VERSION ""

NS_ :

BS_:

BU_: CVC_C EPS WCBS FCAM_C ADCU_C DUMMY_ECU

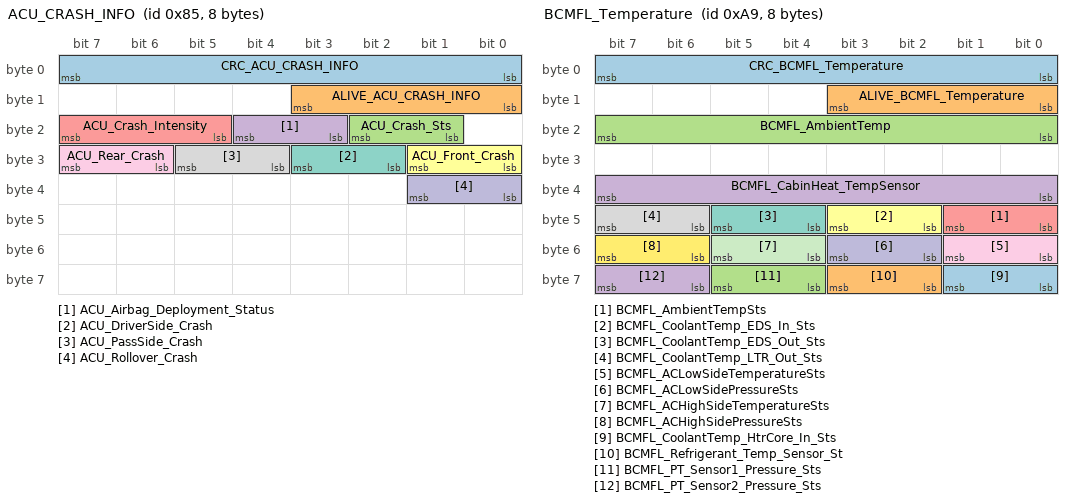
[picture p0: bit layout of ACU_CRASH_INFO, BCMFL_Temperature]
BO_ 133 ACU_CRASH_INFO: 8 CVC_C
 SG_ CRC_ACU_CRASH_INFO : 7|8@0+ (1,0) [0|255] ""  EPS,WCBS
 SG_ ALIVE_ACU_CRASH_INFO : 11|4@0+ (1,0) [0|15] ""  EPS,WCBS
 SG_ ACU_Crash_Sts : 18|2@0+ (1,0) [0|3] ""  EPS,WCBS
 SG_ ACU_Airbag_Deployment_Status : 20|2@0+ (1,0) [0|3] ""  EPS,WCBS
 SG_ ACU_Crash_Intensity : 23|3@0+ (1,0) [0|7] ""  EPS,WCBS
 SG_ ACU_Front_Crash : 25|2@0+ (1,0) [0|3] ""  EPS,WCBS
 SG_ ACU_DriverSide_Crash : 27|2@0+ (1,0) [0|3] ""  EPS,WCBS
 SG_ ACU_PassSide_Crash : 29|2@0+ (1,0) [0|3] ""  EPS,WCBS
 SG_ ACU_Rear_Crash : 31|2@0+ (1,0) [0|3] ""  EPS,WCBS
 SG_ ACU_Rollover_Crash : 33|2@0+ (1,0) [0|3] ""  EPS,WCBS

BO_ 169 BCMFL_Temperature: 8 CVC_C
 SG_ CRC_BCMFL_Temperature : 7|8@0+ (1,0) [0|255] ""  EPS,WCBS
 SG_ ALIVE_BCMFL_Temperature : 11|4@0+ (1,0) [0|15] ""  EPS,WCBS
 SG_ BCMFL_AmbientTemp : 23|8@0+ (0.5,-40) [-40|85] "Degree C"  EPS,WCBS
 SG_ BCMFL_CabinHeat_TempSensor : 39|8@0+ (0.5,-40) [-40|85] "Degree C"  EPS,WCBS
 SG_ BCMFL_AmbientTempSts : 41|2@0+ (1,0) [0|3] ""  EPS,WCBS
 SG_ BCMFL_CoolantTemp_EDS_In_Sts : 43|2@0+ (1,0) [0|3] ""  EPS,WCBS
 SG_ BCMFL_CoolantTemp_EDS_Out_Sts : 45|2@0+ (1,0) [0|3] ""  EPS,WCBS
 SG_ BCMFL_CoolantTemp_LTR_Out_Sts : 47|2@0+ (1,0) [0|3] ""  EPS,WCBS
 SG_ BCMFL_ACLowSideTemperatureSts : 49|2@0+ (1,0) [0|3] ""  EPS,WCBS
 SG_ BCMFL_ACLowSidePressureSts : 51|2@0+ (1,0) [0|3] ""  EPS,WCBS
 SG_ BCMFL_ACHighSideTemperatureSts : 53|2@0+ (1,0) [0|3] ""  EPS,WCBS
 SG_ BCMFL_ACHighSidePressureSts : 55|2@0+ (1,0) [0|3] ""  EPS,WCBS
 SG_ BCMFL_CoolantTemp_HtrCore_In_Sts : 57|2@0+ (1,0) [0|3] ""  EPS,WCBS
 SG_ BCMFL_Refrigerant_Temp_Sensor_St : 59|2@0+ (1,0) [0|3] ""  EPS,WCBS
 SG_ BCMFL_PT_Sensor1_Pressure_Sts : 61|2@0+ (1,0) [0|3] ""  EPS,WCBS
 SG_ BCMFL_PT_Sensor2_Pressure_Sts : 63|2@0+ (1,0) [0|3] ""  EPS,WCBS

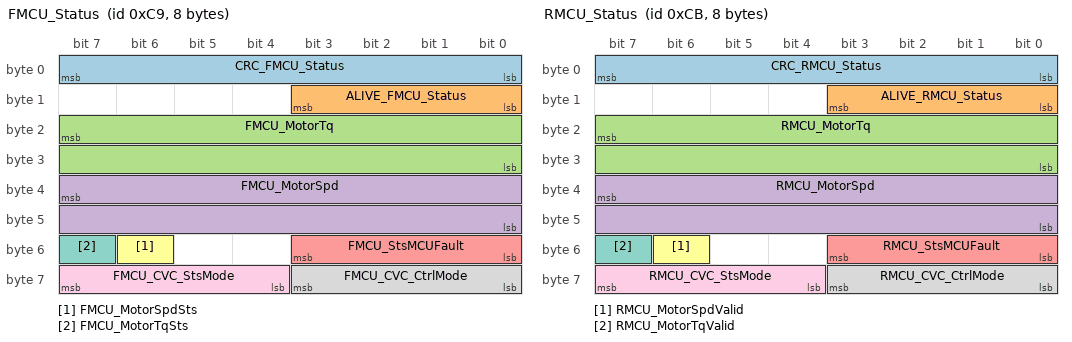
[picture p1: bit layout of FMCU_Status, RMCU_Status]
BO_ 201 FMCU_Status: 8 CVC_C
 SG_ CRC_FMCU_Status : 7|8@0+ (1,0) [0|255] ""  EPS,WCBS
 SG_ ALIVE_FMCU_Status : 11|4@0+ (1,0) [0|15] ""  EPS,WCBS
 SG_ FMCU_MotorTq : 23|16@0+ (0.1,-400) [-400|400] "Nm"  EPS,WCBS
 SG_ FMCU_MotorSpd : 39|16@0+ (1,-20000) [-20000|45531] "rpm"  EPS,WCBS
 SG_ FMCU_StsMCUFault : 51|4@0+ (1,0) [0|15] ""  EPS,WCBS
 SG_ FMCU_MotorSpdSts : 54|1@0+ (1,0) [0|1] ""  EPS,WCBS
 SG_ FMCU_MotorTqSts : 55|1@0+ (1,0) [0|1] ""  EPS,WCBS
 SG_ FMCU_CVC_CtrlMode : 59|4@0+ (1,0) [0|15] ""  EPS,WCBS
 SG_ FMCU_CVC_StsMode : 63|4@0+ (1,0) [0|15] ""  EPS,WCBS

BO_ 202 FMCU_Ability: 12 CVC_C
 SG_ CRC_FMCU_Ability : 7|8@0+ (1,0) [0|255] ""  WCBS
 SG_ ALIVE_FMCU_Ability : 11|4@0+ (1,0) [0|15] ""  WCBS
 SG_ FMCU_CVC_PosTrqLmt : 53|12@0+ (0.1,0) [0|400] ""  WCBS
 SG_ FMCU_CVC_NegTrqLmt : 57|12@0+ (0.1,-400) [-400|0] "Nm"  WCBS
 SG_ FMCU_ActInputCurrent : 31|12@0+ (0.5,-1000) [-1000|1000] "A"  WCBS
 SG_ FMCU_ActInputVolt : 35|12@0+ (0.5,0) [0|1000] "V"  WCBS
 SG_ FMCU_ActInputVoltV : 54|1@0+ (1,0) [0|1] ""  WCBS
 SG_ FMCU_ActInputCurrentV : 55|1@0+ (1,0) [0|1] ""  WCBS

BO_ 203 RMCU_Status: 8 CVC_C
 SG_ CRC_RMCU_Status : 7|8@0+ (1,0) [0|255] ""  EPS,WCBS
 SG_ ALIVE_RMCU_Status : 11|4@0+ (1,0) [0|15] ""  EPS,WCBS
 SG_ RMCU_MotorTq : 23|16@0+ (0.1,-400) [-400|400] "Nm"  EPS,WCBS
 SG_ RMCU_MotorSpd : 39|16@0+ (1,-20000) [-20000|45531] "rpm"  EPS,WCBS
 SG_ RMCU_StsMCUFault : 51|4@0+ (1,0) [0|15] ""  EPS,WCBS
 SG_ RMCU_MotorSpdValid : 54|1@0+ (1,0) [0|1] ""  EPS,WCBS
 SG_ RMCU_MotorTqValid : 55|1@0+ (1,0) [0|1] ""  EPS,WCBS
 SG_ RMCU_CVC_CtrlMode : 59|4@0+ (1,0) [0|15] ""  EPS,WCBS
 SG_ RMCU_CVC_StsMode : 63|4@0+ (1,0) [0|15] ""  EPS,WCBS

BO_ 204 RMCU_Ability: 12 CVC_C
 SG_ CRC_RMCU_Ability : 7|8@0+ (1,0) [0|255] ""  WCBS
 SG_ ALIVE_RMCU_Ability : 11|4@0+ (1,0) [0|15] ""  WCBS
 SG_ RMCU_CVC_PosTrqLmt : 53|12@0+ (0.1,0) [0|400] ""  WCBS
 SG_ RMCU_CVC_NegTrqLmt : 57|12@0+ (0.1,-400) [-400|0] "Nm"  WCBS
 SG_ RMCU_ActInputCurrent : 31|12@0+ (0.5,-1000) [-1000|1000] "A"  WCBS
 SG_ RMCU_ActInputVolt : 35|12@0+ (0.5,0) [0|1000] "V"  WCBS
 SG_ RMCU_ActInputVoltV : 54|1@0+ (1,0) [0|1] ""  WCBS
 SG_ RMCU_ActInputCurrentV : 55|1@0+ (1,0) [0|1] ""  WCBS

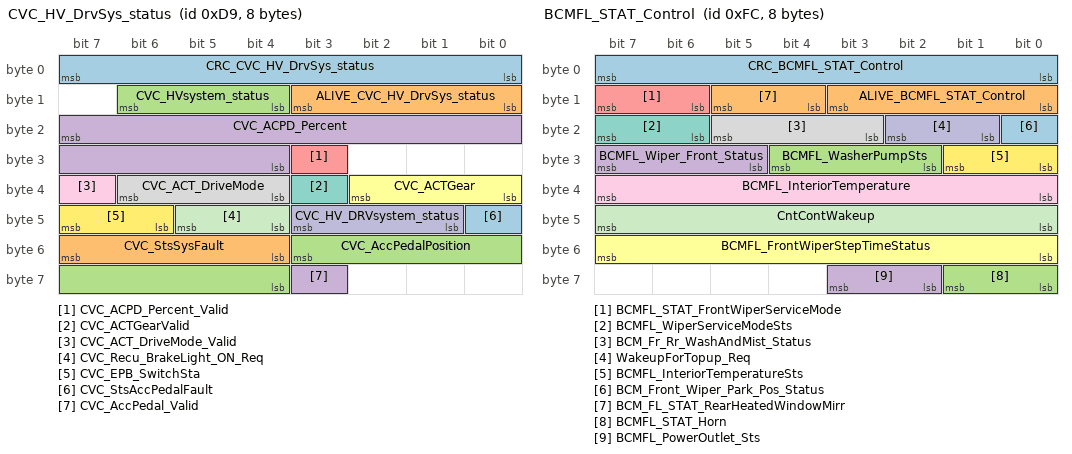
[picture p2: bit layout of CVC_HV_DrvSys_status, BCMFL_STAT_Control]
BO_ 217 CVC_HV_DrvSys_status: 8 CVC_C
 SG_ CRC_CVC_HV_DrvSys_status : 7|8@0+ (1,0) [0|255] ""  EPS,WCBS,FCAM_C,ADCU_C
 SG_ ALIVE_CVC_HV_DrvSys_status : 11|4@0+ (1,0) [0|15] ""  EPS,WCBS,FCAM_C,ADCU_C
 SG_ CVC_HVsystem_status : 14|3@0+ (1,0) [0|7] ""  EPS,WCBS,FCAM_C,ADCU_C
 SG_ CVC_ACPD_Percent : 23|12@0+ (0.0625,0) [0|100] "%"  EPS,WCBS,FCAM_C,ADCU_C
 SG_ CVC_ACPD_Percent_Valid : 27|1@0+ (1,0) [0|1] ""  EPS,WCBS,FCAM_C,ADCU_C
 SG_ CVC_ACTGear : 34|3@0+ (1,0) [0|7] ""  EPS,WCBS,FCAM_C,ADCU_C
 SG_ CVC_ACTGearValid : 35|1@0+ (1,0) [0|1] ""  EPS,WCBS,FCAM_C,ADCU_C
 SG_ CVC_ACT_DriveMode : 38|3@0+ (1,0) [0|7] ""  EPS,WCBS,FCAM_C,ADCU_C
 SG_ CVC_ACT_DriveMode_Valid : 39|1@0+ (1,0) [0|1] ""  EPS,WCBS,FCAM_C,ADCU_C
 SG_ CVC_HV_DRVsystem_status : 43|3@0+ (1,0) [0|7] ""  EPS,WCBS,FCAM_C,ADCU_C
 SG_ CVC_Recu_BrakeLight_ON_Req : 45|2@0+ (1,0) [0|3] ""  EPS,WCBS,FCAM_C,ADCU_C
 SG_ CVC_EPB_SwitchSta : 47|2@0+ (1,0) [0|3] ""  WCBS
 SG_ CVC_StsAccPedalFault : 40|1@0+ (1,0) [0|1] ""  EPS,WCBS,FCAM_C,ADCU_C
 SG_ CVC_StsSysFault : 55|4@0+ (1,0) [0|15] ""  EPS,WCBS,FCAM_C,ADCU_C
 SG_ CVC_AccPedalPosition : 51|8@0+ (0.4,0) [0|100] "%"  ADCU_C
 SG_ CVC_AccPedal_Valid : 59|1@0+ (1,0) [0|1] ""  ADCU_C

BO_ 252 BCMFL_STAT_Control: 8 CVC_C
 SG_ CRC_BCMFL_STAT_Control : 7|8@0+ (1,0) [0|255] ""  WCBS,FCAM_C,ADCU_C
 SG_ ALIVE_BCMFL_STAT_Control : 11|4@0+ (1,0) [0|15] ""  WCBS,FCAM_C,ADCU_C
 SG_ BCMFL_WasherPumpSts : 28|3@0+ (1,0) [0|3] ""  WCBS,FCAM_C,ADCU_C
 SG_ BCMFL_Wiper_Front_Status : 31|3@0+ (1,0) [0|4] ""  WCBS,FCAM_C,ADCU_C
 SG_ BCMFL_STAT_FrontWiperServiceMode : 15|2@0+ (1,0) [0|3] ""  WCBS,FCAM_C,ADCU_C
 SG_ BCMFL_FrontWiperStepTimeStatus : 55|8@0+ (1,0) [0|255] "second"  WCBS,FCAM_C,ADCU_C
 SG_ BCMFL_WiperServiceModeSts : 23|2@0+ (1,0) [0|2] ""  WCBS,FCAM_C,ADCU_C
 SG_ BCM_Fr_Rr_WashAndMist_Status : 21|3@0+ (1,0) [0|7] ""  DUMMY_ECU
 SG_ BCMFL_InteriorTemperature : 39|8@0+ (1,-40) [-40|85] "Degree C"  FCAM_C,ADCU_C
 SG_ WakeupForTopup_Req : 18|2@0+ (1,0) [0|3] ""  DUMMY_ECU
 SG_ CntContWakeup : 47|8@0+ (1,0) [0|255] ""  DUMMY_ECU
 SG_ BCMFL_InteriorTemperatureSts : 25|2@0+ (1,0) [0|3] ""  FCAM_C,ADCU_C
 SG_ BCM_Front_Wiper_Park_Pos_Status : 16|1@0+ (1,0) [0|1] "" Vector__XXX
 SG_ BCM_FL_STAT_RearHeatedWindowMirr : 13|2@0+ (1,0) [0|3] "" Vector__XXX
 SG_ BCMFL_STAT_Horn : 57|2@0+ (1,0) [0|3] "" Vector__XXX
 SG_ BCMFL_PowerOutlet_Sts : 59|2@0+ (1,0) [0|3] "" Vector__XXX

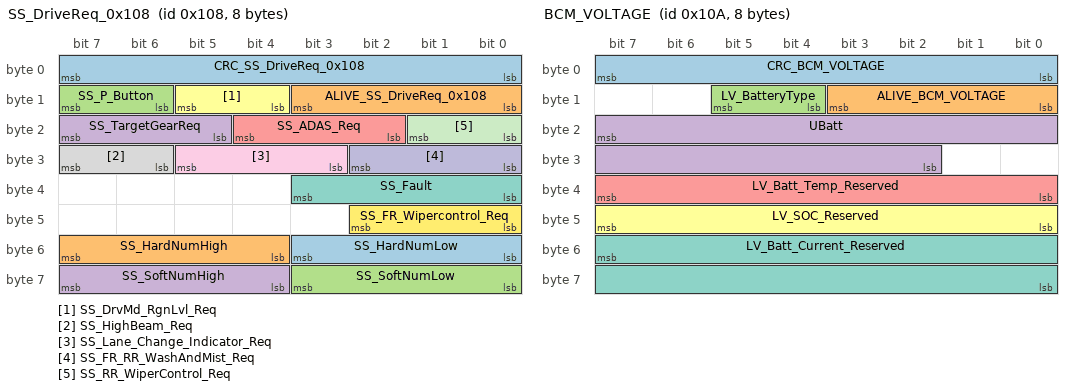
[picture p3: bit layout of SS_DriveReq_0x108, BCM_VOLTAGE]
BO_ 264 SS_DriveReq_0x108: 8 CVC_C
 SG_ CRC_SS_DriveReq_0x108 : 7|8@0+ (1,0) [0|255] ""  WCBS,FCAM_C,ADCU_C
 SG_ ALIVE_SS_DriveReq_0x108 : 11|4@0+ (1,0) [0|15] ""  WCBS,FCAM_C,ADCU_C
 SG_ SS_P_Button : 15|2@0+ (1,0) [0|3] ""  WCBS
 SG_ SS_TargetGearReq : 23|3@0+ (1,0) [0|7] ""  FCAM_C,ADCU_C
 SG_ SS_ADAS_Req : 20|3@0+ (1,0) [0|7] ""  FCAM_C,ADCU_C
 SG_ SS_DrvMd_RgnLvl_Req : 13|2@0+ (1,0) [0|3] ""  DUMMY_ECU
 SG_ SS_Fault : 35|4@0+ (1,0) [0|15] ""  WCBS,FCAM_C,ADCU_C
 SG_ SS_HighBeam_Req : 31|2@0+ (1,0) [0|3] ""  DUMMY_ECU
 SG_ SS_Lane_Change_Indicator_Req : 29|3@0+ (1,0) [0|7] ""  DUMMY_ECU
 SG_ SS_FR_RR_WashAndMist_Req : 26|3@0+ (1,0) [0|7] ""  DUMMY_ECU
 SG_ SS_RR_WiperControl_Req : 17|2@0+ (1,0) [0|3] ""  DUMMY_ECU
 SG_ SS_FR_Wipercontrol_Req : 42|3@0+ (1,0) [0|7] ""  DUMMY_ECU
 SG_ SS_HardNumLow : 51|4@0+ (1,0) [0|15] ""  DUMMY_ECU
 SG_ SS_HardNumHigh : 55|4@0+ (1,0) [0|15] ""  DUMMY_ECU
 SG_ SS_SoftNumLow : 59|4@0+ (1,0) [0|15] ""  DUMMY_ECU
 SG_ SS_SoftNumHigh : 63|4@0+ (1,0) [0|15] ""  DUMMY_ECU

BO_ 266 BCM_VOLTAGE: 8 CVC_C
 SG_ CRC_BCM_VOLTAGE : 7|8@0+ (1,0) [0|255] ""  EPS,WCBS,ADCU_C
 SG_ ALIVE_BCM_VOLTAGE : 11|4@0+ (1,0) [0|15] ""  EPS,WCBS,ADCU_C
 SG_ LV_BatteryType : 13|2@0+ (1,0) [0|3] ""  EPS,WCBS,ADCU_C
 SG_ UBatt : 23|14@0+ (0.0009777,3) [3|18] "V"  EPS,WCBS,ADCU_C
 SG_ LV_Batt_Temp_Reserved : 39|8@0+ (1,-40) [-40|105] "Degree C"  EPS,WCBS,ADCU_C
 SG_ LV_SOC_Reserved : 47|8@0+ (1,0) [0|100] "%"  EPS,WCBS,ADCU_C
 SG_ LV_Batt_Current_Reserved : 55|16@0+ (0.03125,-1536) [-1536|511.90625] "A"  EPS,WCBS,ADCU_C

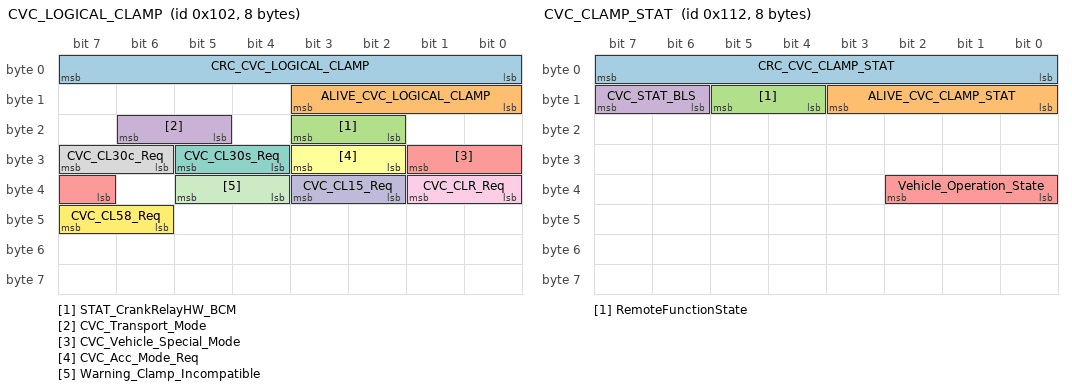
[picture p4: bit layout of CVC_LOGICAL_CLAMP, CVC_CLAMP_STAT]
BO_ 258 CVC_LOGICAL_CLAMP: 8 CVC_C
 SG_ CRC_CVC_LOGICAL_CLAMP : 7|8@0+ (1,0) [0|255] ""  WCBS,DUMMY_ECU
 SG_ ALIVE_CVC_LOGICAL_CLAMP : 11|4@0+ (1,0) [0|15] ""  WCBS,DUMMY_ECU
 SG_ STAT_CrankRelayHW_BCM : 19|2@0+ (1,0) [0|3] ""  DUMMY_ECU
 SG_ CVC_Transport_Mode : 22|2@0+ (1,0) [0|3] ""  DUMMY_ECU
 SG_ CVC_Vehicle_Special_Mode : 25|3@0+ (1,0) [0|7] ""  WCBS,DUMMY_ECU
 SG_ CVC_Acc_Mode_Req : 27|2@0+ (1,0) [0|3] ""  DUMMY_ECU
 SG_ CVC_CL30s_Req : 29|2@0+ (1,0) [0|3] ""  DUMMY_ECU
 SG_ CVC_CL30c_Req : 31|2@0+ (1,0) [0|3] ""  DUMMY_ECU
 SG_ CVC_CLR_Req : 33|2@0+ (1,0) [0|3] ""  DUMMY_ECU
 SG_ CVC_CL15_Req : 35|2@0+ (1,0) [0|3] ""  DUMMY_ECU
 SG_ Warning_Clamp_Incompatible : 37|2@0+ (1,0) [0|3] ""  DUMMY_ECU
 SG_ CVC_CL58_Req : 47|2@0+ (1,0) [0|3] ""  DUMMY_ECU

BO_ 273 CVC_WCBS01: 12 CVC_C
 SG_ CRC_CVC_WCBS01 : 7|8@0+ (1,0) [0|255] ""  WCBS
 SG_ ALIVE_CVC_WCBS01 : 11|4@0+ (1,0) [0|15] ""  WCBS
 SG_ CVC_F_RegenTrqMax : 23|12@0+ (1,-4000) [-4000|0] "Nm"  WCBS
 SG_ CVC_F_RegenTrqMaxValid : 12|1@0+ (1,0) [0|1] ""  WCBS
 SG_ CVC_R_RegenTrqMax : 27|12@0+ (1,-4000) [-4000|0] "Nm"  WCBS
 SG_ CVC_R_RegenTrqMaxValid : 13|1@0+ (1,0) [0|1] ""  WCBS
 SG_ CVC_F_BrkRegenTrqActual : 47|12@0+ (1,-4000) [-4000|0] "Nm"  WCBS
 SG_ CVC_R_BrkRegenTrqActual : 51|12@0+ (1,-4000) [-4000|0] "Nm"  WCBS
 SG_ CVC_F_BrkRegenTrqActualValid : 14|1@0+ (1,0) [0|1] ""  WCBS
 SG_ CVC_R_BrkRegenTrqActualValid : 15|1@0+ (1,0) [0|1] ""  WCBS
 SG_ CVC_OnePedalModeSts : 69|2@0+ (1,0) [0|3] ""  WCBS
 SG_ CVC_OnePedalModeEnable : 71|2@0+ (1,0) [0|3] ""  WCBS
 SG_ CVC_TargetBrkTq : 67|12@0+ (1,0) [0|4000] "Nm"  WCBS
 SG_ CVC_OnePedal_Standstill_Req : 80|1@0+ (1,0) [0|1] ""  WCBS

BO_ 274 CVC_CLAMP_STAT: 8 CVC_C
 SG_ CRC_CVC_CLAMP_STAT : 7|8@0+ (1,0) [0|255] ""  EPS,WCBS,FCAM_C,ADCU_C
 SG_ ALIVE_CVC_CLAMP_STAT : 11|4@0+ (1,0) [0|15] ""  EPS,WCBS,FCAM_C,ADCU_C
 SG_ RemoteFunctionState : 13|2@0+ (1,0) [0|3] ""  EPS,WCBS,FCAM_C,ADCU_C
 SG_ CVC_STAT_BLS : 15|2@0+ (1,0) [0|3] ""  EPS,WCBS,FCAM_C,ADCU_C
 SG_ Vehicle_Operation_State : 34|3@0+ (1,0) [0|7] ""  EPS,WCBS,FCAM_C,ADCU_C

BO_ 288 CVC_WCBS02: 12 CVC_C
 SG_ CRC_CVC_WCBS02 : 7|8@0+ (1,0) [0|255] ""  WCBS,FCAM_C,ADCU_C
 SG_ ALIVE_CVC_WCBS02 : 11|4@0+ (1,0) [0|15] ""  WCBS,FCAM_C,ADCU_C
 SG_ VrAccPos : 23|8@0+ (0.4,0) [0|100] "%"  WCBS,FCAM_C,ADCU_C
 SG_ AccPosTrq : 31|13@0+ (1,-3700) [-3700|4300] "Nm"  WCBS,FCAM_C,ADCU_C
 SG_ CVC_F_TrqCurrWhlValid : 12|1@0+ (1,0) [0|1] ""  WCBS,FCAM_C,ADCU_C
 SG_ CVC_R_TrqCurrWhlValid : 14|1@0+ (1,0) [0|1] ""  WCBS,FCAM_C,ADCU_C
 SG_ CVC_F_TrqCurrWhl : 34|13@0+ (1,-3700) [-3700|4300] "Nm"  WCBS,FCAM_C,ADCU_C
 SG_ CVC_R_TrqCurrWhl : 52|13@0+ (1,-3700) [-3700|4300] "Nm"  WCBS,FCAM_C,ADCU_C
 SG_ Driver_Accel_Pedal_Override : 71|2@0+ (1,0) [0|3] ""  WCBS,FCAM_C,ADCU_C
 SG_ CVC_F_AxleCoastRegenTorque : 67|12@0+ (1,-4000) [-4000|0] ""  WCBS,ADCU_C
 SG_ CVC_F_AxleCoastRegenTorqueValid : 68|1@0+ (1,0) [0|1] ""  WCBS,ADCU_C
 SG_ CVC_R_AxleCoastRegenTorque : 87|12@0+ (1,-4000) [-4000|0] ""  WCBS,ADCU_C
 SG_ CVC_R_AxleCoastRegenTorqueValid : 69|1@0+ (1,0) [0|1] ""  WCBS,ADCU_C

BO_ 358 CVC_Status: 12 CVC_C
 SG_ CRC_CVC_Status : 7|8@0+ (1,0) [0|255] ""  WCBS,FCAM_C,ADCU_C
 SG_ ALIVE_CVC_Status : 11|4@0+ (1,0) [0|15] ""  WCBS,FCAM_C,ADCU_C
 SG_ CVC_DriveModeSts : 18|3@0+ (1,0) [0|7] ""  WCBS,FCAM_C,ADCU_C
 SG_ CVC_DriveReady : 19|1@0+ (1,0) [0|1] ""  WCBS,FCAM_C,ADCU_C
 SG_ CVC_Fault : 22|3@0+ (1,0) [0|7] ""  WCBS,FCAM_C,ADCU_C
 SG_ CVC_VecFltInd : 23|1@0+ (1,0) [0|1] ""  WCBS,FCAM_C,ADCU_C
 SG_ CVC_Creep_Sts : 25|2@0+ (1,0) [0|3] ""  WCBS,FCAM_C,ADCU_C
 SG_ CVC_CruiseCtrlSts : 55|3@0+ (1,0) [0|7] ""  WCBS,FCAM_C,ADCU_C
 SG_ CVC_StsBrakePedalSwitch : 29|2@0+ (1,0) [0|3] ""  WCBS,FCAM_C,ADCU_C
 SG_ CVC_VehicleMode : 31|2@0+ (1,0) [0|3] ""  WCBS,FCAM_C,ADCU_C
 SG_ CVC_CruiseSetSpd : 39|8@0+ (1,0) [30|120] ""  WCBS,FCAM_C,ADCU_C
 SG_ CVC_CruiseFaultIndication : 41|2@0+ (1,0) [0|3] ""  WCBS,FCAM_C,ADCU_C
 SG_ TRMFitted : 13|2@0+ (1,0) [0|3] ""  WCBS,FCAM_C,ADCU_C
 SG_ CVC_FuelDetectionSwitchState : 43|2@0+ (1,0) [0|3] ""  WCBS,FCAM_C,ADCU_C
 SG_ CVC_FuelDetectionState : 45|2@0+ (1,0) [0|3] ""  WCBS,FCAM_C,ADCU_C
 SG_ CVC_ParkingChargeRequest : 47|2@0+ (1,0) [0|3] ""  WCBS,FCAM_C,ADCU_C
 SG_ CVC_ParkingChargeModeSet : 51|2@0+ (1,0) [0|3] ""  WCBS,FCAM_C,ADCU_C
 SG_ CVC_REX_StartTimer : 49|10@0+ (1,0) [0|1023] "s"  WCBS,FCAM_C,ADCU_C
 SG_ LV_EM_Rampup_Req : 15|2@0+ (1,0) [0|3] ""  DUMMY_ECU
 SG_ LV_PowerSupply_Status : 52|1@0+ (1,0) [0|1] ""  DUMMY_ECU
 SG_ LV_EM_OTA_Req : 27|2@0+ (1,0) [0|3] ""  DUMMY_ECU
 SG_ CVC_STAT_AirDistributionModeLH : 71|3@0+ (1,0) [0|7] ""  DUMMY_ECU
 SG_ CVC_STAT_AirDistributionModeRH : 68|3@0+ (1,0) [0|7] ""  DUMMY_ECU
 SG_ CVC_STAT_DriverOnly : 65|2@0+ (1,0) [0|3] ""  DUMMY_ECU

BO_ 524 CVC_ODO: 8 CVC_C
 SG_ CRC_CVC_ODO : 7|8@0+ (1,0) [0|255] ""  EPS,WCBS
 SG_ ALIVE_CVC_ODO : 11|4@0+ (1,0) [0|15] ""  EPS,WCBS
 SG_ CVC_Odometer : 23|20@0+ (1,0) [0|999999] "km"  EPS,WCBS
 SG_ CVC_OdometerV : 35|1@0+ (1,0) [0|1] ""  EPS,WCBS

BO_ 533 BMS_Sts: 16 CVC_C
 SG_ CRC_BMS_Sts : 7|8@0+ (1,0) [0|255] ""  WCBS
 SG_ ALIVE_BMS_Sts : 11|4@0+ (1,0) [0|15] ""  WCBS
 SG_ BMS_BatBalance_ERR : 12|1@0+ (1,0) [0|1] ""  WCBS
 SG_ BMS_Balance_STS : 13|1@0+ (1,0) [0|1] ""  WCBS
 SG_ BMS_IGN_Sts : 14|1@0+ (1,0) [0|1] ""  WCBS
 SG_ BMS_HWCrash_Sts : 15|1@0+ (1,0) [0|1] ""  WCBS
 SG_ BMS_HVIL_STS : 17|2@0+ (1,0) [0|3] ""  WCBS
 SG_ BMS_HVOnOff_STS : 19|2@0+ (1,0) [0|3] ""  WCBS
 SG_ BMS_ERR_LEV : 23|4@0+ (1,0) [0|7] ""  WCBS
 SG_ BMS_SocActual_EST : 25|10@0+ (0.1,0) [0|100] "%"  WCBS
 SG_ BMS_Sys_STS : 29|4@0+ (1,0) [0|15] ""  WCBS
 SG_ BMS_ISU_Status : 31|2@0+ (1,0) [0|3] ""  WCBS
 SG_ BMS_SOH : 47|8@0+ (0.5,0) [0|100] "%"  WCBS
 SG_ BMS_SOE : 55|8@0+ (0.5,0) [0|100] "%"  WCBS
 SG_ BMS_HV_Sts : 63|8@0+ (1,0) [0|255] ""  WCBS
 SG_ BMS_Display_SOC : 71|10@0+ (0.1,0) [0|100] "%" Vector__XXX
 SG_ BMS_SOCE : 87|14@0+ (0.01,0) [0|100] "%" Vector__XXX

BO_ 618 CVC_HV_Status: 2 CVC_C
 SG_ CRC_CVC_HV_Status : 7|8@0+ (1,0) [0|255] ""  EPS,FCAM_C,ADCU_C
 SG_ ALIVE_CVC_HV_Status : 11|4@0+ (1,0) [0|15] ""  EPS,FCAM_C,ADCU_C
 SG_ CVC_VehicleHVStatus : 15|2@0+ (1,0) [0|3] ""  EPS,FCAM_C,ADCU_C

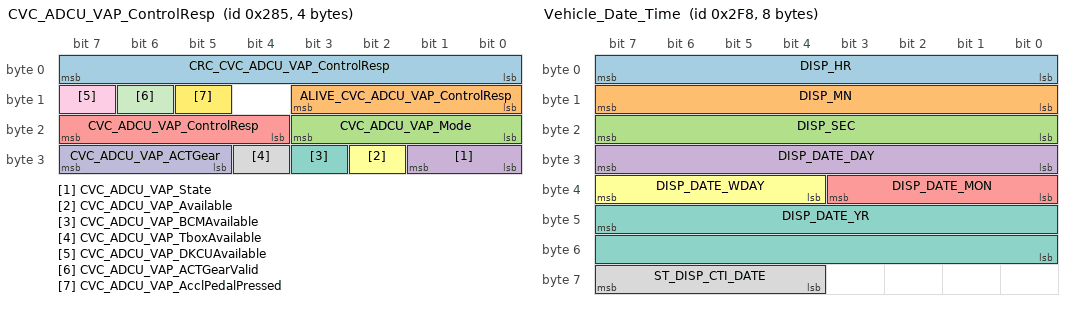
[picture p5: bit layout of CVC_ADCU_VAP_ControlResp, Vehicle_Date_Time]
BO_ 645 CVC_ADCU_VAP_ControlResp: 4 CVC_C
 SG_ CRC_CVC_ADCU_VAP_ControlResp : 7|8@0+ (1,0) [0|255] ""  ADCU_C
 SG_ ALIVE_CVC_ADCU_VAP_ControlResp : 11|4@0+ (1,0) [0|15] ""  ADCU_C
 SG_ CVC_ADCU_VAP_Mode : 19|4@0+ (1,0) [0|15] ""  ADCU_C
 SG_ CVC_ADCU_VAP_State : 25|2@0+ (1,0) [0|3] ""  ADCU_C
 SG_ CVC_ADCU_VAP_ControlResp : 23|4@0+ (1,0) [0|15] ""  ADCU_C
 SG_ CVC_ADCU_VAP_Available : 26|1@0+ (1,0) [0|1] ""  ADCU_C
 SG_ CVC_ADCU_VAP_BCMAvailable : 27|1@0+ (1,0) [0|1] ""  ADCU_C
 SG_ CVC_ADCU_VAP_TboxAvailable : 28|1@0+ (1,0) [0|1] ""  ADCU_C
 SG_ CVC_ADCU_VAP_DKCUAvailable : 15|1@0+ (1,0) [0|1] ""  ADCU_C
 SG_ CVC_ADCU_VAP_ACTGear : 31|3@0+ (1,0) [0|7] ""  ADCU_C
 SG_ CVC_ADCU_VAP_ACTGearValid : 14|1@0+ (1,0) [0|1] ""  ADCU_C
 SG_ CVC_ADCU_VAP_AcclPedalPressed : 13|1@0+ (1,0) [0|1] ""  ADCU_C

BO_ 760 Vehicle_Date_Time: 8 CVC_C
 SG_ DISP_HR : 7|8@0+ (1,0) [0|23] "h"  EPS,WCBS
 SG_ DISP_MN : 15|8@0+ (1,0) [0|59] "min"  EPS,WCBS
 SG_ DISP_SEC : 23|8@0+ (1,0) [0|59] "s"  EPS,WCBS
 SG_ DISP_DATE_DAY : 31|8@0+ (1,0) [1|31] "Day"  EPS,WCBS
 SG_ DISP_DATE_MON : 35|4@0+ (1,0) [1|12] "Month"  EPS,WCBS
 SG_ DISP_DATE_WDAY : 39|4@0+ (1,0) [0|15] ""  EPS,WCBS
 SG_ DISP_DATE_YR : 47|16@0+ (1,0) [1|65534] "Year"  EPS,WCBS
 SG_ ST_DISP_CTI_DATE : 63|4@0+ (1,0) [0|15] ""  EPS,WCBS

BO_ 788 MHU_RAEB: 24 CVC_C
 SG_ CRC_MHU_RAEB : 7|8@0+ (1,0) [0|255] ""  WCBS
 SG_ ALIVE_MHU_RAEB : 11|4@0+ (1,0) [0|15] ""  WCBS
 SG_ MHU_RAEB_check : 15|3@0+ (1,0) [0|7] ""  WCBS
 SG_ MHU_RAEB_Warning : 30|3@0+ (1,0) [0|7] ""  WCBS
 SG_ MHU_RAEB_State : 27|4@0+ (1,0) [0|15] ""  WCBS
 SG_ MHU_RAEB_BrakeCommand : 23|3@0+ (1,0) [0|3] ""  WCBS
 SG_ MHU_RAEB_Available : 17|2@0+ (1,0) [0|3] ""  WCBS
 SG_ MHU_RAEB_FuncActive : 20|1@0+ (1,0) [0|1] ""  WCBS
 SG_ MHU_RAEB_Mode_Feed : 19|2@0+ (1,0) [0|3] ""  WCBS
 SG_ MHU_RAEB_BrakeType : 33|2@0+ (1,0) [0|3] ""  WCBS
 SG_ MHU_RAEB_PullEPBOpt : 31|1@0+ (1,0) [0|1] ""  WCBS
 SG_ Secure_ResetCnt_0x314 : 135|16@0+ (1,0) [0|65535] ""  WCBS
 SG_ Secure_MsgCnt_0x314 : 151|16@0+ (1,0) [0|65535] ""  WCBS
 SG_ Secure_MAC_0x314 : 167|32@0+ (1,0) [0|4294967295] ""  WCBS
 SG_ MHU_RAEB_BrakeReq_Source : 36|3@0+ (1,0) [0|7] ""  DUMMY_ECU

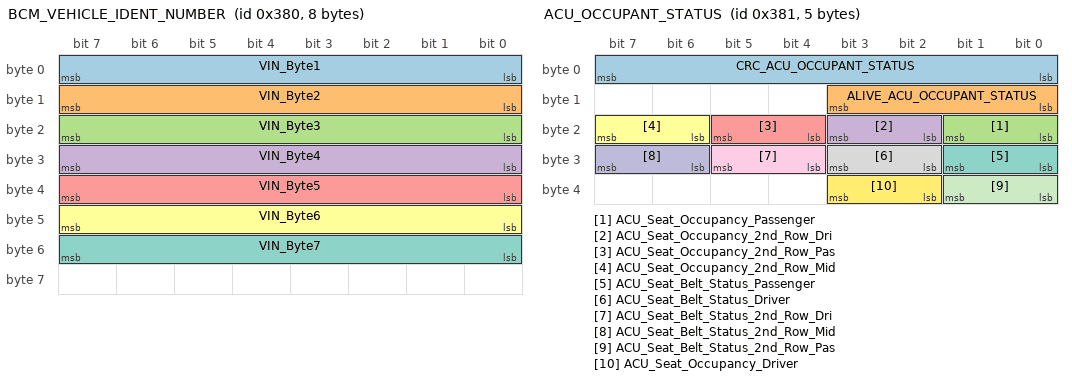
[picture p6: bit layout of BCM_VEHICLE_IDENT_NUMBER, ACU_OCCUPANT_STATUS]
BO_ 896 BCM_VEHICLE_IDENT_NUMBER: 8 CVC_C
 SG_ VIN_Byte1 : 7|8@0+ (1,0) [0|255] ""  EPS,WCBS
 SG_ VIN_Byte2 : 15|8@0+ (1,0) [0|255] ""  EPS,WCBS
 SG_ VIN_Byte3 : 23|8@0+ (1,0) [0|255] ""  EPS,WCBS
 SG_ VIN_Byte4 : 31|8@0+ (1,0) [0|255] ""  EPS,WCBS
 SG_ VIN_Byte5 : 39|8@0+ (1,0) [0|255] ""  EPS,WCBS
 SG_ VIN_Byte6 : 47|8@0+ (1,0) [0|255] ""  EPS,WCBS
 SG_ VIN_Byte7 : 55|8@0+ (1,0) [0|255] ""  EPS,WCBS

BO_ 897 ACU_OCCUPANT_STATUS: 5 CVC_C
 SG_ CRC_ACU_OCCUPANT_STATUS : 7|8@0+ (1,0) [0|255] ""  WCBS
 SG_ ALIVE_ACU_OCCUPANT_STATUS : 11|4@0+ (1,0) [0|15] ""  WCBS
 SG_ ACU_Seat_Occupancy_Passenger : 17|2@0+ (1,0) [0|3] ""  WCBS
 SG_ ACU_Seat_Occupancy_2nd_Row_Dri : 19|2@0+ (1,0) [0|3] ""  WCBS
 SG_ ACU_Seat_Occupancy_2nd_Row_Pas : 21|2@0+ (1,0) [0|3] ""  WCBS
 SG_ ACU_Seat_Occupancy_2nd_Row_Mid : 23|2@0+ (1,0) [0|3] ""  WCBS
 SG_ ACU_Seat_Belt_Status_Passenger : 25|2@0+ (1,0) [0|3] ""  WCBS
 SG_ ACU_Seat_Belt_Status_Driver : 27|2@0+ (1,0) [0|3] ""  WCBS
 SG_ ACU_Seat_Belt_Status_2nd_Row_Dri : 29|2@0+ (1,0) [0|3] ""  WCBS
 SG_ ACU_Seat_Belt_Status_2nd_Row_Mid : 31|2@0+ (1,0) [0|3] ""  WCBS
 SG_ ACU_Seat_Belt_Status_2nd_Row_Pas : 33|2@0+ (1,0) [0|3] ""  WCBS
 SG_ ACU_Seat_Occupancy_Driver : 35|2@0+ (1,0) [0|3] ""  WCBS

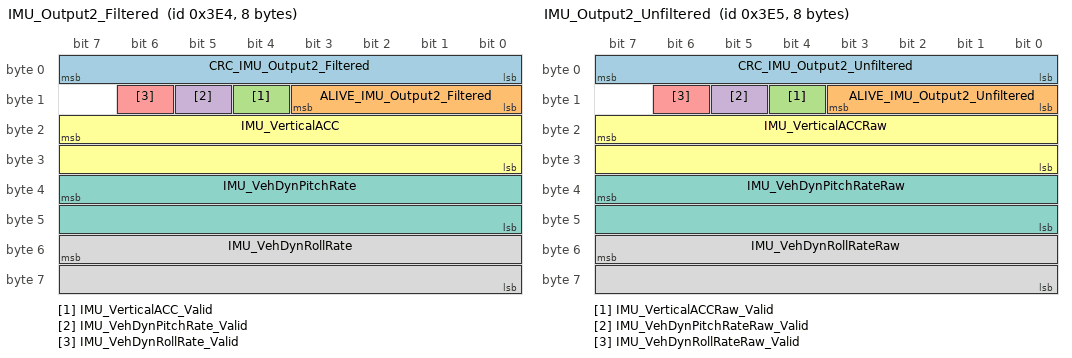
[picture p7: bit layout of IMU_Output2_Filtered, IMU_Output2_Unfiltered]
BO_ 996 IMU_Output2_Filtered: 8 CVC_C
 SG_ CRC_IMU_Output2_Filtered : 7|8@0+ (1,0) [0|255] ""  FCAM_C,ADCU_C
 SG_ ALIVE_IMU_Output2_Filtered : 11|4@0+ (1,0) [0|15] ""  FCAM_C,ADCU_C
 SG_ IMU_VerticalACC_Valid : 12|1@0+ (1,0) [0|1] ""  FCAM_C,ADCU_C
 SG_ IMU_VehDynPitchRate_Valid : 13|1@0+ (1,0) [0|1] ""  FCAM_C,ADCU_C
 SG_ IMU_VehDynRollRate_Valid : 14|1@0+ (1,0) [0|1] ""  FCAM_C,ADCU_C
 SG_ IMU_VerticalACC : 23|16@0+ (0.002,-60) [-60|60] "m/s2"  FCAM_C,ADCU_C
 SG_ IMU_VehDynPitchRate : 39|16@0+ (0.01,-300) [-300|300] "deg/s"  FCAM_C,ADCU_C
 SG_ IMU_VehDynRollRate : 55|16@0+ (0.01,-300) [-300|300] "deg/s"  FCAM_C,ADCU_C

BO_ 997 IMU_Output2_Unfiltered: 8 CVC_C
 SG_ CRC_IMU_Output2_Unfiltered : 7|8@0+ (1,0) [0|255] ""  FCAM_C,ADCU_C
 SG_ ALIVE_IMU_Output2_Unfiltered : 11|4@0+ (1,0) [0|15] ""  FCAM_C,ADCU_C
 SG_ IMU_VerticalACCRaw_Valid : 12|1@0+ (1,0) [0|1] ""  FCAM_C,ADCU_C
 SG_ IMU_VehDynPitchRateRaw_Valid : 13|1@0+ (1,0) [0|1] ""  FCAM_C,ADCU_C
 SG_ IMU_VehDynRollRateRaw_Valid : 14|1@0+ (1,0) [0|1] ""  FCAM_C,ADCU_C
 SG_ IMU_VerticalACCRaw : 23|16@0+ (0.002,-60) [-60|60] "m/s2"  FCAM_C,ADCU_C
 SG_ IMU_VehDynPitchRateRaw : 39|16@0+ (0.01,-300) [-300|300] "deg/s"  FCAM_C,ADCU_C
 SG_ IMU_VehDynRollRateRaw : 55|16@0+ (0.01,-300) [-300|300] "deg/s"  FCAM_C,ADCU_C

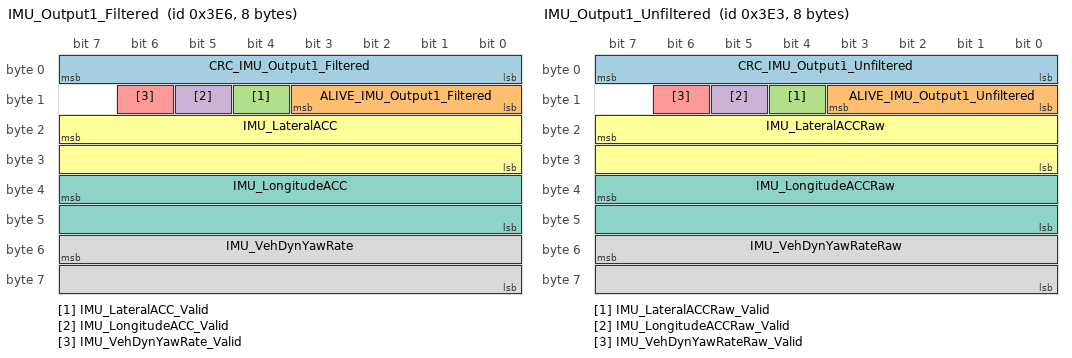
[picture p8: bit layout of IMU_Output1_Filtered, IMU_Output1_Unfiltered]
BO_ 998 IMU_Output1_Filtered: 8 CVC_C
 SG_ CRC_IMU_Output1_Filtered : 7|8@0+ (1,0) [0|255] ""  FCAM_C,ADCU_C
 SG_ ALIVE_IMU_Output1_Filtered : 11|4@0+ (1,0) [0|15] ""  FCAM_C,ADCU_C
 SG_ IMU_LateralACC_Valid : 12|1@0+ (1,0) [0|1] ""  FCAM_C,ADCU_C
 SG_ IMU_LongitudeACC_Valid : 13|1@0+ (1,0) [0|1] ""  FCAM_C,ADCU_C
 SG_ IMU_VehDynYawRate_Valid : 14|1@0+ (1,0) [0|1] ""  FCAM_C,ADCU_C
 SG_ IMU_LateralACC : 23|16@0+ (0.005,-60) [-60|60] "m/s2"  FCAM_C,ADCU_C
 SG_ IMU_LongitudeACC : 39|16@0+ (0.005,-60) [-60|60] "m/s2"  FCAM_C,ADCU_C
 SG_ IMU_VehDynYawRate : 55|16@0+ (0.02,-300) [-300|300] "deg/s"  FCAM_C,ADCU_C

BO_ 995 IMU_Output1_Unfiltered: 8 CVC_C
 SG_ CRC_IMU_Output1_Unfiltered : 7|8@0+ (1,0) [0|255] ""  FCAM_C,ADCU_C
 SG_ ALIVE_IMU_Output1_Unfiltered : 11|4@0+ (1,0) [0|15] ""  FCAM_C,ADCU_C
 SG_ IMU_LateralACCRaw_Valid : 12|1@0+ (1,0) [0|1] ""  FCAM_C,ADCU_C
 SG_ IMU_LongitudeACCRaw_Valid : 13|1@0+ (1,0) [0|1] ""  FCAM_C,ADCU_C
 SG_ IMU_VehDynYawRateRaw_Valid : 14|1@0+ (1,0) [0|1] ""  FCAM_C,ADCU_C
 SG_ IMU_LateralACCRaw : 23|16@0+ (0.002,-60) [-60|60] "m/s2"  FCAM_C,ADCU_C
 SG_ IMU_LongitudeACCRaw : 39|16@0+ (0.002,-60) [-60|60] "m/s2"  FCAM_C,ADCU_C
 SG_ IMU_VehDynYawRateRaw : 55|16@0+ (0.01,-300) [-300|300] "deg/s"  FCAM_C,ADCU_C

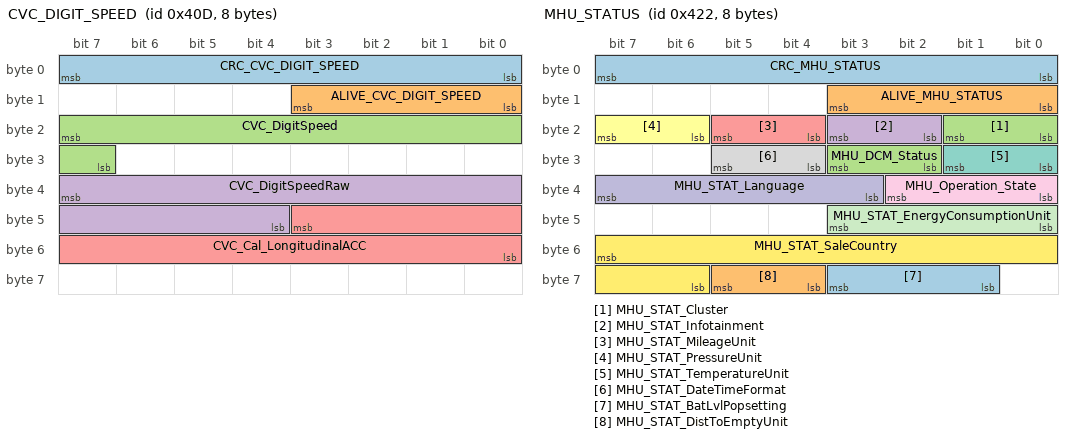
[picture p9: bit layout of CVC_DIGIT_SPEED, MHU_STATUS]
BO_ 1037 CVC_DIGIT_SPEED: 8 CVC_C
 SG_ CRC_CVC_DIGIT_SPEED : 7|8@0+ (1,0) [0|255] ""  WCBS
 SG_ ALIVE_CVC_DIGIT_SPEED : 11|4@0+ (1,0) [0|15] ""  WCBS
 SG_ CVC_DigitSpeed : 23|9@0+ (1,0) [0|300] "km/h"  WCBS
 SG_ CVC_DigitSpeedRaw : 39|12@0+ (0.1,0) [0|300] "km/h"  WCBS
 SG_ CVC_Cal_LongitudinalACC : 43|12@0+ (0.01,-20) [-20|20] "m/s2"  DUMMY_ECU

BO_ 1058 MHU_STATUS: 8 CVC_C
 SG_ CRC_MHU_STATUS : 7|8@0+ (1,0) [0|255] ""  WCBS
 SG_ ALIVE_MHU_STATUS : 11|4@0+ (1,0) [0|15] ""  WCBS
 SG_ MHU_STAT_Cluster : 17|2@0+ (1,0) [0|3] "" Vector__XXX
 SG_ MHU_STAT_Infotainment : 19|2@0+ (1,0) [0|3] "" Vector__XXX
 SG_ MHU_STAT_MileageUnit : 21|2@0+ (1,0) [0|3] ""  WCBS
 SG_ MHU_STAT_PressureUnit : 23|2@0+ (1,0) [0|3] "" Vector__XXX
 SG_ MHU_STAT_TemperatureUnit : 25|2@0+ (1,0) [0|3] "" Vector__XXX
 SG_ MHU_STAT_DateTimeFormat : 29|2@0+ (1,0) [0|3] "" Vector__XXX
 SG_ MHU_Operation_State : 34|3@0+ (1,0) [0|7] "" Vector__XXX
 SG_ MHU_STAT_Language : 39|5@0+ (1,0) [0|31] "" Vector__XXX
 SG_ MHU_STAT_EnergyConsumptionUnit : 43|4@0+ (1,0) [0|15] "" Vector__XXX
 SG_ MHU_STAT_SaleCountry : 55|10@0+ (1,0) [0|1023] "" Vector__XXX
 SG_ MHU_STAT_BatLvlPopsetting : 59|3@0+ (1,0) [0|7] "" Vector__XXX
 SG_ MHU_STAT_DistToEmptyUnit : 61|2@0+ (1,0) [0|3] "" Vector__XXX
 SG_ MHU_DCM_Status : 27|2@0+ (1,0) [0|3] "" Vector__XXX

BO_ 1082 CVC_MHU_info: 8 CVC_C
 SG_ CRC_CVC_MHU_info : 7|8@0+ (1,0) [0|255] ""  WCBS
 SG_ ALIVE_CVC_MHU_info : 11|4@0+ (1,0) [0|15] ""  WCBS
 SG_ CVC_BrakeRegenMode : 13|2@0+ (1,0) [0|3] ""  WCBS
 SG_ CVC_CreepEnable_stt : 14|1@0+ (1,0) [0|1] "" Vector__XXX
 SG_ CVC_PowerRegenGaugeDisplay : 23|8@0+ (1,-100) [-100|100] "%" Vector__XXX
 SG_ CVC_Regen_available : 31|2@0+ (1,0) [0|3] "" Vector__XXX
 SG_ CVC_StoppingMode_stt : 37|3@0+ (1,0) [0|7] "" Vector__XXX
 SG_ CVC_AutoP_Feedback : 39|2@0+ (1,0) [0|3] "" Vector__XXX
 SG_ CVC_SOC_display : 46|10@0+ (0.1,0) [0|100] "%" Vector__XXX
 SG_ CVC_Hvbatt_charging_stt : 58|1@0+ (1,0) [0|1] "" Vector__XXX
 SG_ CVC_PreheatBatt_Sts : 15|1@0+ (1,0) [0|1] ""  DUMMY_ECU
 SG_ CVC_HDC_Status : 34|3@0+ (1,0) [0|7] ""  DUMMY_ECU
 SG_ CVC_STAT_RearAircondition : 52|2@0+ (1,0) [0|3] ""  DUMMY_ECU
 SG_ CVC_STAT_AirDistributionRear : 50|2@0+ (1,0) [0|3] ""  DUMMY_ECU
 SG_ CVC_STAT_RearFanSpeed : 62|4@0+ (1,0) [0|15] ""  DUMMY_ECU
 SG_ CVC_STAT_TempRear : 29|6@0+ (0.5,16) [16|32] "degC"  DUMMY_ECU
 SG_ CVC_STAT_RearAuto : 48|2@0+ (1,0) [0|3] ""  DUMMY_ECU

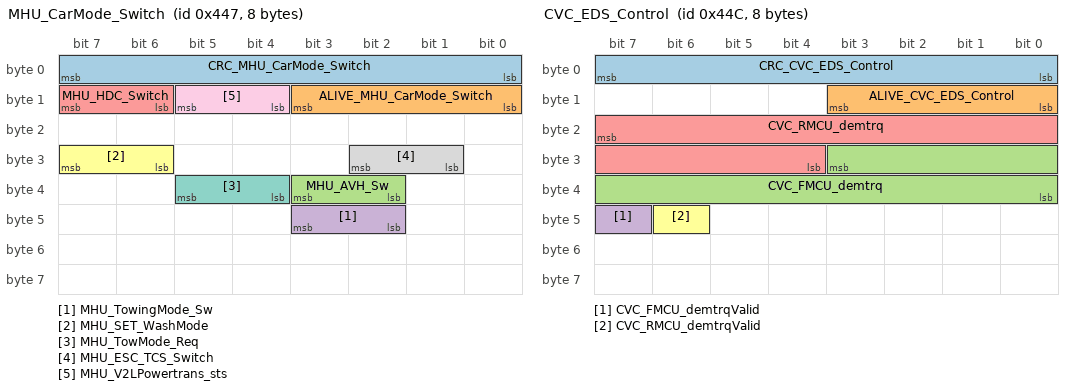
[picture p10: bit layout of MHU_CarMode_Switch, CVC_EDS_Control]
BO_ 1095 MHU_CarMode_Switch: 8 CVC_C
 SG_ CRC_MHU_CarMode_Switch : 7|8@0+ (1,0) [0|255] ""  WCBS,FCAM_C,ADCU_C
 SG_ ALIVE_MHU_CarMode_Switch : 11|4@0+ (1,0) [0|15] ""  WCBS,FCAM_C,ADCU_C
 SG_ MHU_AVH_Sw : 35|2@0+ (1,0) [0|3] ""  WCBS,FCAM_C,ADCU_C
 SG_ MHU_TowingMode_Sw : 43|2@0+ (1,0) [0|3] ""  WCBS,FCAM_C,ADCU_C
 SG_ MHU_HDC_Switch : 15|2@0+ (1,0) [0|3] ""  WCBS,FCAM_C,ADCU_C
 SG_ MHU_SET_WashMode : 31|2@0+ (1,0) [0|3] ""  FCAM_C,ADCU_C
 SG_ MHU_TowMode_Req : 37|2@0+ (1,0) [0|3] ""  WCBS,FCAM_C,ADCU_C
 SG_ MHU_ESC_TCS_Switch : 26|2@0+ (1,0) [0|3] ""  WCBS,ADCU_C
 SG_ MHU_V2LPowertrans_sts : 13|2@0+ (1,0) [0|3] ""  DUMMY_ECU

BO_ 1098 CVC_WCBS_Control: 32 CVC_C
 SG_ CRC_CVC_WCBS_Control : 7|8@0+ (1,0) [0|255] ""  WCBS,ADCU_C
 SG_ ALIVE_CVC_WCBS_Control : 11|4@0+ (1,0) [0|15] ""  WCBS,ADCU_C
 SG_ CVC_WCBS_DrvIntdTorqFr : 43|14@0+ (1,-8000) [-8000|8000] "Nm"  WCBS,ADCU_C
 SG_ CVC_WCBS_DrvIntdTorqRe : 61|14@0+ (1,-8000) [-8000|8000] "Nm"  WCBS,ADCU_C
 SG_ CVC_MaxTorq_Sts_FR : 77|2@0+ (1,0) [0|3] ""  WCBS,ADCU_C
 SG_ CVC_MinTorq_Sts_FR : 79|2@0+ (1,0) [0|3] ""  WCBS,ADCU_C
 SG_ CVC_MaxTorq_RR : 25|14@0+ (1,-8000) [-8000|8000] "Nm"  WCBS,ADCU_C
 SG_ CVC_MaxTorq_Sts_RR : 13|2@0+ (1,0) [0|3] ""  WCBS,ADCU_C
 SG_ CVC_MinTorq_RR : 23|14@0+ (1,-8000) [-8000|8000] "Nm"  WCBS,ADCU_C
 SG_ CVC_MinTorq_Sts_RR : 15|2@0+ (1,0) [0|3] ""  WCBS,ADCU_C
 SG_ CVC_WCBS_VAP_Available_Wheel_Tor : 87|14@0+ (1,-8000) [-8000|8000] "Nm"  WCBS,ADCU_C
 SG_ CVC_WCBS_VAP_ControlResp : 73|1@0+ (1,0) [0|1] ""  WCBS,ADCU_C
 SG_ CVC_WCBS_VAP_Available : 72|1@0+ (1,0) [0|1] ""  WCBS,ADCU_C
 SG_ CVC_MinTorq_FR : 103|14@0+ (1,-8000) [-8000|8000] "Nm"  WCBS,ADCU_C
 SG_ CVC_MaxTorq_FR : 119|14@0+ (1,-8000) [-8000|8000] "Nm"  WCBS,ADCU_C
 SG_ CVC_WCBS_APA_WheelTrq_Res : 89|1@0+ (1,0) [0|1] ""  WCBS,ADCU_C
 SG_ Secure_ResetCnt_0x44A : 135|16@0+ (1,0) [0|65535] ""  WCBS,ADCU_C
 SG_ Secure_MsgCnt_0x44A : 151|16@0+ (1,0) [0|65535] ""  WCBS,ADCU_C
 SG_ Secure_MAC_0x44A : 167|32@0+ (1,0) [0|4294967295] ""  WCBS,ADCU_C
 SG_ CVC_WCBS_VAP_FuncMode : 199|4@0+ (1,0) [0|15] ""  WCBS,ADCU_C

BO_ 1100 CVC_EDS_Control: 8 CVC_C
 SG_ CRC_CVC_EDS_Control : 7|8@0+ (1,0) [0|255] ""  WCBS
 SG_ ALIVE_CVC_EDS_Control : 11|4@0+ (1,0) [0|15] ""  WCBS
 SG_ CVC_FMCU_demtrq : 27|12@0+ (0.5,-500) [-500|500] "Nm"  WCBS
 SG_ CVC_FMCU_demtrqValid : 47|1@0+ (1,0) [0|1] ""  WCBS
 SG_ CVC_RMCU_demtrq : 23|12@0+ (0.5,-500) [-500|500] "Nm"  WCBS
 SG_ CVC_RMCU_demtrqValid : 46|1@0+ (1,0) [0|1] ""  WCBS

BO_ 1118 BCM_Heater_Feedback: 4 CVC_C
 SG_ CRC_BCM_Heater_Feedback : 7|8@0+ (1,0) [0|255] ""  FCAM_C
 SG_ ALIVE_BCM_Heater_Feedback : 11|4@0+ (1,0) [0|15] ""  FCAM_C
 SG_ BCM_HeaterActivation_Feedback : 16|1@0+ (1,0) [0|1] ""  FCAM_C

BO_ 1236 CVC_DoorState: 12 CVC_C
 SG_ Body_CoverAjarStatus : 0|1@0+ (1,0) [0|1] ""  WCBS
 SG_ Body_TrunckAjarStatus : 1|1@0+ (1,0) [0|1] ""  WCBS
 SG_ Body_DriverSideDoorAjarSts : 3|2@0+ (1,0) [0|3] ""  WCBS
 SG_ Body_CodriversSideDoorAjarSts : 5|2@0+ (1,0) [0|3] ""  WCBS
 SG_ Body_RearLeftDoorAjarStatus : 7|2@0+ (1,0) [0|3] ""  WCBS
 SG_ Body_DoorLockStatusRL : 17|2@0+ (1,0) [0|3] ""  WCBS
 SG_ Body_DoorLockStatusRR : 19|2@0+ (1,0) [0|3] ""  WCBS
 SG_ Body_DoorLockStatusCodrivres : 21|2@0+ (1,0) [0|3] ""  WCBS
 SG_ Body_DoorLockStatusDrv : 23|2@0+ (1,0) [0|3] ""  WCBS
 SG_ Body_RearRightDoorAjarStatus : 25|2@0+ (1,0) [0|3] ""  WCBS
 SG_ Body_ATWS_St : 28|3@0+ (1,0) [0|7] ""  WCBS
 SG_ Body_TailGateSts : 31|3@0+ (1,0) [0|7] ""  WCBS
 SG_ Body_ETGLockStatus : 11|2@0+ (1,0) [0|3] ""  WCBS

BO_ 1968 CVC_Synchronization_Master: 8 CVC_C
 SG_ Sync_TripCnt : 7|24@0+ (1,0) [0|16777215] ""  EPS,WCBS,FCAM_C
 SG_ Sync_ResetCnt : 31|16@0+ (1,0) [0|65535] ""  EPS,WCBS,FCAM_C
 SG_ Sync_MAC : 47|24@0+ (1,0) [0|16777215] ""  EPS,WCBS,FCAM_C

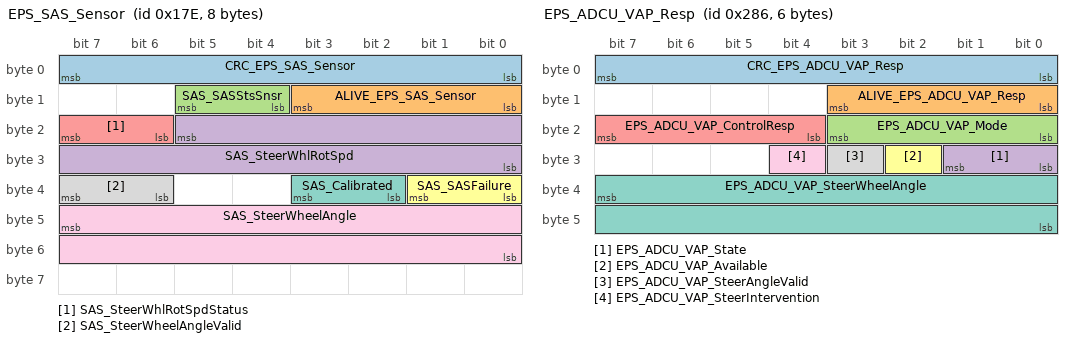
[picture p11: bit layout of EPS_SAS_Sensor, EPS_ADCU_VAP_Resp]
BO_ 382 EPS_SAS_Sensor: 8 EPS
 SG_ CRC_EPS_SAS_Sensor : 7|8@0+ (1,0) [0|255] ""  CVC_C,WCBS,FCAM_C,ADCU_C
 SG_ ALIVE_EPS_SAS_Sensor : 11|4@0+ (1,0) [0|15] ""  CVC_C,WCBS,FCAM_C,ADCU_C
 SG_ SAS_SASStsSnsr : 13|2@0+ (1,0) [0|1] ""  CVC_C,WCBS,FCAM_C,ADCU_C
 SG_ SAS_SteerWhlRotSpd : 21|14@0+ (0.125,-1024) [-1024|1023.88] "degree/s"  CVC_C,WCBS,FCAM_C,ADCU_C
 SG_ SAS_SteerWhlRotSpdStatus : 23|2@0+ (1,0) [0|1] ""  CVC_C,WCBS,FCAM_C,ADCU_C
 SG_ SAS_SASFailure : 33|2@0+ (1,0) [0|1] ""  CVC_C,WCBS,FCAM_C,ADCU_C
 SG_ SAS_Calibrated : 35|2@0+ (1,0) [0|1] ""  CVC_C,WCBS,FCAM_C,ADCU_C
 SG_ SAS_SteerWheelAngleValid : 39|2@0+ (1,0) [0|1] ""  CVC_C,WCBS,FCAM_C,ADCU_C
 SG_ SAS_SteerWheelAngle : 47|16@0+ (0.0238,-780) [-780|779.7] "deg"  CVC_C,WCBS,FCAM_C,ADCU_C

BO_ 383 EPS_FCAM_TOI: 8 EPS
 SG_ CRC_EPS_FCAM_TOI : 7|8@0+ (1,0) [0|255] ""  FCAM_C,ADCU_C
 SG_ ALIVE_EPS_FCAM_TOI : 11|4@0+ (1,0) [0|15] ""  FCAM_C,ADCU_C
 SG_ EPS_FCAM_function_feed_2 : 20|3@0+ (1,0) [0|7] ""  FCAM_C,ADCU_C
 SG_ EPS_FCAM_function_feed : 23|3@0+ (1,0) [0|7] ""  FCAM_C,ADCU_C

BO_ 646 EPS_ADCU_VAP_Resp: 6 EPS
 SG_ CRC_EPS_ADCU_VAP_Resp : 7|8@0+ (1,0) [0|255] ""  ADCU_C
 SG_ ALIVE_EPS_ADCU_VAP_Resp : 11|4@0+ (1,0) [0|15] ""  ADCU_C
 SG_ EPS_ADCU_VAP_Mode : 19|4@0+ (1,0) [0|15] ""  ADCU_C
 SG_ EPS_ADCU_VAP_State : 25|2@0+ (1,0) [0|3] ""  ADCU_C
 SG_ EPS_ADCU_VAP_ControlResp : 23|4@0+ (1,0) [0|15] ""  ADCU_C
 SG_ EPS_ADCU_VAP_Available : 26|1@0+ (1,0) [0|1] ""  ADCU_C
 SG_ EPS_ADCU_VAP_SteerWheelAngle : 39|16@0+ (0.0238,-780) [-780|779.7] "deg"  ADCU_C
 SG_ EPS_ADCU_VAP_SteerAngleValid : 27|1@0+ (1,0) [0|1] ""  ADCU_C
 SG_ EPS_ADCU_VAP_SteerIntervention : 28|1@0+ (1,0) [0|1] ""  ADCU_C

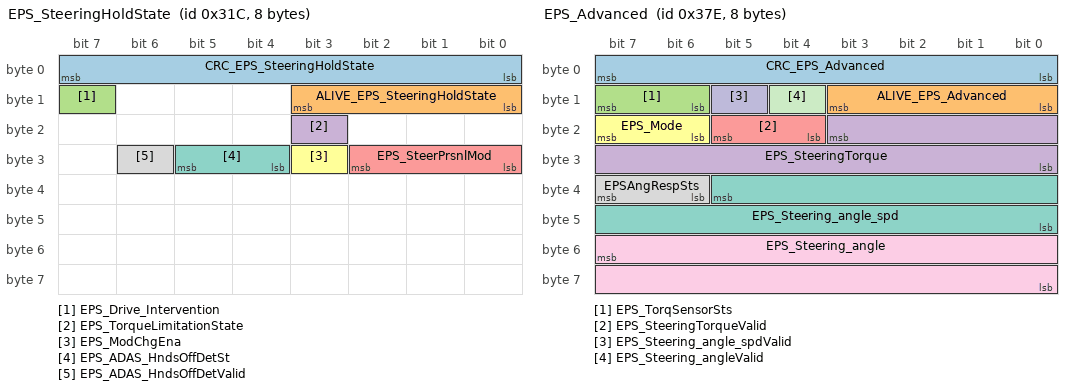
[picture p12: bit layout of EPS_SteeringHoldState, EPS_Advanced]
BO_ 796 EPS_SteeringHoldState: 8 EPS
 SG_ CRC_EPS_SteeringHoldState : 7|8@0+ (1,0) [0|255] ""  FCAM_C,ADCU_C
 SG_ ALIVE_EPS_SteeringHoldState : 11|4@0+ (1,0) [0|15] ""  FCAM_C,ADCU_C
 SG_ EPS_Drive_Intervention : 15|1@0+ (1,0) [0|1] ""  FCAM_C,ADCU_C
 SG_ EPS_TorqueLimitationState : 19|1@0+ (1,0) [0|1] ""  FCAM_C,ADCU_C
 SG_ EPS_SteerPrsnlMod : 26|3@0+ (1,0) [0|7] ""  CVC_C,FCAM_C,ADCU_C
 SG_ EPS_ModChgEna : 27|1@0+ (1,0) [0|1] ""  CVC_C,FCAM_C,ADCU_C
 SG_ EPS_ADAS_HndsOffDetSt : 29|2@0+ (1,0) [0|3] ""  FCAM_C,ADCU_C
 SG_ EPS_ADAS_HndsOffDetValid : 30|1@0+ (1,0) [0|1] ""  FCAM_C,ADCU_C

BO_ 891 EPS_FCAM_Steering_Trq: 16 EPS
 SG_ CRC_EPS_FCAM_Steering_Trq : 7|8@0+ (1,0) [0|255] ""  FCAM_C,ADCU_C
 SG_ ALIVE_EPS_FCAM_Steering_Trq : 11|4@0+ (1,0) [0|15] ""  FCAM_C,ADCU_C
 SG_ EPS_SteeringEMTorque : 34|12@0+ (0.01,-10.24) [-10.24|10.23] "Nm"  FCAM_C,ADCU_C
 SG_ EPS_FCAM_AOLAct : 15|2@0+ (1,0) [0|3] ""  FCAM_C,ADCU_C
 SG_ EPS_SteeringDriverTorque : 30|12@0+ (0.01,-10.24) [-10.24|10.23] "Nm"  FCAM_C,ADCU_C
 SG_ EPS_FCAM_Steering_Trq : 54|17@0+ (0.05,-2000) [-2000|2000] "Nm"  FCAM_C,ADCU_C
 SG_ EPS_FCAMADCUAdded_Steering_Trq : 84|17@0+ (0.05,-2000) [-2000|2000] "Nm"  FCAM_C,ADCU_C
 SG_ EPS_FCAM_TorqueBC : 69|17@0+ (0.05,-2000) [-2000|2000] "Nm"  FCAM_C,ADCU_C
 SG_ EPS_FCAM_SteeringDriverTorqueVal : 13|2@0+ (1,0) [0|3] ""  FCAM_C,ADCU_C

BO_ 894 EPS_Advanced: 8 EPS
 SG_ CRC_EPS_Advanced : 7|8@0+ (1,0) [0|255] ""  CVC_C,WCBS,FCAM_C,ADCU_C
 SG_ ALIVE_EPS_Advanced : 11|4@0+ (1,0) [0|15] ""  CVC_C,WCBS,FCAM_C,ADCU_C
 SG_ EPS_TorqSensorSts : 15|2@0+ (1,0) [0|1] ""  CVC_C,WCBS,FCAM_C,ADCU_C
 SG_ EPS_SteeringTorque : 19|12@0+ (0.5,-500) [-500|500] "Nm"  CVC_C,WCBS,FCAM_C,ADCU_C
 SG_ EPS_SteeringTorqueValid : 21|2@0+ (1,0) [0|1] ""  CVC_C,WCBS,FCAM_C,ADCU_C
 SG_ EPS_Mode : 23|2@0+ (1,0) [0|3] ""  CVC_C,WCBS,FCAM_C,ADCU_C
 SG_ EPS_Steering_angle_spd : 37|14@0+ (0.125,-1024) [-1024|1023.875] "degree/s"  CVC_C,WCBS,FCAM_C,ADCU_C
 SG_ EPSAngRespSts : 39|2@0+ (1,0) [0|3] ""  CVC_C,WCBS,FCAM_C,ADCU_C
 SG_ EPS_Steering_angle : 55|16@0+ (0.0238,-780) [-780|779.733] "deg"  CVC_C,WCBS,FCAM_C,ADCU_C
 SG_ EPS_Steering_angle_spdValid : 13|1@0+ (1,0) [0|1] ""  CVC_C,WCBS,FCAM_C,ADCU_C
 SG_ EPS_Steering_angleValid : 12|1@0+ (1,0) [0|1] ""  CVC_C,WCBS,FCAM_C,ADCU_C

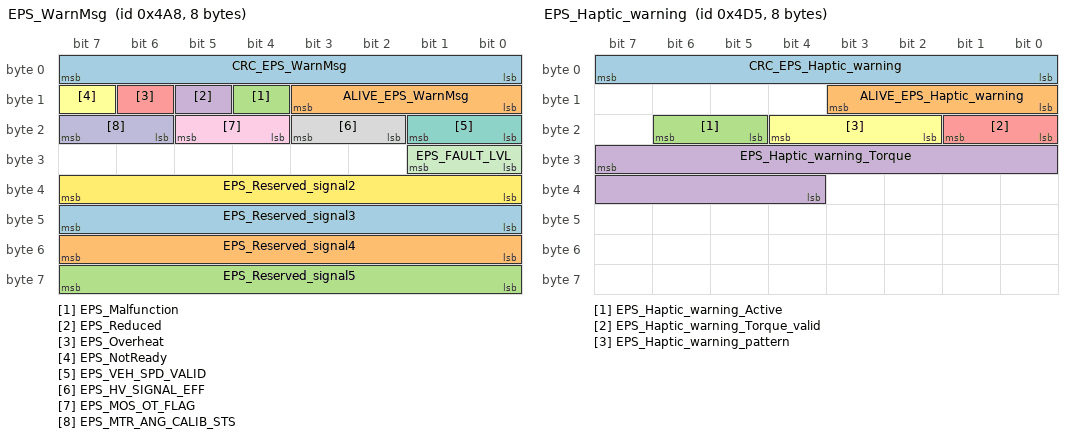
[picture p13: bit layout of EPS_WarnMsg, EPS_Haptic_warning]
BO_ 1192 EPS_WarnMsg: 8 EPS
 SG_ CRC_EPS_WarnMsg : 7|8@0+ (1,0) [0|255] ""  CVC_C,FCAM_C,ADCU_C
 SG_ ALIVE_EPS_WarnMsg : 11|4@0+ (1,0) [0|15] ""  CVC_C,FCAM_C,ADCU_C
 SG_ EPS_Malfunction : 12|1@0+ (1,0) [0|1] ""  CVC_C,FCAM_C,ADCU_C
 SG_ EPS_Reduced : 13|1@0+ (1,0) [0|1] ""  CVC_C,FCAM_C,ADCU_C
 SG_ EPS_Overheat : 14|1@0+ (1,0) [0|1] ""  CVC_C,FCAM_C,ADCU_C
 SG_ EPS_NotReady : 15|1@0+ (1,0) [0|1] ""  CVC_C,FCAM_C,ADCU_C
 SG_ EPS_VEH_SPD_VALID : 17|2@0+ (1,0) [0|3] ""  CVC_C,FCAM_C,ADCU_C
 SG_ EPS_HV_SIGNAL_EFF : 19|2@0+ (1,0) [0|3] ""  CVC_C,FCAM_C,ADCU_C
 SG_ EPS_MOS_OT_FLAG : 21|2@0+ (1,0) [0|3] ""  CVC_C,FCAM_C,ADCU_C
 SG_ EPS_MTR_ANG_CALIB_STS : 23|2@0+ (1,0) [0|3] ""  CVC_C,FCAM_C,ADCU_C
 SG_ EPS_FAULT_LVL : 25|2@0+ (1,0) [0|3] ""  CVC_C,FCAM_C,ADCU_C
 SG_ EPS_Reserved_signal2 : 39|8@0+ (1,0) [0|255] ""  CVC_C,FCAM_C,ADCU_C
 SG_ EPS_Reserved_signal3 : 47|8@0+ (1,0) [0|255] ""  CVC_C,FCAM_C,ADCU_C
 SG_ EPS_Reserved_signal4 : 55|8@0+ (1,0) [0|255] ""  CVC_C,FCAM_C,ADCU_C
 SG_ EPS_Reserved_signal5 : 63|8@0+ (1,0) [0|255] ""  CVC_C,FCAM_C,ADCU_C

BO_ 1237 EPS_Haptic_warning: 8 EPS
 SG_ CRC_EPS_Haptic_warning : 7|8@0+ (1,0) [0|255] ""  CVC_C,WCBS,FCAM_C,ADCU_C
 SG_ ALIVE_EPS_Haptic_warning : 11|4@0+ (1,0) [0|15] ""  CVC_C,WCBS,FCAM_C,ADCU_C
 SG_ EPS_Haptic_warning_Active : 22|2@0+ (1,0) [0|1] ""  CVC_C,WCBS,FCAM_C,ADCU_C
 SG_ EPS_Haptic_warning_Torque : 31|12@0+ (0.01,-10.24) [-10.24|10.23] ""  CVC_C,WCBS,FCAM_C,ADCU_C
 SG_ EPS_Haptic_warning_Torque_valid : 17|2@0+ (1,0) [0|1] ""  CVC_C,WCBS,FCAM_C,ADCU_C
 SG_ EPS_Haptic_warning_pattern : 20|3@0+ (1,0) [0|7] ""  CVC_C,WCBS,FCAM_C,ADCU_C

BO_ 1877 EPS_Function_debug_01: 32 EPS
 SG_ EPS_Return_control_Active : 121|2@0+ (1,0) [0|1] ""  CVC_C,WCBS,FCAM_C,ADCU_C
 SG_ EPS_Return_control_Torque : 43|12@0+ (0.01,-10.24) [-10.24|10.23] ""  CVC_C,WCBS,FCAM_C,ADCU_C
 SG_ EPS_Return_control_Torque_valid : 47|2@0+ (1,0) [0|1] ""  CVC_C,WCBS,FCAM_C,ADCU_C
 SG_ EPS_Damping_control_Active : 135|2@0+ (1,0) [0|1] ""  CVC_C,WCBS,FCAM_C,ADCU_C
 SG_ EPS_Damping_control_Torque : 95|12@0+ (0.01,-10.24) [-10.24|10.23] ""  CVC_C,WCBS,FCAM_C,ADCU_C
 SG_ EPS_Damping_control_Torque_valid : 61|2@0+ (1,0) [0|1] ""  CVC_C,WCBS,FCAM_C,ADCU_C
 SG_ EPS_IC_Active : 35|2@0+ (1,0) [0|1] ""  CVC_C,WCBS,FCAM_C,ADCU_C
 SG_ EPS_IC_Torque : 119|12@0+ (0.01,-10.24) [-10.24|10.23] ""  CVC_C,WCBS,FCAM_C,ADCU_C
 SG_ EPS_IC_Torque_valid : 71|2@0+ (1,0) [0|1] ""  CVC_C,WCBS,FCAM_C,ADCU_C
 SG_ EPS_Shimmy_Comp_Active : 69|2@0+ (1,0) [0|1] ""  CVC_C,WCBS,FCAM_C,ADCU_C
 SG_ EPS_Shimmy_Comp_Torque : 75|12@0+ (0.01,-10.24) [-10.24|10.23] ""  CVC_C,WCBS,FCAM_C,ADCU_C
 SG_ EPS_Shimmy_Comp_Torque_valid : 79|2@0+ (1,0) [0|1] ""  CVC_C,WCBS,FCAM_C,ADCU_C
 SG_ EPS_PDC_Active : 67|2@0+ (1,0) [0|1] ""  CVC_C,WCBS,FCAM_C,ADCU_C
 SG_ EPS_PDC_Torque : 99|12@0+ (0.01,-10.24) [-10.24|10.23] ""  CVC_C,WCBS,FCAM_C,ADCU_C
 SG_ EPS_PDC_Torque_valid : 33|2@0+ (1,0) [0|1] ""  CVC_C,WCBS,FCAM_C,ADCU_C
 SG_ EPS_Yaw_Damping_control_Active : 45|2@0+ (1,0) [0|1] ""  CVC_C,WCBS,FCAM_C,ADCU_C
 SG_ EPS_Yaw_Damping_control_Torque : 131|12@0+ (0.01,-10.24) [-10.24|10.23] ""  CVC_C,WCBS,FCAM_C,ADCU_C
 SG_ EPS_Yaw_Damping_control_valid : 65|2@0+ (1,0) [0|1] ""  CVC_C,WCBS,FCAM_C,ADCU_C
 SG_ EPS_FC_Active : 77|2@0+ (1,0) [0|1] ""  CVC_C,WCBS,FCAM_C,ADCU_C
 SG_ EPS_FC_Torque : 151|12@0+ (0.01,-10.24) [-10.24|10.23] ""  CVC_C,WCBS,FCAM_C,ADCU_C
 SG_ EPS_FC_Torque_valid : 59|2@0+ (1,0) [0|1] ""  CVC_C,WCBS,FCAM_C,ADCU_C
 SG_ EPS_OP_Active : 57|2@0+ (1,0) [0|1] ""  CVC_C,WCBS,FCAM_C,ADCU_C
 SG_ EPS_Unreduced_motor_torque_L1 : 155|12@0+ (0.01,-10.24) [-10.24|10.23] ""  CVC_C,WCBS,FCAM_C,ADCU_C
 SG_ EPS_Unreduced_motor_torque_L2 : 175|12@0+ (0.01,-10.24) [-10.24|10.23] ""  CVC_C,WCBS,FCAM_C,ADCU_C
 SG_ EPS_Reduced_motor_torque_L1 : 179|12@0+ (0.01,-10.24) [-10.24|10.23] ""  CVC_C,WCBS,FCAM_C,ADCU_C
 SG_ EPS_Reduced_motor_torque_L2 : 199|12@0+ (0.01,-10.24) [-10.24|10.23] ""  CVC_C,WCBS,FCAM_C,ADCU_C
 SG_ EPS_Max_Assist_torque_capability : 203|12@0+ (0.01,-10.24) [-10.24|10.23] ""  CVC_C,WCBS,FCAM_C,ADCU_C
 SG_ EPS_Max_Assist_torque_capab_0000 : 123|2@0+ (1,0) [0|1] ""  CVC_C,WCBS,FCAM_C,ADCU_C
 SG_ EPS_Max_Assist_torque_capab_0001 : 223|12@0+ (0.01,-10.24) [-10.24|10.23] ""  CVC_C,WCBS,FCAM_C,ADCU_C
 SG_ EPS_Max_Assist_torque_capab_0002 : 133|2@0+ (1,0) [0|1] ""  CVC_C,WCBS,FCAM_C,ADCU_C
 SG_ EPS_Operating_states : 23|3@0+ (1,0) [0|7] ""  CVC_C,WCBS,FCAM_C,ADCU_C
 SG_ EPS_TSC_Torque : 31|12@0+ (0.01,-10.24) [-10.24|10.23] "Nm"  CVC_C,WCBS,FCAM_C,ADCU_C
 SG_ EPS_TSC_Torque_valid : 63|2@0+ (1,0) [0|1] ""  CVC_C,WCBS,FCAM_C,ADCU_C
 SG_ EPS_TSC_Active : 227|2@0+ (1,0) [0|1] ""  CVC_C,WCBS,FCAM_C,ADCU_C

BO_ 1975 EPS_Synchronization_Req: 8 EPS
 SG_ EPS_Req_RandomData : 7|24@0+ (1,0) [0|16777215] ""  CVC_C
 SG_ EPS_Req_MAC : 31|40@0+ (1,0) [0|1099511627775] ""  CVC_C

BO_ 275 WCBS_ESCTrqReq: 24 WCBS
 SG_ CRC_WCBS_ESCTrqReq : 7|8@0+ (1,0) [0|255] ""  CVC_C
 SG_ ALIVE_WCBS_ESCTrqReq : 11|4@0+ (1,0) [0|15] ""  CVC_C
 SG_ WCBS_R_TrqDecReq : 12|1@0+ (1,0) [0|1] ""  CVC_C
 SG_ WCBS_R_TrqDecActive : 13|1@0+ (1,0) [0|1] ""  CVC_C
 SG_ WCBS_R_TrqIncrReq : 14|1@0+ (1,0) [0|1] ""  CVC_C
 SG_ WCBS_R_TrqIncrActive : 15|1@0+ (1,0) [0|1] ""  CVC_C
 SG_ WCBS_R_TrqDecFast : 23|16@0+ (1,-4000) [-4000|4000] "Nm"  CVC_C
 SG_ WCBS_R_TrqDecSlow : 39|8@0+ (1,0) [0|255] "Nm"  CVC_C
 SG_ WCBS_R_TrqIncrFast : 47|16@0+ (1,-4000) [-4000|4000] "Nm"  CVC_C
 SG_ WCBS_F_TrqDecFast : 59|16@0+ (1,-4000) [-4000|4000] "Nm"  CVC_C
 SG_ WCBS_F_TrqDecReq : 60|1@0+ (1,0) [0|1] ""  CVC_C
 SG_ WCBS_F_TrqDecActive : 61|1@0+ (1,0) [0|1] ""  CVC_C
 SG_ WCBS_F_TrqIncrReq : 62|1@0+ (1,0) [0|1] ""  CVC_C
 SG_ WCBS_F_TrqIncrActive : 63|1@0+ (1,0) [0|1] ""  CVC_C
 SG_ WCBS_F_TrqIncrFast : 75|16@0+ (1,-4000) [-4000|4000] "Nm"  CVC_C
 SG_ Secure_ResetCnt_0x113 : 135|16@0+ (1,0) [0|65535] ""  CVC_C
 SG_ Secure_MsgCnt_0x113 : 151|16@0+ (1,0) [0|65535] ""  CVC_C
 SG_ Secure_MAC_0x113 : 167|32@0+ (1,0) [0|4294967295] ""  CVC_C

BO_ 279 WCBS_Pressure: 16 WCBS
 SG_ CRC_WCBS_Pressure : 7|8@0+ (1,0) [0|255] ""  CVC_C,FCAM_C,ADCU_C
 SG_ ALIVE_WCBS_Pressure : 11|4@0+ (1,0) [0|15] ""  CVC_C,FCAM_C,ADCU_C
 SG_ WCBS_CircuitPress : 58|15@0+ (0.01,0) [0|327.67] "bar"  CVC_C,FCAM_C,ADCU_C
 SG_ WCBS_CircuitPressValid : 109|1@0+ (1,0) [0|1] ""  CVC_C,FCAM_C,ADCU_C
 SG_ WCBS_EstWhlPress_FL : 23|15@0+ (0.01,0) [0|327.67] "bar"  CVC_C,FCAM_C,ADCU_C
 SG_ WCBS_EstWhlPress_FR : 92|15@0+ (0.01,0) [0|327.67] "bar"  CVC_C,FCAM_C,ADCU_C
 SG_ WCBS_EstWhlPress_RL : 75|15@0+ (0.01,0) [0|327.67] "bar"  CVC_C,FCAM_C,ADCU_C
 SG_ WCBS_EstWhlPress_RR : 24|15@0+ (0.01,0) [0|327.67] "bar"  CVC_C,FCAM_C,ADCU_C
 SG_ WCBS_EstWhlPressValid : 108|1@0+ (1,0) [0|1] ""  CVC_C,FCAM_C,ADCU_C
 SG_ WCBS_MainCylinderPress : 41|15@0+ (0.01,0) [0|250] "bar"  CVC_C,FCAM_C,ADCU_C
 SG_ WCBS_MainCylinderPressValid : 107|1@0+ (1,0) [0|1] ""  CVC_C,FCAM_C,ADCU_C

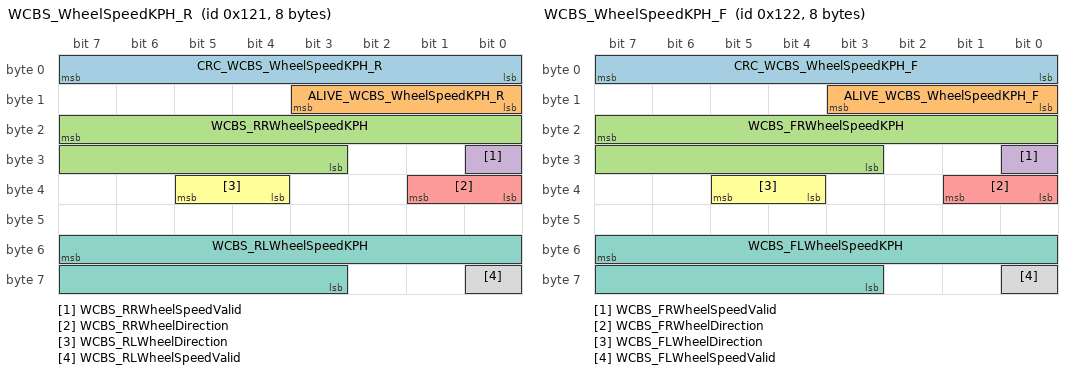
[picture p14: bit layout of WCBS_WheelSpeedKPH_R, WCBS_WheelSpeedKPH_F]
BO_ 289 WCBS_WheelSpeedKPH_R: 8 WCBS
 SG_ CRC_WCBS_WheelSpeedKPH_R : 7|8@0+ (1,0) [0|255] ""  CVC_C,FCAM_C,ADCU_C
 SG_ ALIVE_WCBS_WheelSpeedKPH_R : 11|4@0+ (1,0) [0|15] ""  CVC_C,FCAM_C,ADCU_C
 SG_ WCBS_RRWheelSpeedKPH : 23|13@0+ (0.05625,0) [0|460.6875] "Km/h"  CVC_C,FCAM_C,ADCU_C
 SG_ WCBS_RRWheelSpeedValid : 24|1@0+ (1,0) [0|1] ""  CVC_C,FCAM_C,ADCU_C
 SG_ WCBS_RRWheelDirection : 33|2@0+ (1,0) [0|3] ""  CVC_C,FCAM_C,ADCU_C
 SG_ WCBS_RLWheelDirection : 37|2@0+ (1,0) [0|3] ""  CVC_C,FCAM_C,ADCU_C
 SG_ WCBS_RLWheelSpeedKPH : 55|13@0+ (0.05625,0) [0|460.6875] "Km/h"  CVC_C,FCAM_C,ADCU_C
 SG_ WCBS_RLWheelSpeedValid : 56|1@0+ (1,0) [0|1] ""  CVC_C,FCAM_C,ADCU_C

BO_ 290 WCBS_WheelSpeedKPH_F: 8 WCBS
 SG_ CRC_WCBS_WheelSpeedKPH_F : 7|8@0+ (1,0) [0|255] ""  CVC_C,FCAM_C,ADCU_C
 SG_ ALIVE_WCBS_WheelSpeedKPH_F : 11|4@0+ (1,0) [0|15] ""  CVC_C,FCAM_C,ADCU_C
 SG_ WCBS_FRWheelSpeedKPH : 23|13@0+ (0.05625,0) [0|460.6875] "Km/h"  CVC_C,FCAM_C,ADCU_C
 SG_ WCBS_FRWheelSpeedValid : 24|1@0+ (1,0) [0|1] ""  CVC_C,FCAM_C,ADCU_C
 SG_ WCBS_FRWheelDirection : 33|2@0+ (1,0) [0|3] ""  CVC_C,FCAM_C,ADCU_C
 SG_ WCBS_FLWheelDirection : 37|2@0+ (1,0) [0|3] ""  CVC_C,FCAM_C,ADCU_C
 SG_ WCBS_FLWheelSpeedKPH : 55|13@0+ (0.05625,0) [0|460.6875] "Km/h"  CVC_C,FCAM_C,ADCU_C
 SG_ WCBS_FLWheelSpeedValid : 56|1@0+ (1,0) [0|1] ""  CVC_C,FCAM_C,ADCU_C

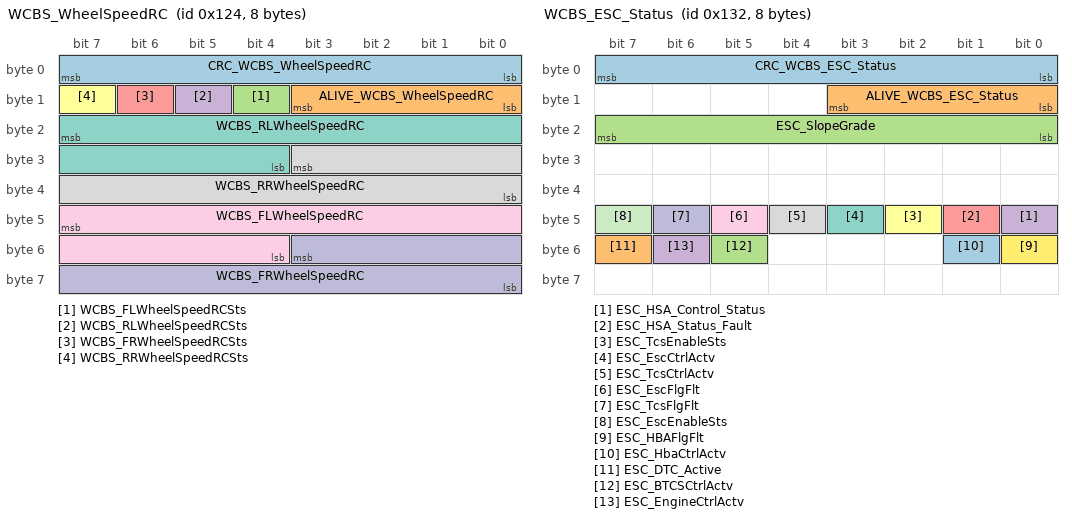
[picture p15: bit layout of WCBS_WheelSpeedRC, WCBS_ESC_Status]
BO_ 292 WCBS_WheelSpeedRC: 8 WCBS
 SG_ CRC_WCBS_WheelSpeedRC : 7|8@0+ (1,0) [0|255] ""  CVC_C,FCAM_C,ADCU_C
 SG_ ALIVE_WCBS_WheelSpeedRC : 11|4@0+ (1,0) [0|15] ""  CVC_C,FCAM_C,ADCU_C
 SG_ WCBS_FLWheelSpeedRCSts : 12|1@0+ (1,0) [0|1] ""  CVC_C,FCAM_C,ADCU_C
 SG_ WCBS_RLWheelSpeedRCSts : 13|1@0+ (1,0) [0|1] ""  CVC_C,FCAM_C,ADCU_C
 SG_ WCBS_FRWheelSpeedRCSts : 14|1@0+ (1,0) [0|1] ""  CVC_C,FCAM_C,ADCU_C
 SG_ WCBS_RRWheelSpeedRCSts : 15|1@0+ (1,0) [0|1] ""  CVC_C,FCAM_C,ADCU_C
 SG_ WCBS_RLWheelSpeedRC : 23|12@0+ (1,0) [0|4095] ""  CVC_C,FCAM_C,ADCU_C
 SG_ WCBS_RRWheelSpeedRC : 27|12@0+ (1,0) [0|4095] ""  CVC_C,FCAM_C,ADCU_C
 SG_ WCBS_FLWheelSpeedRC : 47|12@0+ (1,0) [0|4095] ""  CVC_C,FCAM_C,ADCU_C
 SG_ WCBS_FRWheelSpeedRC : 51|12@0+ (1,0) [0|4095] ""  CVC_C,FCAM_C,ADCU_C

BO_ 306 WCBS_ESC_Status: 8 WCBS
 SG_ CRC_WCBS_ESC_Status : 7|8@0+ (1,0) [0|255] ""  CVC_C,FCAM_C,ADCU_C
 SG_ ALIVE_WCBS_ESC_Status : 11|4@0+ (1,0) [0|15] ""  CVC_C,FCAM_C,ADCU_C
 SG_ ESC_SlopeGrade : 23|8@0+ (1,-30) [-30|30] "%"  CVC_C,FCAM_C,ADCU_C
 SG_ ESC_HSA_Control_Status : 40|1@0+ (1,0) [0|1] ""  CVC_C,FCAM_C,ADCU_C
 SG_ ESC_HSA_Status_Fault : 41|1@0+ (1,0) [0|1] ""  CVC_C,FCAM_C,ADCU_C
 SG_ ESC_TcsEnableSts : 42|1@0+ (1,0) [0|1] ""  CVC_C,FCAM_C,ADCU_C
 SG_ ESC_EscCtrlActv : 43|1@0+ (1,0) [0|1] ""  CVC_C,FCAM_C,ADCU_C
 SG_ ESC_TcsCtrlActv : 44|1@0+ (1,0) [0|1] ""  CVC_C,FCAM_C,ADCU_C
 SG_ ESC_EscFlgFlt : 45|1@0+ (1,0) [0|1] ""  CVC_C,FCAM_C,ADCU_C
 SG_ ESC_TcsFlgFlt : 46|1@0+ (1,0) [0|1] ""  CVC_C,FCAM_C,ADCU_C
 SG_ ESC_EscEnableSts : 47|1@0+ (1,0) [0|1] ""  CVC_C,FCAM_C,ADCU_C
 SG_ ESC_HBAFlgFlt : 48|1@0+ (1,0) [0|1] ""  CVC_C,FCAM_C,ADCU_C
 SG_ ESC_HbaCtrlActv : 49|1@0+ (1,0) [0|1] ""  CVC_C,FCAM_C,ADCU_C
 SG_ ESC_DTC_Active : 55|1@0+ (1,0) [0|1] ""  CVC_C,FCAM_C,ADCU_C
 SG_ ESC_BTCSCtrlActv : 53|1@0+ (1,0) [0|1] ""  CVC_C,FCAM_C,ADCU_C
 SG_ ESC_EngineCtrlActv : 54|1@0+ (1,0) [0|1] ""  CVC_C,FCAM_C,ADCU_C

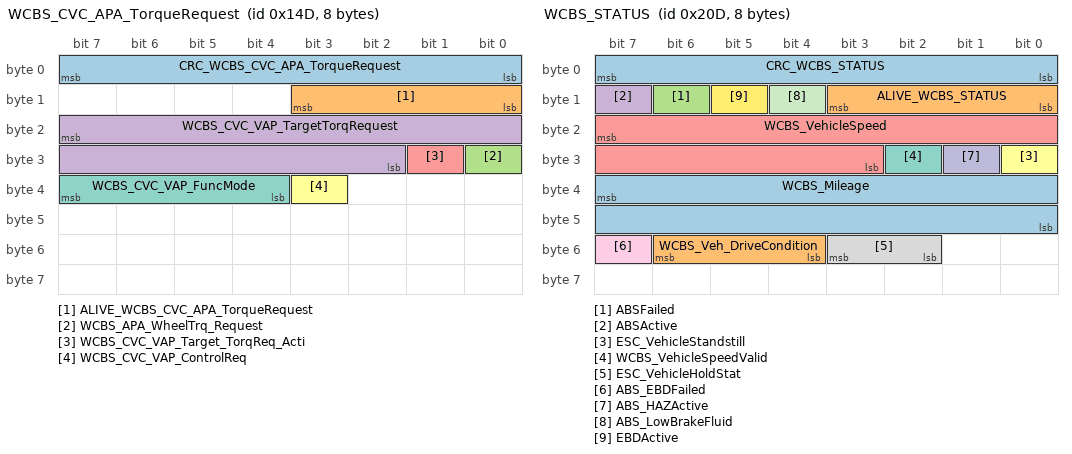
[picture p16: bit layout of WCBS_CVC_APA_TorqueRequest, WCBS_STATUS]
BO_ 333 WCBS_CVC_APA_TorqueRequest: 8 WCBS
 SG_ CRC_WCBS_CVC_APA_TorqueRequest : 7|8@0+ (1,0) [0|255] ""  CVC_C,ADCU_C
 SG_ ALIVE_WCBS_CVC_APA_TorqueRequest : 11|4@0+ (1,0) [0|15] ""  CVC_C,ADCU_C
 SG_ WCBS_APA_WheelTrq_Request : 24|1@0+ (1,0) [0|1] ""  CVC_C,ADCU_C
 SG_ WCBS_CVC_VAP_TargetTorqRequest : 23|14@0+ (1,-8000) [-8000|8000] "Nm"  CVC_C,ADCU_C
 SG_ WCBS_CVC_VAP_Target_TorqReq_Acti : 25|1@0+ (1,0) [0|1] ""  CVC_C,ADCU_C
 SG_ WCBS_CVC_VAP_ControlReq : 35|1@0+ (1,0) [0|1] ""  CVC_C,ADCU_C
 SG_ WCBS_CVC_VAP_FuncMode : 39|4@0+ (1,0) [0|15] ""  CVC_C,ADCU_C

BO_ 525 WCBS_STATUS: 8 WCBS
 SG_ CRC_WCBS_STATUS : 7|8@0+ (1,0) [0|255] ""  CVC_C,EPS,FCAM_C,ADCU_C
 SG_ ALIVE_WCBS_STATUS : 11|4@0+ (1,0) [0|15] ""  CVC_C,EPS,FCAM_C,ADCU_C
 SG_ ABSFailed : 14|1@0+ (1,0) [0|1] ""  CVC_C,FCAM_C,ADCU_C
 SG_ ABSActive : 15|1@0+ (1,0) [0|1] ""  CVC_C,FCAM_C,ADCU_C
 SG_ WCBS_VehicleSpeed : 23|13@0+ (0.05625,0) [0|300] "km/h"  CVC_C,EPS,FCAM_C,ADCU_C
 SG_ ESC_VehicleStandstill : 24|1@0+ (1,0) [0|1] ""  CVC_C,FCAM_C,ADCU_C
 SG_ WCBS_VehicleSpeedValid : 26|1@0+ (1,0) [0|1] ""  CVC_C,EPS,FCAM_C,ADCU_C
 SG_ ESC_VehicleHoldStat : 51|2@0+ (1,0) [0|3] ""  CVC_C,FCAM_C,ADCU_C
 SG_ ABS_EBDFailed : 55|1@0+ (1,0) [0|1] ""  CVC_C,FCAM_C,ADCU_C
 SG_ ABS_HAZActive : 25|1@0+ (1,0) [0|1] ""  CVC_C,FCAM_C,ADCU_C
 SG_ ABS_LowBrakeFluid : 12|1@0+ (1,0) [0|1] ""  CVC_C,FCAM_C,ADCU_C
 SG_ EBDActive : 13|1@0+ (1,0) [0|1] ""  CVC_C,FCAM_C,ADCU_C
 SG_ WCBS_Mileage : 39|16@0+ (1,0) [0|65535] "cm"  CVC_C,FCAM_C,ADCU_C
 SG_ WCBS_Veh_DriveCondition : 54|3@0+ (1,0) [0|7] ""  CVC_C,FCAM_C,ADCU_C

BO_ 560 WCBS_VAFS: 12 WCBS
 SG_ CRC_WCBS_VAFS : 7|8@0+ (1,0) [0|255] ""  CVC_C,FCAM_C,ADCU_C
 SG_ ALIVE_WCBS_VAFS : 11|4@0+ (1,0) [0|15] ""  CVC_C,FCAM_C,ADCU_C
 SG_ WCBS_BrkLampReq : 18|1@0+ (1,0) [0|1] ""  CVC_C,FCAM_C,ADCU_C
 SG_ EPB_SysWrnIndReq : 23|2@0+ (1,0) [0|2] ""  CVC_C,FCAM_C,ADCU_C
 SG_ EPB_SysStatIndReq : 25|2@0+ (1,0) [0|3] ""  CVC_C,FCAM_C,ADCU_C
 SG_ EPB_SysDspMsgReq : 30|3@0+ (1,0) [0|7] ""  CVC_C,FCAM_C,ADCU_C
 SG_ EPB_Sts : 51|3@0+ (1,0) [0|7] ""  CVC_C,FCAM_C,ADCU_C
 SG_ WCBS_TSMActive : 52|1@0+ (1,0) [0|1] ""  CVC_C,FCAM_C,ADCU_C
 SG_ EPB_CDPActive : 15|4@0+ (1,0) [0|15] ""  CVC_C,FCAM_C,ADCU_C
 SG_ EPB_Swch_Mafnc : 31|1@0+ (1,0) [0|1] ""  CVC_C,FCAM_C,ADCU_C
 SG_ WCBS_Avh_Available : 39|1@0+ (1,0) [0|1] ""  CVC_C,FCAM_C,ADCU_C
 SG_ WCBS_AVH_DispMsg : 38|3@0+ (1,0) [0|7] ""  CVC_C,FCAM_C,ADCU_C
 SG_ WCBS_AVH_Status : 35|4@0+ (1,0) [0|15] ""  CVC_C,FCAM_C,ADCU_C
 SG_ WCBS_EPB_Fault : 26|1@0+ (1,0) [0|1] ""  CVC_C,FCAM_C,ADCU_C
 SG_ WCBS_ROMActive : 27|1@0+ (1,0) [0|1] ""  CVC_C,FCAM_C,ADCU_C
 SG_ WCBS_ROMFailure : 17|1@0+ (1,0) [0|1] ""  CVC_C,FCAM_C,ADCU_C
 SG_ WCBS_TrailerDetected : 16|1@0+ (1,0) [0|1] ""  CVC_C,FCAM_C,ADCU_C
 SG_ WCBS_TSMFailure : 53|1@0+ (1,0) [0|1] ""  CVC_C,FCAM_C,ADCU_C
 SG_ WCBS_OnePedalAvailable : 48|1@0+ (1,0) [0|1] ""  CVC_C,ADCU_C
 SG_ WCBS_BrkFricTqTotAtWhls : 63|14@0+ (1,0) [0|15000] "Nm"  CVC_C,ADCU_C
 SG_ WCBS_HDCCtrlsts : 21|2@0+ (1,0) [0|3] ""  CVC_C,FCAM_C,ADCU_C
 SG_ WCBS_HDC_displayWarnMsg : 55|2@0+ (1,0) [0|3] ""  CVC_C,FCAM_C,ADCU_C
 SG_ WCBS_VehicleSteerSts : 47|2@0+ (1,0) [0|3] ""  CVC_C,FCAM_C,ADCU_C
 SG_ WCBS_HDC_available : 19|1@0+ (1,0) [0|1] ""  CVC_C,FCAM_C,ADCU_C
 SG_ WCBS_HDC_SwitchSts : 42|1@0+ (1,0) [0|1] ""  CVC_C,FCAM_C,ADCU_C
 SG_ WCBS_DTCFailure : 41|1@0+ (1,0) [0|1] ""  CVC_C,FCAM_C,ADCU_C
 SG_ WCBS_TowMode_Feedback : 65|2@0+ (1,0) [0|3] ""  CVC_C,FCAM_C,ADCU_C
 SG_ WCBS_SCM_available : 73|1@0+ (1,0) [0|1] ""  CVC_C
 SG_ WCBS_OnePedal_Active : 74|1@0+ (1,0) [0|1] ""  CVC_C,ADCU_C
 SG_ WCBS_OnePedal_hold_state : 75|1@0+ (1,0) [0|1] ""  CVC_C,ADCU_C
 SG_ WCBS_SCMActive : 77|1@0+ (1,0) [0|1] ""  CVC_C,ADCU_C
 SG_ WCBS_CDPFailSts : 76|1@0+ (1,0) [0|1] ""  CVC_C,ADCU_C
 SG_ WCBS_CBC_Active : 78|1@0+ (1,0) [0|1] ""  CVC_C
 SG_ WCBS_CBC_Available : 79|1@0+ (1,0) [0|1] ""  CVC_C
 SG_ WCBS_SLS_Active : 80|1@0+ (1,0) [0|1] ""  CVC_C
 SG_ WCBS_SLS_Available : 81|1@0+ (1,0) [0|1] ""  CVC_C
 SG_ WCBS_TVBB_Active : 82|1@0+ (1,0) [0|1] ""  CVC_C
 SG_ WCBS_TVBB_Available : 83|1@0+ (1,0) [0|1] ""  CVC_C
 SG_ WCBS_BDW_Active : 84|1@0+ (1,0) [0|1] ""  CVC_C
 SG_ WCBS_BDW_Available : 85|1@0+ (1,0) [0|1] ""  CVC_C

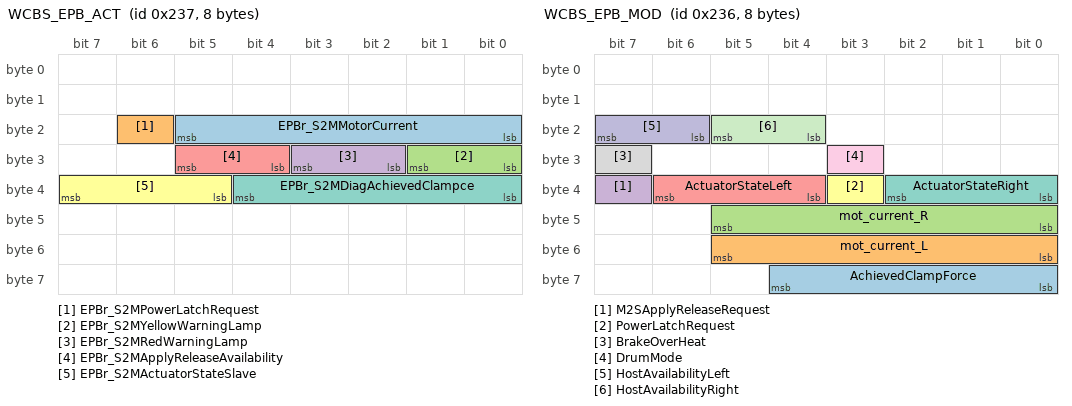
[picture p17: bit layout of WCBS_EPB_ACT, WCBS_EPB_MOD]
BO_ 567 WCBS_EPB_ACT: 8 WCBS
 SG_ EPBr_S2MMotorCurrent : 21|6@0+ (1,0) [0|63] "A"  CVC_C
 SG_ EPBr_S2MPowerLatchRequest : 22|1@0+ (1,0) [0|1] ""  CVC_C
 SG_ EPBr_S2MYellowWarningLamp : 25|2@0+ (1,0) [0|2] ""  CVC_C
 SG_ EPBr_S2MRedWarningLamp : 27|2@0+ (1,0) [0|2] ""  CVC_C
 SG_ EPBr_S2MApplyReleaseAvailability : 29|2@0+ (1,0) [0|3] ""  CVC_C
 SG_ EPBr_S2MActuatorStateSlave : 39|3@0+ (1,0) [0|7] ""  CVC_C
 SG_ EPBr_S2MDiagAchievedClampce : 36|5@0+ (1,0) [0|31] "KN"  CVC_C

BO_ 566 WCBS_EPB_MOD: 8 WCBS
 SG_ AchievedClampForce : 60|5@0+ (1,0) [0|31] "KN"  CVC_C
 SG_ mot_current_L : 53|6@0+ (1,0) [0|63] "A"  CVC_C
 SG_ mot_current_R : 45|6@0+ (1,0) [0|63] "A"  CVC_C
 SG_ M2SApplyReleaseRequest : 39|1@0+ (1,0) [0|1] ""  CVC_C
 SG_ ActuatorStateLeft : 38|3@0+ (1,0) [0|7] ""  CVC_C
 SG_ PowerLatchRequest : 35|1@0+ (1,0) [0|0] ""  CVC_C
 SG_ ActuatorStateRight : 34|3@0+ (1,0) [0|7] ""  CVC_C
 SG_ BrakeOverHeat : 31|1@0+ (1,0) [0|1] ""  CVC_C
 SG_ DrumMode : 27|1@0+ (1,0) [0|1] ""  CVC_C
 SG_ HostAvailabilityLeft : 23|2@0+ (1,0) [0|3] ""  CVC_C
 SG_ HostAvailabilityRight : 21|2@0+ (1,0) [0|3] ""  CVC_C

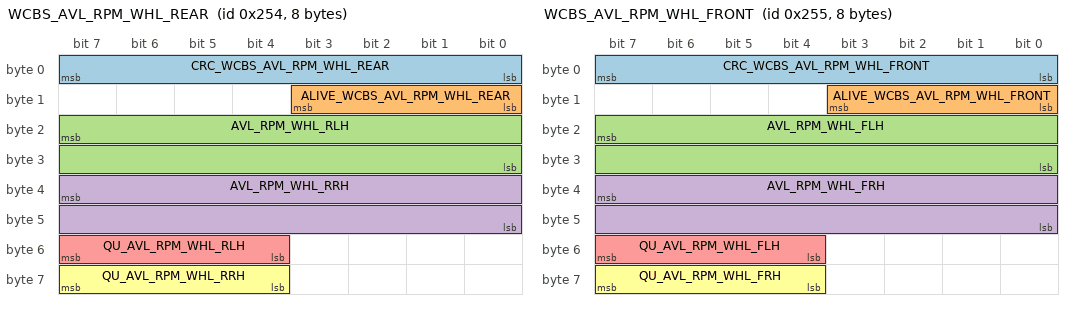
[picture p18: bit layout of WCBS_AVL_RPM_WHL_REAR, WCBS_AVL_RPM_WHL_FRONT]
BO_ 596 WCBS_AVL_RPM_WHL_REAR: 8 WCBS
 SG_ CRC_WCBS_AVL_RPM_WHL_REAR : 7|8@0+ (1,0) [0|255] ""  CVC_C,EPS,FCAM_C,ADCU_C
 SG_ ALIVE_WCBS_AVL_RPM_WHL_REAR : 11|4@0+ (1,0) [0|15] ""  CVC_C,EPS,FCAM_C,ADCU_C
 SG_ AVL_RPM_WHL_RLH : 23|16@0+ (0.0156,-511.9844) [-400|400] "rad/s"  CVC_C,EPS,FCAM_C,ADCU_C
 SG_ AVL_RPM_WHL_RRH : 39|16@0+ (0.0156,-511.9844) [-400|400] "rad/s"  CVC_C,EPS,FCAM_C,ADCU_C
 SG_ QU_AVL_RPM_WHL_RLH : 55|4@0+ (1,0) [0|15] ""  CVC_C,EPS,FCAM_C,ADCU_C
 SG_ QU_AVL_RPM_WHL_RRH : 63|4@0+ (1,0) [0|15] ""  CVC_C,EPS,FCAM_C,ADCU_C

BO_ 597 WCBS_AVL_RPM_WHL_FRONT: 8 WCBS
 SG_ CRC_WCBS_AVL_RPM_WHL_FRONT : 7|8@0+ (1,0) [0|255] ""  CVC_C,EPS,FCAM_C,ADCU_C
 SG_ ALIVE_WCBS_AVL_RPM_WHL_FRONT : 11|4@0+ (1,0) [0|15] ""  CVC_C,EPS,FCAM_C,ADCU_C
 SG_ AVL_RPM_WHL_FLH : 23|16@0+ (0.0156,-511.9844) [-400|400] "rad/s"  CVC_C,EPS,FCAM_C,ADCU_C
 SG_ AVL_RPM_WHL_FRH : 39|16@0+ (0.0156,-511.9844) [-400|400] "rad/s"  CVC_C,EPS,FCAM_C,ADCU_C
 SG_ QU_AVL_RPM_WHL_FLH : 55|4@0+ (1,0) [0|15] ""  CVC_C,EPS,FCAM_C,ADCU_C
 SG_ QU_AVL_RPM_WHL_FRH : 63|4@0+ (1,0) [0|15] ""  CVC_C,EPS,FCAM_C,ADCU_C

BO_ 624 WCBS_Info: 12 WCBS
 SG_ CRC_WCBS_Info : 7|8@0+ (1,0) [0|255] ""  CVC_C,FCAM_C,ADCU_C
 SG_ ALIVE_WCBS_Info : 11|4@0+ (1,0) [0|15] ""  CVC_C,FCAM_C,ADCU_C
 SG_ WCBS_Fault_Status : 14|3@0+ (1,0) [0|7] ""  CVC_C,FCAM_C,ADCU_C
 SG_ WCBS_IBS_Sys_Fault_Sts : 15|1@0+ (1,0) [0|1] ""  CVC_C,FCAM_C,ADCU_C
 SG_ WCBS_BrkPedalPct : 23|8@0+ (0.4,0) [0|100] "%"  CVC_C,FCAM_C,ADCU_C
 SG_ WCBS_BrkPedalTravel : 31|10@0+ (0.2,0) [0|150] "mm"  CVC_C,FCAM_C,ADCU_C
 SG_ WCBS_BrkPedalValid : 69|1@0+ (1,0) [0|1] ""  CVC_C,FCAM_C,ADCU_C
 SG_ WCBS_DiagMode : 68|1@0+ (1,0) [0|1] ""  CVC_C,FCAM_C,ADCU_C
 SG_ WCBS_RollerBenchMode : 67|1@0+ (1,0) [0|1] ""  CVC_C,FCAM_C,ADCU_C
 SG_ WCBSActive : 66|1@0+ (1,0) [0|1] ""  CVC_C,FCAM_C,ADCU_C
 SG_ WCBS_EOL_NotDone : 64|1@0+ (1,0) [0|1] ""  CVC_C,FCAM_C,ADCU_C
 SG_ STAT_DSC : 79|2@0+ (1,0) [0|3] ""  CVC_C,FCAM_C,ADCU_C
 SG_ WCBS_BLAFlt : 65|1@0+ (1,0) [0|1] ""  CVC_C,FCAM_C,ADCU_C
 SG_ FBW_WarningSts : 77|2@0+ (1,0) [0|3] ""  CVC_C,FCAM_C,ADCU_C
 SG_ Brake_Disc_Temp_FL : 35|7@0+ (10,40) [-40|800] ""  ADCU_C,DUMMY_ECU
 SG_ Brake_Disc_Temp_FR : 44|7@0+ (10,40) [-40|800] ""  ADCU_C,DUMMY_ECU
 SG_ Brake_Disc_Temp_RL : 53|7@0+ (10,40) [-40|800] ""  ADCU_C,DUMMY_ECU
 SG_ Brake_Disc_Temp_RR : 62|7@0+ (10,40) [-40|800] ""  ADCU_C,DUMMY_ECU
 SG_ WCBS_BrakesystemFailSts : 75|3@0+ (1,0) [0|7] ""  ADCU_C,DUMMY_ECU

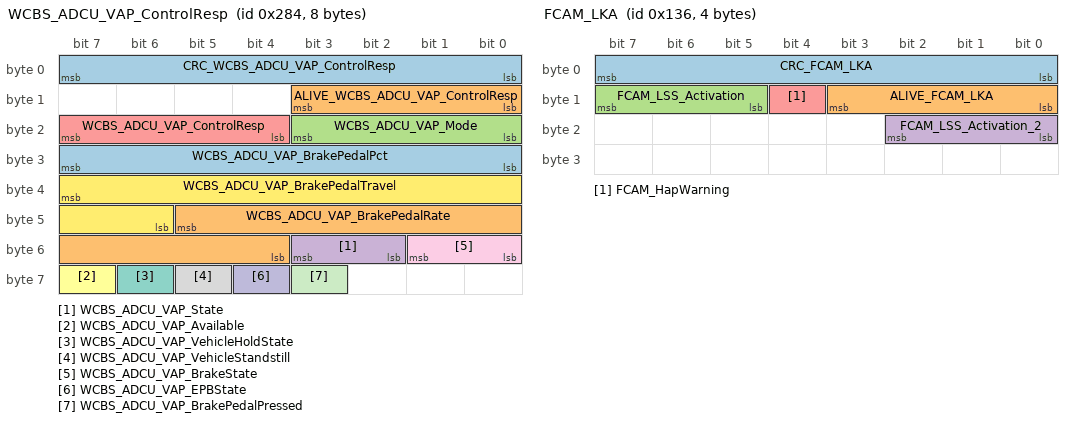
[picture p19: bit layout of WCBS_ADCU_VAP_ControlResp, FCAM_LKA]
BO_ 644 WCBS_ADCU_VAP_ControlResp: 8 WCBS
 SG_ CRC_WCBS_ADCU_VAP_ControlResp : 7|8@0+ (1,0) [0|255] ""  ADCU_C
 SG_ ALIVE_WCBS_ADCU_VAP_ControlResp : 11|4@0+ (1,0) [0|15] ""  ADCU_C
 SG_ WCBS_ADCU_VAP_Mode : 19|4@0+ (1,0) [0|15] ""  ADCU_C
 SG_ WCBS_ADCU_VAP_State : 51|2@0+ (1,0) [0|3] ""  ADCU_C
 SG_ WCBS_ADCU_VAP_ControlResp : 23|4@0+ (1,0) [0|15] ""  ADCU_C
 SG_ WCBS_ADCU_VAP_Available : 63|1@0+ (1,0) [0|1] ""  ADCU_C
 SG_ WCBS_ADCU_VAP_VehicleHoldState : 62|1@0+ (1,0) [0|1] ""  ADCU_C
 SG_ WCBS_ADCU_VAP_VehicleStandstill : 61|1@0+ (1,0) [0|1] ""  ADCU_C
 SG_ WCBS_ADCU_VAP_BrakeState : 49|2@0+ (1,0) [0|3] ""  ADCU_C
 SG_ WCBS_ADCU_VAP_EPBState : 60|1@0+ (1,0) [0|1] ""  ADCU_C
 SG_ WCBS_ADCU_VAP_BrakePedalPressed : 59|1@0+ (1,0) [0|1] ""  ADCU_C
 SG_ WCBS_ADCU_VAP_BrakePedalTravel : 39|10@0+ (0.2,0) [0|150] "mm"  ADCU_C
 SG_ WCBS_ADCU_VAP_BrakePedalPct : 31|8@0+ (0.4,0) [0|100] "%"  ADCU_C
 SG_ WCBS_ADCU_VAP_BrakePedalRate : 45|10@0+ (0.4,0) [0|300] "mm/s"  ADCU_C

BO_ 815 WCBS_ADAS_Info: 24 WCBS
 SG_ CRC_WCBS_ADAS_Info : 7|8@0+ (1,0) [0|255] ""  CVC_C,FCAM_C,ADCU_C
 SG_ ALIVE_WCBS_ADAS_Info : 11|4@0+ (1,0) [0|15] ""  CVC_C,FCAM_C,ADCU_C
 SG_ WCBS_ACC_Available_Flag : 13|1@0+ (1,0) [0|1] ""  CVC_C,FCAM_C,ADCU_C
 SG_ WCBS_ACC_Deceleration_Flag : 14|1@0+ (1,0) [0|1] ""  CVC_C,FCAM_C,ADCU_C
 SG_ WCBS_ACC_Acceleration_Flag : 15|1@0+ (1,0) [0|1] ""  CVC_C,FCAM_C,ADCU_C
 SG_ WCBS_RAEB_Active_Flag : 18|1@0+ (1,0) [0|1] ""  CVC_C,FCAM_C,ADCU_C
 SG_ WCBS_RAEB_Available_Flag : 19|1@0+ (1,0) [0|1] ""  CVC_C,FCAM_C,ADCU_C
 SG_ WCBS_AEB_Active_Flag : 20|1@0+ (1,0) [0|1] ""  CVC_C,FCAM_C,ADCU_C
 SG_ WCBS_AEB_Available_Flag : 21|1@0+ (1,0) [0|1] ""  CVC_C,FCAM_C,ADCU_C
 SG_ WCBS_ACC_DriverOverride : 23|2@0+ (1,0) [0|3] ""  CVC_C,FCAM_C,ADCU_C
 SG_ WCBS_ACC_TargetWheel_Torque : 31|16@0+ (1,-8000) [-8000|8000] "Nm"  CVC_C,FCAM_C,ADCU_C
 SG_ WCBS_ACC_WheelTrq_Active : 12|1@0+ (1,0) [0|1] ""  CVC_C,FCAM_C,ADCU_C
 SG_ WCBS_RAEB_BrakeActuator : 47|3@0+ (1,0) [0|7] ""  CVC_C,ADCU_C
 SG_ Secure_ResetCnt_0x32F : 135|16@0+ (1,0) [0|65535] ""  CVC_C,FCAM_C,ADCU_C
 SG_ Secure_MsgCnt_0x32F : 151|16@0+ (1,0) [0|65535] ""  CVC_C,FCAM_C,ADCU_C
 SG_ Secure_MAC_0x32F : 167|32@0+ (1,0) [0|4294967295] ""  CVC_C,FCAM_C,ADCU_C

BO_ 866 WCBS_RecuBrkTrqReq: 24 WCBS
 SG_ CRC_WCBS_RecuBrkTrqReq : 7|8@0+ (1,0) [0|255] ""  CVC_C
 SG_ ALIVE_WCBS_RecuBrkTrqReq : 11|4@0+ (1,0) [0|15] ""  CVC_C
 SG_ WCBS_RBC_STS : 12|1@0+ (1,0) [0|1] ""  CVC_C
 SG_ WCBS_RegenMonFail : 13|1@0+ (1,0) [0|1] ""  CVC_C
 SG_ WCBS_TorqReqMode : 15|2@0+ (1,0) [0|3] ""  CVC_C
 SG_ WCBS_F_RegenTarTrq : 23|16@0+ (1,-4000) [-4000|0] "Nm"  CVC_C
 SG_ WCBS_R_RegenTarTrq : 39|16@0+ (1,-4000) [-4000|0] "Nm"  CVC_C
 SG_ WCBS_F_RegenTarTrqValid : 48|1@0+ (1,0) [0|1] ""  CVC_C
 SG_ WCBS_R_RegenTarTrqValid : 49|1@0+ (1,0) [0|1] ""  CVC_C
 SG_ WCBS_F_FrictionTarTrq : 63|16@0+ (1,-4000) [-4000|0] "Nm"  CVC_C
 SG_ WCBS_R_FrictionTarTrq : 79|16@0+ (1,-4000) [-4000|0] "Nm"  CVC_C
 SG_ Secure_ResetCnt_0x362 : 135|16@0+ (1,0) [0|65535] ""  CVC_C
 SG_ Secure_MsgCnt_0x362 : 151|16@0+ (1,0) [0|65535] ""  CVC_C
 SG_ Secure_MAC_0x362 : 167|32@0+ (1,0) [0|4294967295] ""  CVC_C

BO_ 994 WCBS_IMU_Output: 16 WCBS
 SG_ CRC_WCBS_IMU_Output : 7|8@0+ (1,0) [0|255] ""  CVC_C,EPS,FCAM_C,ADCU_C
 SG_ ALIVE_WCBS_IMU_Output : 11|4@0+ (1,0) [0|15] ""  CVC_C,EPS,FCAM_C,ADCU_C
 SG_ WCBS_LateralACC_Valid : 12|1@0+ (1,0) [0|1] ""  CVC_C,FCAM_C,ADCU_C
 SG_ WCBS_LongitudeACC_Valid : 13|1@0+ (1,0) [0|1] ""  CVC_C,FCAM_C,ADCU_C
 SG_ WCBS_VehDynYawRate_Valid : 14|1@0+ (1,0) [0|1] ""  CVC_C,EPS,FCAM_C,ADCU_C
 SG_ WCBS_LateralACC : 23|16@0+ (0.005,-60) [-60|60] "m/s2"  CVC_C,FCAM_C,ADCU_C
 SG_ WCBS_LongitudeACC : 39|16@0+ (0.005,-60) [-60|60] "m/s2"  CVC_C,FCAM_C,ADCU_C
 SG_ WCBS_VehDynYawRate : 55|16@0+ (0.02,-300) [-300|300] "deg/s"  CVC_C,EPS,FCAM_C,ADCU_C
 SG_ WCBS_LateralACCRaw : 71|16@0+ (0.002,-60) [-60|60] "m/s2"  CVC_C,FCAM_C,ADCU_C
 SG_ WCBS_LongitudeACCRaw : 87|16@0+ (0.002,-60) [-60|60] "m/s2"  CVC_C,FCAM_C,ADCU_C
 SG_ WCBS_VehDynYawRateRaw : 103|16@0+ (0.01,-300) [-300|300] "deg/s"  CVC_C,FCAM_C,ADCU_C
 SG_ WCBS_ESCTarYawRate : 119|16@0+ (0.01,-300) [-300|300] "deg/s"  CVC_C,FCAM_C,ADCU_C

BO_ 1831 WCBS_PBC_library_test_M: 24 WCBS
 SG_ WCBS_PBC_library_testm0 : 7|8@0+ (1,0) [0|255] ""  DUMMY_ECU
 SG_ WCBS_PBC_library_testm1 : 15|8@0+ (1,0) [0|255] ""  DUMMY_ECU
 SG_ WCBS_PBC_library_testm2 : 23|8@0+ (1,0) [0|255] ""  DUMMY_ECU
 SG_ WCBS_PBC_library_testm3 : 31|8@0+ (1,0) [0|255] ""  DUMMY_ECU
 SG_ WCBS_PBC_library_testm4 : 39|8@0+ (1,0) [0|255] ""  DUMMY_ECU
 SG_ WCBS_PBC_library_testm5 : 47|8@0+ (1,0) [0|255] ""  DUMMY_ECU
 SG_ WCBS_PBC_library_testm6 : 55|8@0+ (1,0) [0|255] ""  DUMMY_ECU
 SG_ WCBS_PBC_library_testm7 : 63|8@0+ (1,0) [0|255] ""  DUMMY_ECU
 SG_ WCBS_PBC_library_testm8 : 71|8@0+ (1,0) [0|255] ""  DUMMY_ECU
 SG_ WCBS_PBC_library_testm9 : 79|8@0+ (1,0) [0|255] ""  DUMMY_ECU
 SG_ WCBS_PBC_library_testm10 : 87|8@0+ (1,0) [0|255] ""  DUMMY_ECU
 SG_ WCBS_PBC_library_testm11 : 95|8@0+ (1,0) [0|255] ""  DUMMY_ECU
 SG_ WCBS_PBC_library_testm12 : 103|8@0+ (1,0) [0|255] ""  DUMMY_ECU
 SG_ WCBS_PBC_library_testm13 : 111|8@0+ (1,0) [0|255] ""  DUMMY_ECU
 SG_ WCBS_PBC_library_testm14 : 119|8@0+ (1,0) [0|255] ""  DUMMY_ECU
 SG_ WCBS_PBC_library_testm15 : 127|8@0+ (1,0) [0|255] ""  DUMMY_ECU
 SG_ WCBS_PBC_library_testm16 : 135|8@0+ (1,0) [0|255] ""  DUMMY_ECU
 SG_ WCBS_PBC_library_testm17 : 143|8@0+ (1,0) [0|255] ""  DUMMY_ECU
 SG_ WCBS_PBC_library_testm18 : 151|8@0+ (1,0) [0|255] ""  DUMMY_ECU
 SG_ WCBS_PBC_library_testm19 : 159|8@0+ (1,0) [0|255] ""  DUMMY_ECU
 SG_ WCBS_PBC_library_testm20 : 167|8@0+ (1,0) [0|255] ""  DUMMY_ECU
 SG_ WCBS_PBC_library_testm21 : 175|8@0+ (1,0) [0|255] ""  DUMMY_ECU
 SG_ WCBS_PBC_library_testm22 : 183|8@0+ (1,0) [0|255] ""  DUMMY_ECU
 SG_ WCBS_PBC_library_testm23 : 191|8@0+ (1,0) [0|255] ""  DUMMY_ECU

BO_ 1832 WCBS_PBC_library_test_A: 24 WCBS
 SG_ WCBS_PBC_library_testa0 : 7|8@0+ (1,0) [0|255] ""  DUMMY_ECU
 SG_ WCBS_PBC_library_testa1 : 15|8@0+ (1,0) [0|255] ""  DUMMY_ECU
 SG_ WCBS_PBC_library_testa2 : 23|8@0+ (1,0) [0|255] ""  DUMMY_ECU
 SG_ WCBS_PBC_library_testa3 : 31|8@0+ (1,0) [0|255] ""  DUMMY_ECU
 SG_ WCBS_PBC_library_testa4 : 39|8@0+ (1,0) [0|255] ""  DUMMY_ECU
 SG_ WCBS_PBC_library_testa5 : 47|8@0+ (1,0) [0|255] ""  DUMMY_ECU
 SG_ WCBS_PBC_library_testa6 : 55|8@0+ (1,0) [0|255] ""  DUMMY_ECU
 SG_ WCBS_PBC_library_testa7 : 63|8@0+ (1,0) [0|255] ""  DUMMY_ECU
 SG_ WCBS_PBC_library_testa8 : 71|8@0+ (1,0) [0|255] ""  DUMMY_ECU
 SG_ WCBS_PBC_library_testa9 : 79|8@0+ (1,0) [0|255] ""  DUMMY_ECU
 SG_ WCBS_PBC_library_testa10 : 87|8@0+ (1,0) [0|255] ""  DUMMY_ECU
 SG_ WCBS_PBC_library_testa11 : 95|8@0+ (1,0) [0|255] ""  DUMMY_ECU
 SG_ WCBS_PBC_library_testa12 : 103|8@0+ (1,0) [0|255] ""  DUMMY_ECU
 SG_ WCBS_PBC_library_testa13 : 111|8@0+ (1,0) [0|255] ""  DUMMY_ECU
 SG_ WCBS_PBC_library_testa14 : 119|8@0+ (1,0) [0|255] ""  DUMMY_ECU
 SG_ WCBS_PBC_library_testa15 : 127|8@0+ (1,0) [0|255] ""  DUMMY_ECU
 SG_ WCBS_PBC_library_testa16 : 135|8@0+ (1,0) [0|255] ""  DUMMY_ECU
 SG_ WCBS_PBC_library_testa17 : 143|8@0+ (1,0) [0|255] ""  DUMMY_ECU
 SG_ WCBS_PBC_library_testa18 : 151|8@0+ (1,0) [0|255] ""  DUMMY_ECU
 SG_ WCBS_PBC_library_testa19 : 159|8@0+ (1,0) [0|255] ""  DUMMY_ECU
 SG_ WCBS_PBC_library_testa20 : 167|8@0+ (1,0) [0|255] ""  DUMMY_ECU
 SG_ WCBS_PBC_library_testa21 : 175|8@0+ (1,0) [0|255] ""  DUMMY_ECU
 SG_ WCBS_PBC_library_testa22 : 183|8@0+ (1,0) [0|255] ""  DUMMY_ECU
 SG_ WCBS_PBC_library_testa23 : 191|8@0+ (1,0) [0|255] ""  DUMMY_ECU

BO_ 1971 WCBS_Synchronization_Req: 8 WCBS
 SG_ WCBS_Req_RandomData : 7|24@0+ (1,0) [0|16777215] ""  CVC_C
 SG_ WCBS_Req_MAC : 31|40@0+ (1,0) [0|1099511627775] ""  CVC_C

BO_ 305 FCAM_ACC_DriveOff: 6 FCAM_C
 SG_ CRC_FCAM_ACC_DriveOff : 7|8@0+ (1,0) [0|255] ""  WCBS
 SG_ ALIVE_FCAM_ACC_DriveOff : 11|4@0+ (1,0) [0|15] ""  WCBS
 SG_ FCAM_ACC_DriveOff : 46|1@0+ (1,0) [0|1] ""  WCBS

BO_ 310 FCAM_LKA: 4 FCAM_C
 SG_ CRC_FCAM_LKA : 7|8@0+ (1,0) [0|255] ""  EPS
 SG_ ALIVE_FCAM_LKA : 11|4@0+ (1,0) [0|15] ""  EPS
 SG_ FCAM_LSS_Activation : 15|3@0+ (1,0) [0|7] ""  EPS
 SG_ FCAM_LSS_Activation_2 : 18|3@0+ (1,0) [0|7] ""  EPS
 SG_ FCAM_HapWarning : 12|1@0+ (1,0) [0|1] ""  EPS

CM_ BO_ 133 "ACU Message for crash details";
CM_ SG_ 133 CRC_ACU_CRASH_INFO "Checksum";
CM_ SG_ 133 ALIVE_ACU_CRASH_INFO "Alive Counter";
CM_ SG_ 133 ACU_Crash_Sts "Crash status";
CM_ SG_ 133 ACU_Airbag_Deployment_Status "Signal to indicate if airbag pretensioner pyrofuse is deployed";
CM_ SG_ 133 ACU_Crash_Intensity "Indicate crash intensity level";
CM_ SG_ 133 ACU_Front_Crash "Frontal collision";
CM_ SG_ 133 ACU_DriverSide_Crash "Driver's side collision";
CM_ SG_ 133 ACU_PassSide_Crash "Passenger side collision";
CM_ SG_ 133 ACU_Rear_Crash "Rear collision";
CM_ SG_ 133 ACU_Rollover_Crash "Has the vehicle experienced a rollover collision";
CM_ SG_ 169 BCMFL_AmbientTemp "Ambient temperature";
CM_ SG_ 169 BCMFL_CabinHeat_TempSensor "the Interior Temperature with Celcius Degree";
CM_ SG_ 169 BCMFL_AmbientTempSts "Environmental temperature sensor input value";
CM_ SG_ 169 BCMFL_CoolantTemp_EDS_In_Sts "Front EDS Inlet Coolant Temperature Sensor Status";
CM_ SG_ 169 BCMFL_CoolantTemp_EDS_Out_Sts "Front EDS Outlet Coolant Temperature";
CM_ SG_ 169 BCMFL_CoolantTemp_LTR_Out_Sts "LTR Outlet Coolant Temperature Sensor Status";
CM_ SG_ 169 BCMFL_ACLowSideTemperatureSts "Temperature status on the low-pressure side of the air conditioner";
CM_ SG_ 169 BCMFL_ACLowSidePressureSts "Pressure state on the low-pressure side of the air conditioner";
CM_ SG_ 169 BCMFL_ACHighSideTemperatureSts "Temperature status on the high-pressure side of the air conditioner";
CM_ SG_ 169 BCMFL_ACHighSidePressureSts "Pressure status on the high-pressure side of the air conditioner";
CM_ SG_ 169 BCMFL_CoolantTemp_HtrCore_In_Sts "Heater Core Inlet Coolant Temperature Sensor Status";
CM_ SG_ 169 BCMFL_Refrigerant_Temp_Sensor_St "Refrigerant temperature sensor status";
CM_ SG_ 169 BCMFL_PT_Sensor1_Pressure_Sts "Pressure state of pressure and temperature sensor [1]";
CM_ SG_ 169 BCMFL_PT_Sensor2_Pressure_Sts "Pressure state of pressure and temperature sensor [2]";
CM_ SG_ 201 CRC_FMCU_Status "Checksum of this message";
CM_ SG_ 201 ALIVE_FMCU_Status "Signal counting the times of this message";
CM_ SG_ 201 FMCU_MotorTq "Front Motor torque";
CM_ SG_ 201 FMCU_MotorSpd "Front Motor rotating speed";
CM_ SG_ 201 FMCU_StsMCUFault "FMCU Fault Status";
CM_ SG_ 201 FMCU_MotorSpdSts "Front Motor rotating speed Invalid";
CM_ SG_ 201 FMCU_MotorTqSts "Front Motor torque Invalid";
CM_ SG_ 201 FMCU_CVC_CtrlMode "FMCU control mode";
CM_ SG_ 201 FMCU_CVC_StsMode "FMCU Operating Mode";
CM_ SG_ 202 FMCU_CVC_PosTrqLmt "Maximum positive Torque available (motor) for Front Motor Torque requests";
CM_ SG_ 202 FMCU_CVC_NegTrqLmt "Maximum negative torque available (generator) for Front Motor Torque requests";
CM_ SG_ 202 FMCU_ActInputCurrent "Front Motor Actual input DC current";
CM_ SG_ 202 FMCU_ActInputVolt "Front Motor Actual input DC voltage";
CM_ SG_ 202 FMCU_ActInputVoltV "Front Motor Actual input DC voltage validity";
CM_ SG_ 202 FMCU_ActInputCurrentV "Front Motor Actual input DC current validity";
CM_ SG_ 203 CRC_RMCU_Status "Checksum of this message";
CM_ SG_ 203 ALIVE_RMCU_Status "Signal counting the times of this message";
CM_ SG_ 203 RMCU_MotorTq "Rear Motor torque";
CM_ SG_ 203 RMCU_MotorSpd "Rear Motor rotating speed";
CM_ SG_ 203 RMCU_StsMCUFault "RMCU Fault Status";
CM_ SG_ 203 RMCU_MotorSpdValid "Rear Motor rotating speed Invalid";
CM_ SG_ 203 RMCU_MotorTqValid "Rear Motor torque Invalid";
CM_ SG_ 203 RMCU_CVC_CtrlMode "RMCU control mode";
CM_ SG_ 203 RMCU_CVC_StsMode "RMCU Operating Mode";
CM_ SG_ 204 RMCU_CVC_PosTrqLmt "Maximum positive Torque available (motor) for rear Motor Torque requests";
CM_ SG_ 204 RMCU_CVC_NegTrqLmt "Maximum negative torque available (generator) for rear Motor Torque requests";
CM_ SG_ 204 RMCU_ActInputCurrent "rear Motor Actual input DC current";
CM_ SG_ 204 RMCU_ActInputVolt "rear Motor Actual input DC voltage";
CM_ SG_ 204 RMCU_ActInputVoltV "rear Motor Actual input DC voltage validity";
CM_ SG_ 204 RMCU_ActInputCurrentV "rear Motor Actual input DC current validity";
CM_ SG_ 217 CRC_CVC_HV_DrvSys_status "Checksum";
CM_ SG_ 217 ALIVE_CVC_HV_DrvSys_status "Alive counter";
CM_ SG_ 217 CVC_HVsystem_status "High Voltage system status";
CM_ SG_ 217 CVC_ACPD_Percent "The signal contains the actual angle of the acceleration pedal100% acceleration pedal position shall only provided in case of kick down.Without kickdown the maximum value shall be 99.";
CM_ SG_ 217 CVC_ACPD_Percent_Valid "Qualifier for corresponding signal.  In value table not defined values are reserved";
CM_ SG_ 217 CVC_ACTGear "actual gear,Provide gear shift signal";
CM_ SG_ 217 CVC_ACTGearValid "Indicate the current gear position";
CM_ SG_ 217 CVC_ACT_DriveMode "Vehicle drive mode";
CM_ SG_ 217 CVC_ACT_DriveMode_Valid "Vehicle drive mode status";
CM_ SG_ 217 CVC_HV_DRVsystem_status "Status of driving system ( Highvoltage )";
CM_ SG_ 217 CVC_Recu_BrakeLight_ON_Req "CVC request brake light ON when regen";
CM_ SG_ 217 CVC_EPB_SwitchSta "EPB Switch State";
CM_ SG_ 217 CVC_StsAccPedalFault "Accelerate pedal fault status";
CM_ SG_ 217 CVC_StsSysFault "Drive system fault level";
CM_ SG_ 217 CVC_AccPedalPosition "Accelerate pedal position";
CM_ SG_ 217 CVC_AccPedal_Valid "Accelerate pedal position signal Valid";
CM_ SG_ 252 BCMFL_WasherPumpSts "The status of the left front washing pump";
CM_ SG_ 252 BCMFL_Wiper_Front_Status "Feedback the front wiper working status";
CM_ SG_ 252 BCMFL_STAT_FrontWiperServiceMode "Feedback the front wiper service mode";
CM_ SG_ 252 BCMFL_FrontWiperStepTimeStatus "Operate wiper with delay time between each cycle and feedback to CVC";
CM_ SG_ 252 BCMFL_WiperServiceModeSts "Enable front wiper to service position and feedback to CVC";
CM_ SG_ 252 BCM_Fr_Rr_WashAndMist_Status "Front and Rear Washer and Mist function status from BCM_FL to CVC";
CM_ SG_ 252 BCMFL_InteriorTemperature "Real time temperature inside the car";
CM_ SG_ 252 WakeupForTopup_Req "Request for power replenishment";
CM_ SG_ 252 CntContWakeup "Number of awakenings";
CM_ SG_ 252 BCMFL_InteriorTemperatureSts "Real time temperature status inside the car";
CM_ SG_ 252 BCM_Front_Wiper_Park_Pos_Status "Front Wiper Park Position Status";
CM_ SG_ 252 BCM_FL_STAT_RearHeatedWindowMirr "The relevant status of the rear window heating function and the rearview mirror heating function";
CM_ SG_ 252 BCMFL_STAT_Horn "Horn output Status";
CM_ SG_ 252 BCMFL_PowerOutlet_Sts "Status Power outlet";
CM_ SG_ 264 CRC_SS_DriveReq_0x108 "Check sum";
CM_ SG_ 264 ALIVE_SS_DriveReq_0x108 "Rolling Counter";
CM_ SG_ 264 SS_P_Button "The button for the P (parking) gear position";
CM_ SG_ 264 SS_TargetGearReq "Target gear request";
CM_ SG_ 264 SS_ADAS_Req "ADAS request";
CM_ SG_ 264 SS_DrvMd_RgnLvl_Req "Driving mode request";
CM_ SG_ 264 SS_Fault "Fault status";
CM_ SG_ 264 SS_HighBeam_Req "High beam Control Request";
CM_ SG_ 264 SS_Lane_Change_Indicator_Req "Lane Change Indicator Request";
CM_ SG_ 264 SS_FR_RR_WashAndMist_Req "Front and Rear Washer and Mist function control request";
CM_ SG_ 264 SS_RR_WiperControl_Req "Rear Wiper Control Request";
CM_ SG_ 264 SS_FR_Wipercontrol_Req "Front Wiper control Request";
CM_ SG_ 266 CRC_BCM_VOLTAGE "Checksum";
CM_ SG_ 266 ALIVE_BCM_VOLTAGE "Alive counter";
CM_ SG_ 266 LV_BatteryType "LV Battery Type (Lead Acid or Lithium)";
CM_ SG_ 266 UBatt "Battery Voltage";
CM_ SG_ 266 LV_Batt_Temp_Reserved "Low voltage Battery Temperature";
CM_ SG_ 266 LV_SOC_Reserved "State Of charge for Low Voltage Battery";
CM_ SG_ 266 LV_Batt_Current_Reserved "Current of Low Voltage Battery";
CM_ SG_ 258 CRC_CVC_LOGICAL_CLAMP "Checksum";
CM_ SG_ 258 ALIVE_CVC_LOGICAL_CLAMP "Alive counter";
CM_ SG_ 258 STAT_CrankRelayHW_BCM "Represents the status of the starter relais";
CM_ SG_ 258 CVC_Transport_Mode "Transport mode shall be enable during storage or transportation with long-distance travel.";
CM_ SG_ 258 CVC_Vehicle_Special_Mode "Accessory mode of the vehicle";
CM_ SG_ 258 CVC_Acc_Mode_Req "Request vehicle into ACC state to activate HV on in some special mode/function of vehicle";
CM_ SG_ 258 CVC_CL30s_Req "Request to control ON/OFF CL30s relay";
CM_ SG_ 258 CVC_CL30c_Req "Request to control ON/OFF CL30c relay";
CM_ SG_ 258 CVC_CLR_Req "Request to control ON/OFF CLR relay";
CM_ SG_ 258 CVC_CL15_Req "Request to control ON/OFF CL15 relay";
CM_ SG_ 258 Warning_Clamp_Incompatible "Send alert to CAN in case of clamp status not the same as request";
CM_ SG_ 258 CVC_CL58_Req "Request to control ON/OFF CL58 relay";
CM_ SG_ 273 CVC_F_RegenTrqMax "Maximum recoverable torque of front axle";
CM_ SG_ 273 CVC_F_RegenTrqMaxValid "Effective position of maximum regenerative torque on the front axle";
CM_ SG_ 273 CVC_R_RegenTrqMax "Maximum recoverable torque of rear axle";
CM_ SG_ 273 CVC_R_RegenTrqMaxValid "Effective position of maximum regenerative torque on the rear axle";
CM_ SG_ 273 CVC_F_BrkRegenTrqActual "Actual braking recovery torque of front axle";
CM_ SG_ 273 CVC_R_BrkRegenTrqActual "Actual braking recovery torque of rear axle";
CM_ SG_ 273 CVC_F_BrkRegenTrqActualValid "Effective position of actual brake recovery torque on the front axle";
CM_ SG_ 273 CVC_R_BrkRegenTrqActualValid "Effective position of actual brake recovery torque on the rear axle";
CM_ SG_ 273 CVC_OnePedalModeSts "One pedal function request mode";
CM_ SG_ 273 CVC_OnePedalModeEnable "CVC OPD function enable status received by MHU";
CM_ SG_ 273 CVC_TargetBrkTq "one-pedal function to target the braking torque";
CM_ SG_ 273 CVC_OnePedal_Standstill_Req "One pedal standstill request";
CM_ SG_ 274 CRC_CVC_CLAMP_STAT "Checksum";
CM_ SG_ 274 ALIVE_CVC_CLAMP_STAT "Alive counter";
CM_ SG_ 274 RemoteFunctionState "0x1(remote function) will be sent after PreRemoteStart=0x1 first time in ignition OFF state, and this signal will be kept 0x1 until SESAM exit remote state.";
CM_ SG_ 274 CVC_STAT_BLS "Signal represent plausibility of both HW Inputs for brake light switch.";
CM_ SG_ 274 Vehicle_Operation_State "Represent the status of physical terminal";
CM_ SG_ 288 VrAccPos "Virtual throttle opening";
CM_ SG_ 288 AccPosTrq "The throttle opening corresponds to the requested torque";
CM_ SG_ 288 CVC_F_TrqCurrWhlValid "Actual effective torque position of front axle";
CM_ SG_ 288 CVC_R_TrqCurrWhlValid "Actual effective torque position of rear axle";
CM_ SG_ 288 CVC_F_TrqCurrWhl "Actual torque of front axle";
CM_ SG_ 288 CVC_R_TrqCurrWhl "Actual torque of rear axle";
CM_ SG_ 288 Driver_Accel_Pedal_Override "Driver Accelerator Pedal  Override of Longitudinal  Control System";
CM_ SG_ 288 CVC_F_AxleCoastRegenTorque "Front Axle Coasting torque value";
CM_ SG_ 288 CVC_F_AxleCoastRegenTorqueValid "Front Axle Coasting torque signal validity";
CM_ SG_ 288 CVC_R_AxleCoastRegenTorque "Rear Axle Coasting torque value";
CM_ SG_ 288 CVC_R_AxleCoastRegenTorqueValid "Rear Axle Coasting torque signal validity";
CM_ SG_ 358 CRC_CVC_Status "CRC code to check the data integrity";
CM_ SG_ 358 ALIVE_CVC_Status "signal couting the times of this message";
CM_ SG_ 358 CVC_DriveModeSts "CVC_Drive Mode Status";
CM_ SG_ 358 CVC_DriveReady "Drive ready indicator";
CM_ SG_ 358 CVC_Fault "Vehicle Fault Level";
CM_ SG_ 358 CVC_VecFltInd "Vehicle Fault Indication";
CM_ SG_ 358 CVC_Creep_Sts "Creep Status";
CM_ SG_ 358 CVC_CruiseCtrlSts "cruise control Status";
CM_ SG_ 358 CVC_StsBrakePedalSwitch "Brake pedal Switch status";
CM_ SG_ 358 CVC_VehicleMode "Vehiclemodestatus";
CM_ SG_ 358 CVC_CruiseSetSpd "Cruise set speed";
CM_ SG_ 358 CVC_CruiseFaultIndication "CVC_Cruise Fault";
CM_ SG_ 358 TRMFitted "Signal indicating that TRM is fitted or not. Signal is copy of H16 parameter in the VOD setting withing XGW";
CM_ SG_ 358 CVC_FuelDetectionSwitchState "Fuel detection switch status feedback";
CM_ SG_ 358 CVC_FuelDetectionState "Fuel detection mode";
CM_ SG_ 358 CVC_ParkingChargeRequest "Parking charging switch";
CM_ SG_ 358 CVC_ParkingChargeModeSet "Parking charging mode setting";
CM_ SG_ 524 CRC_CVC_ODO "Checksum";
CM_ SG_ 524 ALIVE_CVC_ODO "Alive Counter";
CM_ SG_ 524 CVC_Odometer "Odometer information.";
CM_ SG_ 524 CVC_OdometerV "Validity of odometer information";
CM_ SG_ 533 CRC_BMS_Sts "Checksum";
CM_ SG_ 533 ALIVE_BMS_Sts "Rolling Counter";
CM_ SG_ 533 BMS_BatBalance_ERR "Battery Balance Error indicates Balancing switch is short or open";
CM_ SG_ 533 BMS_Balance_STS "BMS Balance Status";
CM_ SG_ 533 BMS_IGN_Sts "the ignition signal status (on/off)";
CM_ SG_ 533 BMS_HWCrash_Sts "Battery Pack Hardware Crash signal Status";
CM_ SG_ 533 BMS_HVIL_STS "The HVIL state of BMS";
CM_ SG_ 533 BMS_HVOnOff_STS "Status of the High Voltage";
CM_ SG_ 533 BMS_ERR_LEV "BMS requesting CVC to operate at the limited operating strategy (LOS)";
CM_ SG_ 533 BMS_SocActual_EST "Actual SOC";
CM_ SG_ 533 BMS_Sys_STS "BMS_Status(Self-test after BMS wake-up) BMS CVC";
CM_ SG_ 533 BMS_ISU_Status "Pack Insulation Status";
CM_ SG_ 533 BMS_SOH "BMS State Of Health";
CM_ SG_ 533 BMS_SOE "BMS State Of Enegy";
CM_ SG_ 533 BMS_HV_Sts "HV Status";
CM_ SG_ 533 BMS_Display_SOC "Display SOC";
CM_ SG_ 533 BMS_SOCE "State of certified energy";
CM_ BO_ 618 "High voltage status";
CM_ SG_ 618 CRC_CVC_HV_Status "Checksum";
CM_ SG_ 618 ALIVE_CVC_HV_Status "Alive Counter";
CM_ SG_ 618 CVC_VehicleHVStatus "Vehicle High voltage Ready State";
CM_ SG_ 760 DISP_HR "The signal / parameter indicates the current hour.";
CM_ SG_ 760 DISP_MN "The signal / parameter indicates the current minute.";
CM_ SG_ 760 DISP_SEC "The signal / parameter indicates the current second.";
CM_ SG_ 760 DISP_DATE_DAY "The signal / parameter indicates the current day.";
CM_ SG_ 760 DISP_DATE_MON "The signal / parameter indicates the current month.";
CM_ SG_ 760 DISP_DATE_WDAY "The signal   parameter indicates the current day of the week.";
CM_ SG_ 760 DISP_DATE_YR "The signal / parameter indicates the current year.";
CM_ SG_ 760 ST_DISP_CTI_DATE "The signal / parameter indicates the state of the switch summer winter time.";
CM_ SG_ 788 CRC_MHU_RAEB "Checksum";
CM_ SG_ 788 ALIVE_MHU_RAEB "Alive Counter";
CM_ SG_ 788 MHU_RAEB_check "Rear Automatic Emergency Brake Check from MHU";
CM_ SG_ 788 MHU_RAEB_Warning "Rear Automatic Emergency Brake warning from MHU";
CM_ SG_ 788 MHU_RAEB_State "Rear Automatic Emergency Brake State MHU";
CM_ SG_ 788 MHU_RAEB_BrakeCommand "Deceleration command value of Rear AEB  function";
CM_ SG_ 788 MHU_RAEB_Available "RAEB Function avaiblity in MHU ECU";
CM_ SG_ 788 MHU_RAEB_FuncActive "RAEB function activation status from MHU ECU";
CM_ SG_ 788 MHU_RAEB_BrakeType "Low Speed Brake type";
CM_ SG_ 788 MHU_RAEB_PullEPBOpt "Pull EPB option for Post RAEB";
CM_ SG_ 788 MHU_RAEB_BrakeReq_Source "Function request to trigger Brake request to FAEB ( Front ACPE, FCTB, FAEB)";
CM_ SG_ 896 VIN_Byte1 "This signal contains the seventh last digit of the chassis number. (The individual digits are encoded in ASCII characters.)";
CM_ SG_ 896 VIN_Byte2 "This signal contains the sixth last digit of the chassis number. (The individual digits are encoded in ASCII characters.)";
CM_ SG_ 896 VIN_Byte3 "This signal contains the fifth last digit of the chassis number. (The individual digits are encoded in ASCII characters.)";
CM_ SG_ 896 VIN_Byte4 "This signal contains the fourth last digit of the chassis number. (The individual digits are encoded in ASCII characters.)";
CM_ SG_ 896 VIN_Byte5 "This signal contains the third last digit of the chassis number. (The individual digits are encoded in ASCII characters.)";
CM_ SG_ 896 VIN_Byte6 "This signal contains the penultimate digit of the chassis number. (The individual digits are encoded in ASCII characters.)";
CM_ SG_ 896 VIN_Byte7 "This signal contains the last digit of the chassis number. (The individual digits are encoded in ASCII characters.)";
CM_ SG_ 897 CRC_ACU_OCCUPANT_STATUS "Checksum";
CM_ SG_ 897 ALIVE_ACU_OCCUPANT_STATUS "Alive Counter";
CM_ SG_ 897 ACU_Seat_Occupancy_Passenger "Passenger seat occupancy status";
CM_ SG_ 897 ACU_Seat_Occupancy_2nd_Row_Dri "The occupancy status of the driver's side seat in the second row";
CM_ SG_ 897 ACU_Seat_Occupancy_2nd_Row_Pas "The occupancy status of the second row passenger side seat";
CM_ SG_ 897 ACU_Seat_Occupancy_2nd_Row_Mid "The occupancy status of the middle seat in the second row";
CM_ SG_ 897 ACU_Seat_Belt_Status_Passenger "The status of passenger seat belts";
CM_ SG_ 897 ACU_Seat_Belt_Status_Driver "The status of the driver's seat belt";
CM_ SG_ 897 ACU_Seat_Belt_Status_2nd_Row_Dri "The status of the driver's side seat belt in the second row";
CM_ SG_ 897 ACU_Seat_Belt_Status_2nd_Row_Mid "The status of the second row middle seat belt";
CM_ SG_ 897 ACU_Seat_Belt_Status_2nd_Row_Pas "The status of the second row passenger side seat belt";
CM_ SG_ 897 ACU_Seat_Occupancy_Driver "Driver seat occupancy status";
CM_ SG_ 996 IMU_VerticalACC_Valid "Valid flag of Vertical acceleration";
CM_ SG_ 996 IMU_VehDynPitchRate_Valid "Valid flag of Pitch Rate";
CM_ SG_ 996 IMU_VehDynRollRate_Valid "Valid flag of Roll Rate";
CM_ SG_ 996 IMU_VerticalACC "Filtered vertical acceleration";
CM_ SG_ 996 IMU_VehDynPitchRate "Filtered pitch rate";
CM_ SG_ 996 IMU_VehDynRollRate "Filtered roll rate";
CM_ SG_ 997 IMU_VerticalACCRaw_Valid "Valid flag of Vertical acceleration raw";
CM_ SG_ 997 IMU_VehDynPitchRateRaw_Valid "Valid flag of Pitch Rate raw";
CM_ SG_ 997 IMU_VehDynRollRateRaw_Valid "Valid flag of Roll Rate raw";
CM_ SG_ 997 IMU_VerticalACCRaw "Raw Vertical acceleration from sensor";
CM_ SG_ 997 IMU_VehDynPitchRateRaw "Raw Pitch Rate from sensor";
CM_ SG_ 997 IMU_VehDynRollRateRaw "Raw Roll Rate from sensor";
CM_ SG_ 998 IMU_LateralACC_Valid "Valid flag of lateral acceleration";
CM_ SG_ 998 IMU_LongitudeACC_Valid "Valid flag of longitude acceleration";
CM_ SG_ 998 IMU_VehDynYawRate_Valid "Valid flag of yaw rate";
CM_ SG_ 998 IMU_LateralACC "Filtered lateral acceleration";
CM_ SG_ 998 IMU_LongitudeACC "Filtered longitudinal acceleration";
CM_ SG_ 998 IMU_VehDynYawRate "Filtered yaw rate";
CM_ SG_ 995 IMU_LateralACCRaw_Valid "Valid flag of lateral acceleration raw";
CM_ SG_ 995 IMU_LongitudeACCRaw_Valid "Valid flag of longitude acceleration raw";
CM_ SG_ 995 IMU_VehDynYawRateRaw_Valid "Valid flag of yaw rate raw";
CM_ SG_ 995 IMU_LateralACCRaw "Raw Lateral Acceleration from sensor";
CM_ SG_ 995 IMU_LongitudeACCRaw "Raw Longitude Acceleration from sensor";
CM_ SG_ 995 IMU_VehDynYawRateRaw "Raw yaw rate from sensor";
CM_ SG_ 1037 CRC_CVC_DIGIT_SPEED "Checksum";
CM_ SG_ 1037 ALIVE_CVC_DIGIT_SPEED "Alive Counter";
CM_ SG_ 1037 CVC_DigitSpeed "This signal represents the digital speed and is displayed values between 301 and 511 are invalid.";
CM_ SG_ 1058 CRC_MHU_STATUS "Checksum";
CM_ SG_ 1058 ALIVE_MHU_STATUS "Alive Counter";
CM_ SG_ 1058 MHU_STAT_Cluster "State of Cluster screen for serving Fail-save mode";
CM_ SG_ 1058 MHU_STAT_Infotainment "State of Infotainment screen for serving Fail-save mode";
CM_ SG_ 1058 MHU_STAT_MileageUnit "Indicate current unit of mileage display in Screen (Km or Miles)";
CM_ SG_ 1058 MHU_STAT_PressureUnit "Indicate current unit of Pressure(psi, Bar, kPa)";
CM_ SG_ 1058 MHU_STAT_TemperatureUnit "Indicate current unit of Temperature (C, F)";
CM_ SG_ 1058 MHU_STAT_DateTimeFormat "Indicate current date time format (12H and 24H)";
CM_ SG_ 1058 MHU_Operation_State "Operation state of MHU";
CM_ SG_ 1058 MHU_STAT_Language "Indicate current Language";
CM_ SG_ 1058 MHU_STAT_EnergyConsumptionUnit "Indicate current unit of Enery Consumption (KWH per 100Km)";
CM_ SG_ 1058 MHU_STAT_SaleCountry "Current Sale Country by Map engine - encode by ISO 3166-1 numeric";
CM_ SG_ 1058 MHU_STAT_BatLvlPopsetting "MHU_STAT_BatLvlPopsetting";
CM_ SG_ 1058 MHU_STAT_DistToEmptyUnit "Battery unit";
CM_ SG_ 1058 MHU_DCM_Status "Indicate if there is any fault related to DCM  from MHU";
CM_ SG_ 1082 CRC_CVC_MHU_info "Checksum";
CM_ SG_ 1082 ALIVE_CVC_MHU_info "Alive counter";
CM_ SG_ 1082 CVC_BrakeRegenMode "CVC Brake regenerative mode";
CM_ SG_ 1082 CVC_CreepEnable_stt "Feedback for Creep disable request";
CM_ SG_ 1082 CVC_PowerRegenGaugeDisplay "Power Regen gauge display, plus vaue is power level, minus value is regen level.";
CM_ SG_ 1082 CVC_Regen_available "When braking / coasting regeneration system not available or regeneration system capability = 0 or regeneration system = failed.";
CM_ SG_ 1082 CVC_StoppingMode_stt "Stopping mode status";
CM_ SG_ 1082 CVC_AutoP_Feedback "CVC feedback Auto P Setting status";
CM_ SG_ 1082 CVC_SOC_display "HV battery SOC for displaying only - for CVC strategy";
CM_ SG_ 1082 CVC_Hvbatt_charging_stt "HV battery charging - not charging status,for displaying only ( for both regen/ charging )";
CM_ SG_ 1082 CVC_PreheatBatt_Sts "Preheat battery status";
CM_ SG_ 1082 CVC_HDC_Status "CVC HDC status display signal (debug)";
CM_ SG_ 1095 CRC_MHU_CarMode_Switch "Checksum";
CM_ SG_ 1095 ALIVE_MHU_CarMode_Switch "Alive counter";
CM_ SG_ 1095 MHU_AVH_Sw "Set Car Auto vehicle hold (AVH) mode";
CM_ SG_ 1095 MHU_TowingMode_Sw "Set Car towing mode";
CM_ SG_ 1095 MHU_HDC_Switch "HDC switch feedback status";
CM_ SG_ 1095 MHU_SET_WashMode "Set Car in Wash mode";
CM_ SG_ 1095 MHU_TowMode_Req "Tow Mode Set";
CM_ SG_ 1095 MHU_ESC_TCS_Switch "Select mode for WCBS";
CM_ SG_ 1095 MHU_V2LPowertrans_sts "MHU V2L Power transfer status";
CM_ SG_ 1098 CVC_WCBS_DrvIntdTorqFr "Driver intended Torque(motor end torque)";
CM_ SG_ 1098 CVC_WCBS_DrvIntdTorqRe "Driver intended torque(motor end torque)";
CM_ SG_ 1098 CVC_MaxTorq_Sts_FR "Indicate status of FR Max Driving Torque";
CM_ SG_ 1098 CVC_MinTorq_Sts_FR "Indicate status of FR Min Driving Torque";
CM_ SG_ 1098 CVC_MaxTorq_RR "RR Max Driving Torque ( instant value, wheel level, considered system status )";
CM_ SG_ 1098 CVC_MaxTorq_Sts_RR "Indicate status of RR Max Driving Torque";
CM_ SG_ 1098 CVC_MinTorq_RR "RR Min Driving Torque ( instant value, wheel level, considered system status )";
CM_ SG_ 1098 CVC_MinTorq_Sts_RR "Indicate status of RR Min Driving Torque";
CM_ SG_ 1098 CVC_WCBS_VAP_Available_Wheel_Tor "CVC Max Available Wheel Torque for Acceleration control";
CM_ SG_ 1098 CVC_WCBS_VAP_ControlResp "CVC Handshake Request Feedback";
CM_ SG_ 1098 CVC_WCBS_VAP_Available "CVC Availability for WCBS engine control";
CM_ SG_ 1098 CVC_MinTorq_FR "FR Min Driving Torque (instant value, wheel level, considered system status)";
CM_ SG_ 1098 CVC_MaxTorq_FR "FR Max Driving Torque (instant value, wheel level, considered system status)";
CM_ SG_ 1098 CVC_WCBS_APA_WheelTrq_Res "Torque flag for Park";
CM_ SG_ 1098 CVC_WCBS_VAP_FuncMode "CVC Vpark function mode active";
CM_ SG_ 1100 CVC_FMCU_demtrq "Driving Requirements Torque from CVC to MCU";
CM_ SG_ 1100 CVC_FMCU_demtrqValid "Validity bit for the signal CVC_FMCU_demtrq";
CM_ SG_ 1100 CVC_RMCU_demtrq "Driving Requirements Torque from CVC to MCU";
CM_ SG_ 1100 CVC_RMCU_demtrqValid "Validity bit for the signal CVC_RMCU_demtrq";
CM_ SG_ 1118 CRC_BCM_Heater_Feedback "Checksum";
CM_ SG_ 1118 ALIVE_BCM_Heater_Feedback "Alive Counter";
CM_ SG_ 1118 BCM_HeaterActivation_Feedback "Windshield Heater Feedback from BCM";
CM_ SG_ 1236 Body_CoverAjarStatus "Signal from Body to indicate the ajar/close status of Cover";
CM_ SG_ 1236 Body_TrunckAjarStatus "Signal from Body to indicate the ajar/close status of Truncklid";
CM_ SG_ 1236 Body_DriverSideDoorAjarSts "Signal from Body to indicate the ajar/close status of driver doo";
CM_ SG_ 1236 Body_CodriversSideDoorAjarSts "Signal from Body to indicate the ajar/close status of codrivers door";
CM_ SG_ 1236 Body_RearLeftDoorAjarStatus "Signal from Body to indicate the ajar/close status of Rear Left Door";
CM_ SG_ 1236 Body_DoorLockStatusRL "Rear Left Doo rLock Status  Reserve";
CM_ SG_ 1236 Body_DoorLockStatusRR "Rear Right Door Lock Status  Reserve";
CM_ SG_ 1236 Body_DoorLockStatusCodrivres "Codrivers Door Lock Status  Reserve";
CM_ SG_ 1236 Body_DoorLockStatusDrv "Driver Door Lock Status";
CM_ SG_ 1236 Body_RearRightDoorAjarStatus "Signal from Body to indicate the ajar/close status of Rear Right Door";
CM_ SG_ 1236 Body_ATWS_St "Body Anti thelf warning status";
CM_ SG_ 1236 Body_TailGateSts "Tail-gate Status(Low configuration)";
CM_ SG_ 1236 Body_ETGLockStatus "Signal from BCM to indicate the Lock Status of ETG";
CM_ SG_ 382 CRC_EPS_SAS_Sensor "Checksum";
CM_ SG_ 382 ALIVE_EPS_SAS_Sensor "Alive Counter";
CM_ SG_ 382 SAS_SASStsSnsr "The flag of  SAS status Punch Steering angle status";
CM_ SG_ 382 SAS_SteerWhlRotSpd "The current rotation speed of the steering wheel.";
CM_ SG_ 382 SAS_SteerWhlRotSpdStatus "The status of SteerWheelRotSpd";
CM_ SG_ 382 SAS_SASFailure "Angle sensor disabled.";
CM_ SG_ 382 SAS_Calibrated "SAS calibration state";
CM_ SG_ 382 SAS_SteerWheelAngleValid "Effective signal for steering angle";
CM_ SG_ 382 SAS_SteerWheelAngle "The current angle of the steering wheel(Positive, to left Negative, to right)";
CM_ BO_ 383 "EPS FCAM TOI";
CM_ SG_ 383 EPS_FCAM_function_feed_2 "EPS_FCAM_function_feed";
CM_ SG_ 383 EPS_FCAM_function_feed "feedback of EPS on function activation";
CM_ BO_ 796 "EPS SteeringHoldState";
CM_ SG_ 796 CRC_EPS_SteeringHoldState "Checksum.";
CM_ SG_ 796 ALIVE_EPS_SteeringHoldState "Alive Counter.";
CM_ SG_ 796 EPS_Drive_Intervention "The driver handle the Steering";
CM_ SG_ 796 EPS_TorqueLimitationState "Torque limitation state";
CM_ SG_ 796 EPS_SteerPrsnlMod "EPS system supports the function mode of driver customized steering assistance characteristics";
CM_ SG_ 796 EPS_ModChgEna "EPS system allows or prohibits switching between steering assist modes";
CM_ SG_ 796 EPS_ADAS_HndsOffDetSt "EPS Hand On Detection status base on Torque sensor algorithm";
CM_ SG_ 796 EPS_ADAS_HndsOffDetValid "EPS Hand On Detection status base on Torque sensor  Invalid or Valid";
CM_ BO_ 891 "Status from EPS to FCAM";
CM_ SG_ 891 EPS_SteeringEMTorque "Steering motor torque (Positive, to left Negative, to right)";
CM_ SG_ 891 EPS_FCAM_AOLAct "AngleOverLay Activation/Deactivation";
CM_ SG_ 891 EPS_SteeringDriverTorque "Steering driver torque (Positive, to left Negative, to right)";
CM_ SG_ 891 EPS_FCAM_TorqueBC "Boost Curve Torque from EPS";
CM_ SG_ 891 EPS_FCAM_SteeringDriverTorqueVal "Validity of Driver Steering Torque";
CM_ BO_ 894 "EPS advanced information";
CM_ SG_ 894 CRC_EPS_Advanced "Checksum";
CM_ SG_ 894 ALIVE_EPS_Advanced "Alive Counter";
CM_ SG_ 894 EPS_TorqSensorSts "Validation bit of torsion bar torque";
CM_ SG_ 894 EPS_SteeringTorque "Steering torque (Positive, to left; Negative, to right)EPS_SterringTorque = T_driver +(T_motor *Worm Gear Ratio): Total Torque on EPS";
CM_ SG_ 894 EPS_SteeringTorqueValid "validity of steering torque";
CM_ SG_ 894 EPS_Mode "Electric steering mode";
CM_ SG_ 894 EPS_Steering_angle_spd "EPS_Steering_angle_spd";
CM_ SG_ 894 EPSAngRespSts "Electric steering mode";
CM_ SG_ 894 EPS_Steering_angle "EPS steering wheel ange (Positive, to left Negative, to right)";
CM_ BO_ 1192 "EPS warning message";
CM_ SG_ 1192 CRC_EPS_WarnMsg "Checksum";
CM_ SG_ 1192 ALIVE_EPS_WarnMsg "Alive Counter";
CM_ SG_ 1192 EPS_Malfunction "EPS malfunction, No Power Assistance Steering Available";
CM_ SG_ 1192 EPS_Reduced "EPS reduced, Power Steering Assistance Reduced";
CM_ SG_ 1192 EPS_Overheat "EPS Overheat, No Power Assistance Steering Available";
CM_ SG_ 1192 EPS_NotReady "EPS is not ready, No Power Assistance Steering Available";
CM_ SG_ 1192 EPS_VEH_SPD_VALID "Validity of vehicle speed message detected by EPS";
CM_ SG_ 1192 EPS_HV_SIGNAL_EFF "The effectiveness of high-voltage signals detected by EPS";
CM_ SG_ 1192 EPS_MOS_OT_FLAG "MOS over temperature fault";
CM_ SG_ 1192 EPS_MTR_ANG_CALIB_STS "Motor angle calibration status";
CM_ SG_ 1192 EPS_FAULT_LVL "EPS fault level";
CM_ SG_ 1192 EPS_Reserved_signal2 "Warning Message Flag, Component owner, Supplier align and define for this signal";
CM_ SG_ 1192 EPS_Reserved_signal3 "Warning Message Flag, Component owner, Supplier align and define for this signal";
CM_ SG_ 1192 EPS_Reserved_signal4 "Warning Message Flag, Component owner, Supplier align and define for this signal";
CM_ SG_ 1192 EPS_Reserved_signal5 "Warning Message Flag, Component owner, Supplier align and define for this signal";
CM_ SG_ 1237 EPS_Haptic_warning_Active "EPS haptic warning function Activation";
CM_ SG_ 1237 EPS_Haptic_warning_Torque "EPS haptic warning function Torque";
CM_ SG_ 1237 EPS_Haptic_warning_Torque_valid "EPS haptic warning function Torque validity";
CM_ SG_ 1237 EPS_Haptic_warning_pattern "EPS haptic warning feedback patterns";
CM_ SG_ 1877 EPS_Return_control_Active "Steering return function Activation";
CM_ SG_ 1877 EPS_Return_control_Torque "Steering return function Torque";
CM_ SG_ 1877 EPS_Return_control_Torque_valid "Steering return function Torque validity";
CM_ SG_ 1877 EPS_Damping_control_Active "Steering handwheel damping function Activation";
CM_ SG_ 1877 EPS_Damping_control_Torque "Steering Handwheel damping function Torque";
CM_ SG_ 1877 EPS_Damping_control_Torque_valid "Steering Handwheel damping function Torque validity";
CM_ SG_ 1877 EPS_IC_Active "Inertia Compensation function Activation";
CM_ SG_ 1877 EPS_IC_Torque "Inertia Compensation function Torque";
CM_ SG_ 1877 EPS_IC_Torque_valid "Inertia Compensation function Torque validity";
CM_ SG_ 1877 EPS_Shimmy_Comp_Active "Shimmy Compensation function Activation";
CM_ SG_ 1877 EPS_Shimmy_Comp_Torque "Shimmy Compensation function Torque";
CM_ SG_ 1877 EPS_Shimmy_Comp_Torque_valid "Shimmy Compensation function Torque validity";
CM_ SG_ 1877 EPS_PDC_Active "Pull Drift Compensation function Activation";
CM_ SG_ 1877 EPS_PDC_Torque "Pull Drift Compensation function Torque";
CM_ SG_ 1877 EPS_PDC_Torque_valid "Pull Drift Compensation function Torque validity";
CM_ SG_ 1877 EPS_Yaw_Damping_control_Active "Steering Yaw damping control function Activation";
CM_ SG_ 1877 EPS_Yaw_Damping_control_Torque "Steering Yaw damping control function Torque";
CM_ SG_ 1877 EPS_Yaw_Damping_control_valid "Steering Yaw damping control function Torque validity";
CM_ SG_ 1877 EPS_FC_Active "Steering Internal Friction compensation function Activation";
CM_ SG_ 1877 EPS_FC_Torque "Steering Internal Friction compensation function Torque";
CM_ SG_ 1877 EPS_FC_Torque_valid "Steering Internal Friction compensation function Torque validity";
CM_ SG_ 1877 EPS_OP_Active "Overprotection for heat, current, voltage, etc.";
CM_ SG_ 1877 EPS_Unreduced_motor_torque_L1 "EPS System Unreduced Motor Torque for lane 1";
CM_ SG_ 1877 EPS_Unreduced_motor_torque_L2 "EPS System Unreduced Motor Torque for lane 2";
CM_ SG_ 1877 EPS_Reduced_motor_torque_L1 "EPS System reduced Motor Torque for lane 1";
CM_ SG_ 1877 EPS_Reduced_motor_torque_L2 "EPS System reduced Motor Torque for lane 2";
CM_ SG_ 1877 EPS_Max_Assist_torque_capability "EPS System Max. Motor Torque capability for lane 1";
CM_ SG_ 1877 EPS_Max_Assist_torque_capab_0000 "EPS System Max. Motor Torque capability validity for lane 1";
CM_ SG_ 1877 EPS_Max_Assist_torque_capab_0001 "EPS System Max. Motor Torque capability for lane 2";
CM_ SG_ 1877 EPS_Max_Assist_torque_capab_0002 "EPS System Max. Motor Torque capability validity for lane 2";
CM_ SG_ 1877 EPS_Operating_states "EPS operating states based on the system degradation stratergy";
CM_ SG_ 1877 EPS_TSC_Torque "Torque Steer Compensation function output torque";
CM_ SG_ 1877 EPS_TSC_Torque_valid "Torque Steer Compensation function output torque validity";
CM_ SG_ 1877 EPS_TSC_Active "Torque Steer Compensation function Activation";
CM_ SG_ 275 WCBS_R_TrqDecReq "Effective position for rear axle power torque reduction request";
CM_ SG_ 275 WCBS_R_TrqDecActive "Activation of rear axle power torque reduction request";
CM_ SG_ 275 WCBS_R_TrqIncrReq "Effective position for rear axle power torque request";
CM_ SG_ 275 WCBS_R_TrqIncrActive "Rear axle power lift torque request activated";
CM_ SG_ 275 WCBS_R_TrqDecFast "Request value for rapid torque reduction of rear axle power";
CM_ SG_ 275 WCBS_R_TrqDecSlow "Request value for slow torque reduction of rear axle power(reserved)";
CM_ SG_ 275 WCBS_R_TrqIncrFast "Request value for rapid torque increase of rear axle power";
CM_ SG_ 275 WCBS_F_TrqDecFast "Front axle power rapid torque reduction request value";
CM_ SG_ 275 WCBS_F_TrqDecReq "Front axle power torque reduction request valid position";
CM_ SG_ 275 WCBS_F_TrqDecActive "Front axle power torque reduction request activated";
CM_ SG_ 275 WCBS_F_TrqIncrReq "Front axle power torque request valid position";
CM_ SG_ 275 WCBS_F_TrqIncrActive "Front axle power torque request activated";
CM_ SG_ 275 WCBS_F_TrqIncrFast "Front axle power rapid torque request value";
CM_ BO_ 279 "EPB Brake presure";
CM_ SG_ 279 WCBS_CircuitPress "Real pressure in circuit after offset correction";
CM_ SG_ 279 WCBS_CircuitPressValid "Validity of circuit pressure";
CM_ SG_ 279 WCBS_EstWhlPress_FL "Estimated pressure at invidual wheel";
CM_ SG_ 279 WCBS_EstWhlPress_FR "Estimated pressure at invidual wheel";
CM_ SG_ 279 WCBS_EstWhlPress_RL "Estimated pressure at invidual wheel";
CM_ SG_ 279 WCBS_EstWhlPress_RR "Estimated pressure at invidual wheel";
CM_ SG_ 279 WCBS_EstWhlPressValid "Validity of wheel pressure estimation";
CM_ SG_ 279 WCBS_MainCylinderPress "Driver demand pressure";
CM_ SG_ 279 WCBS_MainCylinderPressValid "Validity of Main cylinder pressure";
CM_ SG_ 289 WCBS_RRWheelSpeedKPH "Signal from ABS to indicate the rear right wheel speed in kph";
CM_ SG_ 289 WCBS_RRWheelSpeedValid "signal to identify if the wheel speed value valid";
CM_ SG_ 289 WCBS_RRWheelDirection "indicate the rear right wheel direction";
CM_ SG_ 289 WCBS_RLWheelDirection "indicate the rear left wheel direction";
CM_ SG_ 289 WCBS_RLWheelSpeedKPH "Signal from ABS to indicate the rear left wheel speed in kph";
CM_ SG_ 289 WCBS_RLWheelSpeedValid "signal to identify if the wheel speed value valid";
CM_ SG_ 290 CRC_WCBS_WheelSpeedKPH_F "CRC code to check the data integrity";
CM_ SG_ 290 ALIVE_WCBS_WheelSpeedKPH_F "signal couting the times of this message";
CM_ SG_ 290 WCBS_FRWheelSpeedKPH "Signal from ABS to indicate the front right wheel speed in kph";
CM_ SG_ 290 WCBS_FRWheelSpeedValid "signal to identify if the wheel speed value valid";
CM_ SG_ 290 WCBS_FRWheelDirection "indicate the front right wheel direction";
CM_ SG_ 290 WCBS_FLWheelDirection "indicate the front left wheel direction";
CM_ SG_ 290 WCBS_FLWheelSpeedKPH "Signal from ABS to indicate the front left wheel speed in kph";
CM_ SG_ 290 WCBS_FLWheelSpeedValid "signal to identify if the wheel speed value valid";
CM_ SG_ 292 CRC_WCBS_WheelSpeedRC "CRC code to check the data integrity";
CM_ SG_ 292 ALIVE_WCBS_WheelSpeedRC "signal couting the times of this message";
CM_ SG_ 292 WCBS_FLWheelSpeedRCSts "Signal from ABS to indicate the front left wheel speed pulse";
CM_ SG_ 292 WCBS_RLWheelSpeedRCSts "Signal from ABS to indicate the rear left wheel speed pulse";
CM_ SG_ 292 WCBS_FRWheelSpeedRCSts "Signal from ABS to indicate the front right wheel speed pulse";
CM_ SG_ 292 WCBS_RRWheelSpeedRCSts "Signal from ABS to indicate the rear right wheel speed pulse";
CM_ SG_ 292 WCBS_RLWheelSpeedRC "Signal from ABS to indicate the rear left wheel speed pulse";
CM_ SG_ 292 WCBS_RRWheelSpeedRC "Signal from ABS to indicate the rear right wheel speed pulse";
CM_ SG_ 292 WCBS_FLWheelSpeedRC "Signal from ABS to indicate the front left wheel speed pulse";
CM_ SG_ 292 WCBS_FRWheelSpeedRC "Signal from ABS to indicate the front right wheel speed pulse";
CM_ SG_ 306 ESC_SlopeGrade "Vehicle slope,Uphill is negative (head is higher than tail), downhill is positive (tail is higher than head)";
CM_ SG_ 306 ESC_HSA_Control_Status "Indicate HSA function is active or not";
CM_ SG_ 306 ESC_HSA_Status_Fault "Detect the HAS Fault status";
CM_ SG_ 306 ESC_TcsEnableSts "Indicate the TCS function can use or not";
CM_ SG_ 306 ESC_EscCtrlActv "Indicate ESC  function is active or not";
CM_ SG_ 306 ESC_TcsCtrlActv "Indicate TCS  function is active or not";
CM_ SG_ 306 ESC_EscFlgFlt "Detect the ESC function fault status";
CM_ SG_ 306 ESC_TcsFlgFlt "Detect the TCS function fault status";
CM_ SG_ 306 ESC_EscEnableSts "Indicate the ESC function can use or not";
CM_ SG_ 306 ESC_HBAFlgFlt "Detect the HBA(Hydraulic Brake Assist) function status";
CM_ SG_ 306 ESC_HbaCtrlActv "Indicate HBA(Hydraulic Brake Assist)   function is active or not";
CM_ SG_ 306 ESC_DTC_Active "DTC active or not";
CM_ SG_ 306 ESC_BTCSCtrlActv "Indicate Brake TCS is active or not";
CM_ SG_ 306 ESC_EngineCtrlActv "ESC Engine control active status(reserved)";
CM_ BO_ 333 "Vparking torque signal from WCBS to CVC, ADCU only monitor feedback";
CM_ SG_ 333 CRC_WCBS_CVC_APA_TorqueRequest "Checksum";
CM_ SG_ 333 ALIVE_WCBS_CVC_APA_TorqueRequest "Alive counter";
CM_ SG_ 333 WCBS_APA_WheelTrq_Request "APA  Target Wheel Torque  Request";
CM_ SG_ 333 WCBS_CVC_VAP_TargetTorqRequest "APA Target wheel torque value";
CM_ SG_ 333 WCBS_CVC_VAP_Target_TorqReq_Acti "Target wheel torque effectiveness for park";
CM_ SG_ 333 WCBS_CVC_VAP_ControlReq "WCBS CVC Handshake request for torque control";
CM_ SG_ 333 WCBS_CVC_VAP_FuncMode "WCBS Vpark function mode active";
CM_ BO_ 525 "WCBS status";
CM_ SG_ 525 CRC_WCBS_STATUS "Checksum";
CM_ SG_ 525 ALIVE_WCBS_STATUS "Alive counter";
CM_ SG_ 525 ABSFailed "ABS Fault Status";
CM_ SG_ 525 ABSActive "Further details when which bit will be set are defined within attached Excel file: Functions_Interventions File is at the moment under review at Bosch WCBS side";
CM_ SG_ 525 WCBS_VehicleSpeed "Vehicle Speed";
CM_ SG_ 525 ESC_VehicleStandstill "Vehicle stationary detected";
CM_ SG_ 525 WCBS_VehicleSpeedValid "Vehicle Speed Status";
CM_ SG_ 525 ESC_VehicleHoldStat "Set if vehicle stationary for ACC is detected";
CM_ SG_ 525 ABS_EBDFailed "Signal from ABS/ABS to indicate EBD failure for driver";
CM_ SG_ 525 ABS_HAZActive "Emergency Stop Active";
CM_ SG_ 525 ABS_LowBrakeFluid "Detect the brake fluid level";
CM_ SG_ 525 EBDActive "Signal from ABS/ABS to indicate if EBD is activate or not";
CM_ SG_ 525 WCBS_Mileage "Mileage in cm";
CM_ SG_ 525 WCBS_Veh_DriveCondition "Driving Condition";
CM_ SG_ 560 CRC_WCBS_VAFS "check sum";
CM_ SG_ 560 ALIVE_WCBS_VAFS "Rolling counter";
CM_ SG_ 560 WCBS_BrkLampReq "Brake System Brake Lights Requested";
CM_ SG_ 560 EPB_SysWrnIndReq "Electric Park Brake System Warning Indication Request";
CM_ SG_ 560 EPB_SysStatIndReq "Electric Park Brake System Status Indication Request";
CM_ SG_ 560 EPB_SysDspMsgReq "Electric Park Brake System Display Message Request";
CM_ SG_ 560 EPB_Sts "Electric Park Brake Status";
CM_ SG_ 560 WCBS_TSMActive "Trailer mode Feedback";
CM_ SG_ 560 EPB_CDPActive "Indicate CDP active or not";
CM_ SG_ 560 EPB_Swch_Mafnc "EPB switch is malfunction or brakes are incoherent";
CM_ SG_ 560 WCBS_Avh_Available "AVH Availability";
CM_ SG_ 560 WCBS_AVH_DispMsg "Special message display during AVH";
CM_ SG_ 560 WCBS_AVH_Status "AVH status";
CM_ SG_ 560 WCBS_EPB_Fault "Park brake fault";
CM_ SG_ 560 WCBS_ROMActive "Roll Over Mitigation/Anti roll protection Active status";
CM_ SG_ 560 WCBS_ROMFailure "Roll Over Mitigation/Anti roll protection Failure status";
CM_ SG_ 560 WCBS_TrailerDetected "Auto detection of trailer by WCBS";
CM_ SG_ 560 WCBS_TSMFailure "Trailer Sway mitigation malfunction warning";
CM_ SG_ 560 WCBS_OnePedalAvailable "Single pedal mode available status";
CM_ SG_ 560 WCBS_BrkFricTqTotAtWhls "Total friction braking torque of the wheels";
CM_ SG_ 560 WCBS_HDCCtrlsts "HDC control status flag";
CM_ SG_ 560 WCBS_HDC_displayWarnMsg "HDC display warning message";
CM_ SG_ 560 WCBS_VehicleSteerSts "Vehicle steer status";
CM_ SG_ 560 WCBS_HDC_available "HDC Availability";
CM_ SG_ 560 WCBS_HDC_SwitchSts "HDC switch feedback status";
CM_ SG_ 560 WCBS_DTCFailure "Drag Torque Control Failure status";
CM_ SG_ 560 WCBS_TowMode_Feedback "Tow Mode Feedback";
CM_ SG_ 560 WCBS_SCM_available "SCM Availability";
CM_ SG_ 560 WCBS_OnePedal_Active "OnePedal Active flag in WCBS";
CM_ SG_ 560 WCBS_OnePedal_hold_state "whether OnePedal is on pressure hold state";
CM_ SG_ 560 WCBS_SCMActive "Indicate SCM is active or not";
CM_ SG_ 560 WCBS_CDPFailSts "Detect the CDP function fault status";
CM_ SG_ 560 WCBS_CBC_Active "CBC Active";
CM_ SG_ 560 WCBS_CBC_Available "CBC Available";
CM_ SG_ 560 WCBS_SLS_Active "SLS Active";
CM_ SG_ 560 WCBS_SLS_Available "SLS Available";
CM_ SG_ 560 WCBS_TVBB_Active "TVBB Active";
CM_ SG_ 560 WCBS_TVBB_Available "TVBB Available";
CM_ SG_ 560 WCBS_BDW_Active "BDW Active";
CM_ SG_ 560 WCBS_BDW_Available "BDW Available";
CM_ SG_ 567 EPBr_S2MMotorCurrent "ACT side caliper motor current value";
CM_ SG_ 567 EPBr_S2MPowerLatchRequest "Power latch request from ACT side PBC to prevent ESC from sleeping";
CM_ SG_ 567 EPBr_S2MYellowWarningLamp "ACT side EPB fault light";
CM_ SG_ 567 EPBr_S2MRedWarningLamp "ACT side EPB status light";
CM_ SG_ 567 EPBr_S2MApplyReleaseAvailability "ACT side H-bridge status";
CM_ SG_ 567 EPBr_S2MActuatorStateSlave "ACT side caliper status";
CM_ SG_ 567 EPBr_S2MDiagAchievedClampce "ACT side clamp clamping force";
CM_ SG_ 566 AchievedClampForce "Sum of clamping forces of left and right calipers";
CM_ SG_ 566 mot_current_L "Left caliper motor current value";
CM_ SG_ 566 mot_current_R "Right caliper motor current value";
CM_ SG_ 566 M2SApplyReleaseRequest "MOD side sends EPB request to ACT side";
CM_ SG_ 566 ActuatorStateLeft "Left caliper status";
CM_ SG_ 566 PowerLatchRequest "Power latch request from MOD side PBC to prevent ESC from entering sleep mode";
CM_ SG_ 566 ActuatorStateRight "Disk temperature overheating indicator";
CM_ SG_ 566 BrakeOverHeat "Integration status of bilateral calipers";
CM_ SG_ 566 DrumMode "MOD side EPB msg signal";
CM_ SG_ 566 HostAvailabilityLeft "Left H-bridge status";
CM_ SG_ 566 HostAvailabilityRight "Right H-bridge status";
CM_ BO_ 596 "Wheel Speed Rear";
CM_ SG_ 596 CRC_WCBS_AVL_RPM_WHL_REAR "Checksum";
CM_ SG_ 596 ALIVE_WCBS_AVL_RPM_WHL_REAR "Alive Counter";
CM_ SG_ 596 AVL_RPM_WHL_RLH "Measured speed of the rear left single wheel.";
CM_ SG_ 596 AVL_RPM_WHL_RRH "Measured speed of the rear right single wheel.";
CM_ SG_ 596 QU_AVL_RPM_WHL_RLH "status qualifier to signal actual-value_RPM_wheel_HL.";
CM_ SG_ 596 QU_AVL_RPM_WHL_RRH "status qualifier to signal actual-value_RPM_wheel_HR.";
CM_ BO_ 597 "Wheel Speed Front";
CM_ SG_ 597 CRC_WCBS_AVL_RPM_WHL_FRONT "Checksum";
CM_ SG_ 597 ALIVE_WCBS_AVL_RPM_WHL_FRONT "Alive Counter";
CM_ SG_ 597 AVL_RPM_WHL_FLH "Measured speed of the front left single wheel.";
CM_ SG_ 597 AVL_RPM_WHL_FRH "Measured speed of the front right single wheel.";
CM_ SG_ 597 QU_AVL_RPM_WHL_FLH "status qualifier to signal actual-value_RPM_wheel_VL.";
CM_ SG_ 597 QU_AVL_RPM_WHL_FRH "status qualifier to signal actual-value_RPM_wheel_VL.";
CM_ SG_ 624 WCBS_Fault_Status "Braking system fault status";
CM_ SG_ 624 WCBS_IBS_Sys_Fault_Sts "IBS sysstem fault status";
CM_ SG_ 624 WCBS_BrkPedalPct "The percent of brake pedal";
CM_ SG_ 624 WCBS_BrkPedalTravel "brake pedal travel";
CM_ SG_ 624 WCBS_BrkPedalValid "Validity of Brake pedal signals";
CM_ SG_ 624 WCBS_DiagMode "Diagnosis mode";
CM_ SG_ 624 WCBS_RollerBenchMode "Rollerbench mode active";
CM_ SG_ 624 WCBSActive "Active when any brake pressure build > threshold";
CM_ SG_ 624 WCBS_EOL_NotDone "EOL configuration is not completely done";
CM_ SG_ 624 STAT_DSC "Dynamic Stability Control status(reserved)";
CM_ SG_ 624 WCBS_BLAFlt "WCBS need to have SM implemented to detect any fault which can lead to failure in WCBS not triggering brake light activation. Part of WCBS_FSR016";
CM_ SG_ 624 FBW_WarningSts "Brake disc fading alarm status due to high temperature";
CM_ SG_ 624 Brake_Disc_Temp_FL "Estimated Brake disc temperature FL (debug only)";
CM_ SG_ 624 Brake_Disc_Temp_FR "Estimated Brake disc temperature FR (debug only)";
CM_ SG_ 624 Brake_Disc_Temp_RL "Estimated Brake disc temperature RL (debug only)";
CM_ SG_ 624 Brake_Disc_Temp_RR "Estimated Brake disc temperature RR (debug only)";
CM_ SG_ 624 WCBS_BrakesystemFailSts "Brake system Fail status";
CM_ BO_ 815 "WCBS_Info_Flag";
CM_ SG_ 815 CRC_WCBS_ADAS_Info "Checksum";
CM_ SG_ 815 ALIVE_WCBS_ADAS_Info "Alive counter";
CM_ SG_ 815 WCBS_ACC_Available_Flag "ACC available or not";
CM_ SG_ 815 WCBS_ACC_Deceleration_Flag "Deceleration flag for ACC";
CM_ SG_ 815 WCBS_ACC_Acceleration_Flag "Acceleration flag for ACC";
CM_ SG_ 815 WCBS_RAEB_Active_Flag "RAEB active or not";
CM_ SG_ 815 WCBS_RAEB_Available_Flag "RAEB available or not";
CM_ SG_ 815 WCBS_AEB_Active_Flag "AEB active or not";
CM_ SG_ 815 WCBS_AEB_Available_Flag "AEB available or not";
CM_ SG_ 815 WCBS_ACC_DriverOverride "Information of Driver pedal override.";
CM_ SG_ 815 WCBS_ACC_TargetWheel_Torque "Target wheel torque";
CM_ SG_ 815 WCBS_ACC_WheelTrq_Active "Target wheel torque effectiveness";
CM_ SG_ 866 WCBS_RBC_STS "Regen Brake Control Status";
CM_ SG_ 866 WCBS_RegenMonFail "Regenerative braking monitoring fault";
CM_ SG_ 866 WCBS_TorqReqMode "Indicate the torque request mode";
CM_ SG_ 866 WCBS_F_RegenTarTrq "Front axle target energy recovery torque (wheel end torque)";
CM_ SG_ 866 WCBS_R_RegenTarTrq "Rear axle target energy recovery torque (wheel end torque)";
CM_ SG_ 866 WCBS_F_RegenTarTrqValid "Effective position of front axle target energy recovery torque";
CM_ SG_ 866 WCBS_R_RegenTarTrqValid "Effective position of rear axle target energy recovery torque";
CM_ SG_ 866 WCBS_F_FrictionTarTrq "Friction brake calculated during Regen - Front";
CM_ SG_ 866 WCBS_R_FrictionTarTrq "Friction brake calculated during Regen - Rear";
CM_ SG_ 994 WCBS_LateralACC_Valid "Valid flag of lateral acceleration";
CM_ SG_ 994 WCBS_LongitudeACC_Valid "Valid flag of longitude acceleration";
CM_ SG_ 994 WCBS_VehDynYawRate_Valid "Valid flag of yaw rate";
CM_ SG_ 994 WCBS_LateralACC "Indicate lateral acceleration";
CM_ SG_ 994 WCBS_LongitudeACC "Indicate longitude acceleration";
CM_ SG_ 994 WCBS_VehDynYawRate "Indicate the yaw rate";
CM_ SG_ 994 WCBS_LateralACCRaw "Raw Lateral Acceleration from sensor";
CM_ SG_ 994 WCBS_LongitudeACCRaw "Raw Longitude Acceleration from sensor";
CM_ SG_ 994 WCBS_VehDynYawRateRaw "Raw yaw rate from sensor";
CM_ SG_ 994 WCBS_ESCTarYawRate "ESC target yaw rate";
CM_ SG_ 1831 WCBS_PBC_library_testm0 "Test signal, to be defined";
CM_ SG_ 1831 WCBS_PBC_library_testm1 "Test signal, to be defined";
CM_ SG_ 1831 WCBS_PBC_library_testm2 "Test signal, to be defined";
CM_ SG_ 1831 WCBS_PBC_library_testm3 "Test signal, to be defined";
CM_ SG_ 1831 WCBS_PBC_library_testm4 "Test signal, to be defined";
CM_ SG_ 1831 WCBS_PBC_library_testm5 "Test signal, to be defined";
CM_ SG_ 1831 WCBS_PBC_library_testm6 "Test signal, to be defined";
CM_ SG_ 1831 WCBS_PBC_library_testm7 "Test signal, to be defined";
CM_ SG_ 1831 WCBS_PBC_library_testm8 "Test signal, to be defined";
CM_ SG_ 1831 WCBS_PBC_library_testm9 "Test signal, to be defined";
CM_ SG_ 1831 WCBS_PBC_library_testm10 "Test signal, to be defined";
CM_ SG_ 1831 WCBS_PBC_library_testm11 "Test signal, to be defined";
CM_ SG_ 1831 WCBS_PBC_library_testm12 "Test signal, to be defined";
CM_ SG_ 1831 WCBS_PBC_library_testm13 "Test signal, to be defined";
CM_ SG_ 1831 WCBS_PBC_library_testm14 "Test signal, to be defined";
CM_ SG_ 1831 WCBS_PBC_library_testm15 "Test signal, to be defined";
CM_ SG_ 1831 WCBS_PBC_library_testm16 "Test signal, to be defined";
CM_ SG_ 1831 WCBS_PBC_library_testm17 "Test signal, to be defined";
CM_ SG_ 1831 WCBS_PBC_library_testm18 "Test signal, to be defined";
CM_ SG_ 1831 WCBS_PBC_library_testm19 "Test signal, to be defined";
CM_ SG_ 1831 WCBS_PBC_library_testm20 "Test signal, to be defined";
CM_ SG_ 1831 WCBS_PBC_library_testm21 "Test signal, to be defined";
CM_ SG_ 1831 WCBS_PBC_library_testm22 "Test signal, to be defined";
CM_ SG_ 1831 WCBS_PBC_library_testm23 "Test signal, to be defined";
CM_ SG_ 1832 WCBS_PBC_library_testa0 "Test signal, to be defined";
CM_ SG_ 1832 WCBS_PBC_library_testa1 "Test signal, to be defined";
CM_ SG_ 1832 WCBS_PBC_library_testa2 "Test signal, to be defined";
CM_ SG_ 1832 WCBS_PBC_library_testa3 "Test signal, to be defined";
CM_ SG_ 1832 WCBS_PBC_library_testa4 "Test signal, to be defined";
CM_ SG_ 1832 WCBS_PBC_library_testa5 "Test signal, to be defined";
CM_ SG_ 1832 WCBS_PBC_library_testa6 "Test signal, to be defined";
CM_ SG_ 1832 WCBS_PBC_library_testa7 "Test signal, to be defined";
CM_ SG_ 1832 WCBS_PBC_library_testa8 "Test signal, to be defined";
CM_ SG_ 1832 WCBS_PBC_library_testa9 "Test signal, to be defined";
CM_ SG_ 1832 WCBS_PBC_library_testa10 "Test signal, to be defined";
CM_ SG_ 1832 WCBS_PBC_library_testa11 "Test signal, to be defined";
CM_ SG_ 1832 WCBS_PBC_library_testa12 "Test signal, to be defined";
CM_ SG_ 1832 WCBS_PBC_library_testa13 "Test signal, to be defined";
CM_ SG_ 1832 WCBS_PBC_library_testa14 "Test signal, to be defined";
CM_ SG_ 1832 WCBS_PBC_library_testa15 "Test signal, to be defined";
CM_ SG_ 1832 WCBS_PBC_library_testa16 "Test signal, to be defined";
CM_ SG_ 1832 WCBS_PBC_library_testa17 "Test signal, to be defined";
CM_ SG_ 1832 WCBS_PBC_library_testa18 "Test signal, to be defined";
CM_ SG_ 1832 WCBS_PBC_library_testa19 "Test signal, to be defined";
CM_ SG_ 1832 WCBS_PBC_library_testa20 "Test signal, to be defined";
CM_ SG_ 1832 WCBS_PBC_library_testa21 "Test signal, to be defined";
CM_ SG_ 1832 WCBS_PBC_library_testa22 "Test signal, to be defined";
CM_ SG_ 1832 WCBS_PBC_library_testa23 "Test signal, to be defined";
CM_ SG_ 305 CRC_FCAM_ACC_DriveOff "Checksum";
CM_ SG_ 305 ALIVE_FCAM_ACC_DriveOff "Alive Counter";
CM_ SG_ 305 FCAM_ACC_DriveOff "DriveOff request flag";
CM_ BO_ 310 "FCAM Lane Keep Assist";
CM_ SG_ 310 CRC_FCAM_LKA "Checksum";
CM_ SG_ 310 ALIVE_FCAM_LKA "Alive Counter";
CM_ SG_ 310 FCAM_LSS_Activation "LSS Activation source";
CM_ SG_ 310 FCAM_LSS_Activation_2 "Supplementory Lateral control mode signal";
CM_ SG_ 310 FCAM_HapWarning "Haptic device operation command";
BA_DEF_ BO_  "DiagRequest" ENUM  "No","Yes";
BA_DEF_ BO_  "DiagResponse" ENUM  "No","Yes";
BA_DEF_ BO_  "DiagState" ENUM  "No","Yes";
BA_DEF_ BO_  "GenMsgCycleTime" INT 0 65535;
BA_DEF_ BO_  "GenMsgCycleTimeFast" INT 0 65535;
BA_DEF_ BO_  "GenMsgDelayTime" INT 0 65535;
BA_DEF_ BO_  "GenMsgILSupport" ENUM  "No","Yes";
BA_DEF_ BO_  "GenMsgNrOfRepetition" INT 0 65535;
BA_DEF_ BO_  "GenMsgSendType" ENUM  "Cyclic","NoMsgSendType","NotUsed","NotUsed","NotUsed","NotUsed","NotUsed","IfActive","NoMsgSendType","NotUsed";
BA_DEF_ BO_  "NmAsrMessage" ENUM  "No","Yes";
BA_DEF_ BO_  "NmMessage" ENUM  "No","Yes";
BA_DEF_ SG_  "GenSigSendType" ENUM  "Cyclic","NoSigSendType","OnWriteWithRepetition","OnChange","OnChangeWithRepetition","IfActive","IfActiveWithRepetition","OnWrite","NotUsed","NotUsed","NotUsed","NotUsed","NotUsed";
BA_DEF_ SG_  "GenSigStartValue" INT 0 2147483647;
BA_DEF_ SG_  "GenSigTimeoutTime_ALL" INT 0 65535;
BA_DEF_ SG_  "InvalidValue" STRING ;
BA_DEF_ SG_  "GenSigInactiveValue" INT 0 2147483647;
BA_DEF_ BU_  "ILUsed" ENUM  "No","Yes";
BA_DEF_ BU_  "NmStationAddress" HEX 0 0;
BA_DEF_ BU_  "Address" HEX 0 255;
BA_DEF_ BU_  "NmAsrCanMsgReducedTime" INT 320 640;
BA_DEF_ BU_  "NmAsrNode" ENUM  "No","Yes";
BA_DEF_ BU_  "NmAsrNodeIdentifier" HEX 0 255;
BA_DEF_ BU_  "TpSTMin" INT 0 255;
BA_DEF_  "Baudrate" INT 1000 1000000;
BA_DEF_  "BaudRateCANFD" FLOAT 1000 10000000;
BA_DEF_ BO_  "VFrameFormat" ENUM  "StandardCAN","ExtendedCAN","reserved","J1939PG","reserved","reserved","reserved","reserved","reserved","reserved","reserved","reserved","reserved","reserved","StandardCAN_FD","ExtendedCAN_FD";
BA_DEF_ BO_  "CANFD_BRS" ENUM  "0","1";
BA_DEF_  "DBName" STRING ;
BA_DEF_  "BusType" STRING ;
BA_DEF_  "Manufacturer" STRING ;
BA_DEF_  "NmAsrBaseAddress" HEX 0 2047;
BA_DEF_  "NmAsrCanMsgCycleTime" INT 0 65535;
BA_DEF_  "NmAsrMessageCount" INT 1 256;
BA_DEF_  "NmAsrRepeatMessageTime" INT 0 65535;
BA_DEF_  "NmAsrTimeoutTime" INT 0 65535;
BA_DEF_  "NmAsrWaitBusSleepTime" INT 0 65535;
BA_DEF_  "NmType" STRING ;
BA_DEF_ SG_  "SystemSignalLongSymbol" STRING ;
BA_DEF_DEF_  "DiagRequest" "No";
BA_DEF_DEF_  "DiagResponse" "No";
BA_DEF_DEF_  "DiagState" "No";
BA_DEF_DEF_  "GenMsgCycleTime" 0;
BA_DEF_DEF_  "GenMsgCycleTimeFast" 0;
BA_DEF_DEF_  "GenMsgDelayTime" 0;
BA_DEF_DEF_  "GenMsgILSupport" "Yes";
BA_DEF_DEF_  "GenMsgNrOfRepetition" 0;
BA_DEF_DEF_  "GenMsgSendType" "Cyclic";
BA_DEF_DEF_  "NmAsrMessage" "No";
BA_DEF_DEF_  "NmMessage" "No";
BA_DEF_DEF_  "GenSigSendType" "Cyclic";
BA_DEF_DEF_  "GenSigStartValue" 0;
BA_DEF_DEF_  "GenSigTimeoutTime_ALL" 0;
BA_DEF_DEF_  "InvalidValue" "";
BA_DEF_DEF_  "GenSigInactiveValue" 0;
BA_DEF_DEF_  "ILUsed" "Yes";
BA_DEF_DEF_  "NmStationAddress" 0;
BA_DEF_DEF_  "Address" 0;
BA_DEF_DEF_  "NmAsrCanMsgReducedTime" 320;
BA_DEF_DEF_  "NmAsrNode" "No";
BA_DEF_DEF_  "NmAsrNodeIdentifier" 0;
BA_DEF_DEF_  "TpSTMin" 20;
BA_DEF_DEF_  "Baudrate" 500000;
BA_DEF_DEF_  "BaudRateCANFD" 2000000;
BA_DEF_DEF_  "VFrameFormat" "StandardCAN_FD";
BA_DEF_DEF_  "CANFD_BRS" "1";
BA_DEF_DEF_  "DBName" "";
BA_DEF_DEF_  "BusType" "";
BA_DEF_DEF_  "Manufacturer" "LaunchDesign";
BA_DEF_DEF_  "NmAsrBaseAddress" 1280;
BA_DEF_DEF_  "NmAsrCanMsgCycleTime" 640;
BA_DEF_DEF_  "NmAsrMessageCount" 128;
BA_DEF_DEF_  "NmAsrRepeatMessageTime" 3200;
BA_DEF_DEF_  "NmAsrTimeoutTime" 2000;
BA_DEF_DEF_  "NmAsrWaitBusSleepTime" 1500;
BA_DEF_DEF_  "NmType" "NmAsr";
BA_DEF_DEF_  "SystemSignalLongSymbol" "";
BA_ "BusType" "CAN FD";
BA_ "Manufacturer" "VinFast";
BA_ "DBName" "CCAN";
BA_ "NmAsrNode" BU_ CVC_C 1;
BA_ "NmAsrNodeIdentifier" BU_ CVC_C 2;
BA_ "Address" BU_ CVC_C 2;
BA_ "NmStationAddress" BU_ CVC_C 2;
BA_ "NmAsrNode" BU_ EPS 1;
BA_ "NmAsrNodeIdentifier" BU_ EPS 40;
BA_ "Address" BU_ EPS 40;
BA_ "NmStationAddress" BU_ EPS 40;
BA_ "NmAsrNode" BU_ WCBS 1;
BA_ "NmAsrNodeIdentifier" BU_ WCBS 41;
BA_ "Address" BU_ WCBS 41;
BA_ "NmStationAddress" BU_ WCBS 41;
BA_ "NmAsrNode" BU_ FCAM_C 1;
BA_ "NmAsrNodeIdentifier" BU_ FCAM_C 22;
BA_ "Address" BU_ FCAM_C 22;
BA_ "NmStationAddress" BU_ FCAM_C 22;
BA_ "NmAsrNode" BU_ ADCU_C 1;
BA_ "NmAsrNodeIdentifier" BU_ ADCU_C 64;
BA_ "Address" BU_ ADCU_C 64;
BA_ "NmStationAddress" BU_ ADCU_C 64;
BA_ "GenMsgCycleTime" BO_ 133 20;
BA_ "GenMsgCycleTime" BO_ 169 100;
BA_ "GenMsgCycleTime" BO_ 201 10;
BA_ "GenMsgCycleTime" BO_ 202 10;
BA_ "GenMsgCycleTime" BO_ 203 10;
BA_ "GenMsgCycleTime" BO_ 204 10;
BA_ "GenMsgCycleTime" BO_ 217 20;
BA_ "GenMsgCycleTime" BO_ 252 100;
BA_ "GenMsgCycleTime" BO_ 264 50;
BA_ "GenMsgCycleTime" BO_ 266 100;
BA_ "GenMsgCycleTime" BO_ 258 100;
BA_ "GenMsgCycleTime" BO_ 273 10;
BA_ "GenMsgCycleTime" BO_ 274 100;
BA_ "GenMsgCycleTime" BO_ 288 20;
BA_ "GenMsgCycleTime" BO_ 358 100;
BA_ "GenMsgCycleTime" BO_ 524 100;
BA_ "GenMsgCycleTime" BO_ 533 50;
BA_ "GenMsgCycleTime" BO_ 618 40;
BA_ "GenMsgCycleTime" BO_ 645 20;
BA_ "GenMsgCycleTime" BO_ 760 1000;
BA_ "GenMsgCycleTime" BO_ 788 20;
BA_ "GenMsgCycleTime" BO_ 896 1000;
BA_ "GenMsgCycleTime" BO_ 897 40;
BA_ "GenMsgCycleTime" BO_ 996 20;
BA_ "GenMsgCycleTime" BO_ 997 10;
BA_ "GenMsgCycleTime" BO_ 998 20;
BA_ "GenMsgCycleTime" BO_ 995 10;
BA_ "GenMsgCycleTime" BO_ 1037 120;
BA_ "GenMsgCycleTime" BO_ 1058 100;
BA_ "GenMsgCycleTime" BO_ 1082 100;
BA_ "GenMsgCycleTime" BO_ 1095 200;
BA_ "GenMsgCycleTime" BO_ 1098 20;
BA_ "GenMsgCycleTime" BO_ 1100 10;
BA_ "GenMsgCycleTime" BO_ 1118 100;
BA_ "GenMsgCycleTime" BO_ 1236 100;
BA_ "GenMsgNrOfRepetition" BO_ 1968 2;
BA_ "GenMsgCycleTimeFast" BO_ 1968 50;
BA_ "GenMsgCycleTime" BO_ 1968 15000;
BA_ "GenMsgCycleTime" BO_ 382 10;
BA_ "GenMsgCycleTime" BO_ 383 20;
BA_ "GenMsgCycleTime" BO_ 646 20;
BA_ "GenMsgCycleTime" BO_ 796 10;
BA_ "GenMsgCycleTime" BO_ 891 20;
BA_ "GenMsgCycleTime" BO_ 894 10;
BA_ "GenMsgNrOfRepetition" BO_ 1192 2;
BA_ "GenMsgCycleTimeFast" BO_ 1192 100;
BA_ "GenMsgCycleTime" BO_ 1192 100;
BA_ "GenMsgCycleTime" BO_ 1237 10;
BA_ "GenMsgCycleTime" BO_ 1877 10;
BA_ "GenMsgSendType" BO_ 1975 1;
BA_ "GenMsgNrOfRepetition" BO_ 1975 2;
BA_ "GenMsgCycleTimeFast" BO_ 1975 50;
BA_ "GenMsgCycleTime" BO_ 275 10;
BA_ "GenMsgCycleTime" BO_ 279 20;
BA_ "GenMsgCycleTime" BO_ 289 20;
BA_ "GenMsgCycleTime" BO_ 290 20;
BA_ "GenMsgCycleTime" BO_ 292 20;
BA_ "GenMsgCycleTime" BO_ 306 20;
BA_ "GenMsgCycleTime" BO_ 333 20;
BA_ "GenMsgCycleTime" BO_ 525 20;
BA_ "GenMsgCycleTime" BO_ 560 40;
BA_ "GenMsgCycleTime" BO_ 567 100;
BA_ "GenMsgCycleTime" BO_ 566 100;
BA_ "GenMsgCycleTime" BO_ 596 20;
BA_ "GenMsgCycleTime" BO_ 597 20;
BA_ "GenMsgCycleTime" BO_ 624 20;
BA_ "GenMsgCycleTime" BO_ 644 20;
BA_ "GenMsgCycleTime" BO_ 815 20;
BA_ "GenMsgCycleTime" BO_ 866 10;
BA_ "GenMsgCycleTime" BO_ 994 10;
BA_ "GenMsgSendType" BO_ 1831 1;
BA_ "GenMsgSendType" BO_ 1832 1;
BA_ "GenMsgSendType" BO_ 1971 1;
BA_ "GenMsgNrOfRepetition" BO_ 1971 2;
BA_ "GenMsgCycleTimeFast" BO_ 1971 50;
BA_ "GenMsgCycleTime" BO_ 305 20;
BA_ "GenMsgCycleTime" BO_ 310 20;
BA_ "GenSigTimeoutTime_ALL" SG_ 133 CRC_ACU_CRASH_INFO 200;
BA_ "GenSigTimeoutTime_ALL" SG_ 133 ALIVE_ACU_CRASH_INFO 200;
BA_ "InvalidValue" SG_ 133 ALIVE_ACU_CRASH_INFO "Fh";
BA_ "GenSigTimeoutTime_ALL" SG_ 133 ACU_Crash_Sts 200;
BA_ "InvalidValue" SG_ 133 ACU_Crash_Sts "3h";
BA_ "GenSigTimeoutTime_ALL" SG_ 133 ACU_Airbag_Deployment_Status 200;
BA_ "InvalidValue" SG_ 133 ACU_Airbag_Deployment_Status "3h";
BA_ "GenSigTimeoutTime_ALL" SG_ 133 ACU_Crash_Intensity 200;
BA_ "InvalidValue" SG_ 133 ACU_Crash_Intensity "7h";
BA_ "GenSigTimeoutTime_ALL" SG_ 133 ACU_Front_Crash 200;
BA_ "InvalidValue" SG_ 133 ACU_Front_Crash "3h";
BA_ "GenSigTimeoutTime_ALL" SG_ 133 ACU_DriverSide_Crash 200;
BA_ "InvalidValue" SG_ 133 ACU_DriverSide_Crash "3h";
BA_ "GenSigTimeoutTime_ALL" SG_ 133 ACU_PassSide_Crash 200;
BA_ "InvalidValue" SG_ 133 ACU_PassSide_Crash "3h";
BA_ "GenSigTimeoutTime_ALL" SG_ 133 ACU_Rear_Crash 200;
BA_ "InvalidValue" SG_ 133 ACU_Rear_Crash "3h";
BA_ "GenSigTimeoutTime_ALL" SG_ 133 ACU_Rollover_Crash 200;
BA_ "InvalidValue" SG_ 133 ACU_Rollover_Crash "3h";
BA_ "InvalidValue" SG_ 169 ALIVE_BCMFL_Temperature "Fh";
BA_ "InvalidValue" SG_ 169 BCMFL_AmbientTemp "FFh";
BA_ "InvalidValue" SG_ 169 BCMFL_CabinHeat_TempSensor "FFh";
BA_ "InvalidValue" SG_ 169 BCMFL_AmbientTempSts "3h";
BA_ "InvalidValue" SG_ 169 BCMFL_CoolantTemp_EDS_In_Sts "3h";
BA_ "InvalidValue" SG_ 169 BCMFL_CoolantTemp_EDS_Out_Sts "3h";
BA_ "InvalidValue" SG_ 169 BCMFL_CoolantTemp_LTR_Out_Sts "3h";
BA_ "InvalidValue" SG_ 169 BCMFL_ACLowSideTemperatureSts "3h";
BA_ "InvalidValue" SG_ 169 BCMFL_ACLowSidePressureSts "3h";
BA_ "InvalidValue" SG_ 169 BCMFL_ACHighSideTemperatureSts "3h";
BA_ "InvalidValue" SG_ 169 BCMFL_ACHighSidePressureSts "3h";
BA_ "InvalidValue" SG_ 169 BCMFL_CoolantTemp_HtrCore_In_Sts "3h";
BA_ "InvalidValue" SG_ 169 BCMFL_Refrigerant_Temp_Sensor_St "3h";
BA_ "SystemSignalLongSymbol" SG_ 169 BCMFL_Refrigerant_Temp_Sensor_St "BCMFL_Refrigerant_Temp_Sensor_Sts";
BA_ "InvalidValue" SG_ 169 BCMFL_PT_Sensor1_Pressure_Sts "3h";
BA_ "InvalidValue" SG_ 169 BCMFL_PT_Sensor2_Pressure_Sts "3h";
BA_ "InvalidValue" SG_ 201 ALIVE_FMCU_Status "Fh";
BA_ "GenSigStartValue" SG_ 201 FMCU_MotorTq 4000;
BA_ "GenSigStartValue" SG_ 201 FMCU_MotorSpd 20000;
BA_ "InvalidValue" SG_ 201 FMCU_StsMCUFault "Fh";
BA_ "InvalidValue" SG_ 201 FMCU_MotorSpdSts "1h";
BA_ "InvalidValue" SG_ 201 FMCU_MotorTqSts "1h";
BA_ "InvalidValue" SG_ 201 FMCU_CVC_CtrlMode "Fh";
BA_ "InvalidValue" SG_ 201 FMCU_CVC_StsMode "Fh";
BA_ "InvalidValue" SG_ 202 ALIVE_FMCU_Ability "Fh";
BA_ "InvalidValue" SG_ 202 FMCU_CVC_PosTrqLmt "FFFh";
BA_ "GenSigStartValue" SG_ 202 FMCU_CVC_NegTrqLmt 4000;
BA_ "InvalidValue" SG_ 202 FMCU_CVC_NegTrqLmt "FFFh";
BA_ "GenSigStartValue" SG_ 202 FMCU_ActInputCurrent 2000;
BA_ "InvalidValue" SG_ 202 FMCU_ActInputVoltV "1h";
BA_ "InvalidValue" SG_ 202 FMCU_ActInputCurrentV "1h";
BA_ "InvalidValue" SG_ 203 ALIVE_RMCU_Status "Fh";
BA_ "GenSigStartValue" SG_ 203 RMCU_MotorTq 4000;
BA_ "GenSigStartValue" SG_ 203 RMCU_MotorSpd 20000;
BA_ "InvalidValue" SG_ 203 RMCU_StsMCUFault "Fh";
BA_ "InvalidValue" SG_ 203 RMCU_MotorSpdValid "1h";
BA_ "InvalidValue" SG_ 203 RMCU_MotorTqValid "1h";
BA_ "InvalidValue" SG_ 203 RMCU_CVC_CtrlMode "Fh";
BA_ "InvalidValue" SG_ 203 RMCU_CVC_StsMode "Fh";
BA_ "InvalidValue" SG_ 204 ALIVE_RMCU_Ability "Fh";
BA_ "InvalidValue" SG_ 204 RMCU_CVC_PosTrqLmt "FFFh";
BA_ "GenSigStartValue" SG_ 204 RMCU_CVC_NegTrqLmt 4000;
BA_ "InvalidValue" SG_ 204 RMCU_CVC_NegTrqLmt "FFFh";
BA_ "GenSigStartValue" SG_ 204 RMCU_ActInputCurrent 2000;
BA_ "InvalidValue" SG_ 204 RMCU_ActInputVoltV "1h";
BA_ "InvalidValue" SG_ 204 RMCU_ActInputCurrentV "1h";
BA_ "InvalidValue" SG_ 217 ALIVE_CVC_HV_DrvSys_status "Fh";
BA_ "InvalidValue" SG_ 217 CVC_HVsystem_status "7h";
BA_ "InvalidValue" SG_ 217 CVC_ACPD_Percent "FFFh";
BA_ "InvalidValue" SG_ 217 CVC_ACPD_Percent_Valid "1h";
BA_ "InvalidValue" SG_ 217 CVC_ACTGearValid "1h";
BA_ "InvalidValue" SG_ 217 CVC_ACT_DriveMode "7h";
BA_ "GenSigStartValue" SG_ 217 CVC_ACT_DriveMode_Valid 1;
BA_ "InvalidValue" SG_ 217 CVC_ACT_DriveMode_Valid "1h";
BA_ "InvalidValue" SG_ 217 CVC_HV_DRVsystem_status "7h";
BA_ "InvalidValue" SG_ 217 CVC_EPB_SwitchSta "3h";
BA_ "InvalidValue" SG_ 252 ALIVE_BCMFL_STAT_Control "Fh";
BA_ "InvalidValue" SG_ 252 BCMFL_STAT_FrontWiperServiceMode "3h";
BA_ "InvalidValue" SG_ 252 BCMFL_FrontWiperStepTimeStatus "FFh";
BA_ "InvalidValue" SG_ 252 BCM_Fr_Rr_WashAndMist_Status "7h";
BA_ "GenSigStartValue" SG_ 252 BCMFL_InteriorTemperature 40;
BA_ "InvalidValue" SG_ 252 BCMFL_InteriorTemperature "FFh";
BA_ "InvalidValue" SG_ 252 WakeupForTopup_Req "3h";
BA_ "InvalidValue" SG_ 252 BCMFL_InteriorTemperatureSts "3h";
BA_ "InvalidValue" SG_ 252 BCM_FL_STAT_RearHeatedWindowMirr "3h";
BA_ "SystemSignalLongSymbol" SG_ 252 BCM_FL_STAT_RearHeatedWindowMirr "BCM_FL_STAT_RearHeatedWindowMirror";
BA_ "InvalidValue" SG_ 252 BCMFL_STAT_Horn "3h";
BA_ "InvalidValue" SG_ 252 BCMFL_PowerOutlet_Sts "3h";
BA_ "InvalidValue" SG_ 264 ALIVE_SS_DriveReq_0x108 "Fh";
BA_ "InvalidValue" SG_ 264 SS_P_Button "3h";
BA_ "InvalidValue" SG_ 264 SS_TargetGearReq "7h";
BA_ "InvalidValue" SG_ 264 SS_ADAS_Req "7h";
BA_ "InvalidValue" SG_ 264 SS_DrvMd_RgnLvl_Req "3h";
BA_ "InvalidValue" SG_ 264 SS_HighBeam_Req "3h";
BA_ "InvalidValue" SG_ 264 SS_Lane_Change_Indicator_Req "7h";
BA_ "InvalidValue" SG_ 264 SS_FR_RR_WashAndMist_Req "7h";
BA_ "InvalidValue" SG_ 264 SS_RR_WiperControl_Req "3h";
BA_ "InvalidValue" SG_ 264 SS_FR_Wipercontrol_Req "4h";
BA_ "InvalidValue" SG_ 264 SS_HardNumLow "Fh";
BA_ "InvalidValue" SG_ 264 SS_HardNumHigh "Fh";
BA_ "InvalidValue" SG_ 264 SS_SoftNumLow "Fh";
BA_ "InvalidValue" SG_ 264 SS_SoftNumHigh "Fh";
BA_ "InvalidValue" SG_ 266 ALIVE_BCM_VOLTAGE "Fh";
BA_ "InvalidValue" SG_ 266 LV_BatteryType "3h";
BA_ "GenSigStartValue" SG_ 266 UBatt 9205;
BA_ "GenSigStartValue" SG_ 266 LV_Batt_Temp_Reserved 40;
BA_ "GenSigStartValue" SG_ 266 LV_Batt_Current_Reserved 49152;
BA_ "InvalidValue" SG_ 258 ALIVE_CVC_LOGICAL_CLAMP "Fh";
BA_ "InvalidValue" SG_ 258 STAT_CrankRelayHW_BCM "3h";
BA_ "InvalidValue" SG_ 258 CVC_Transport_Mode "3h";
BA_ "InvalidValue" SG_ 258 CVC_Vehicle_Special_Mode "7h";
BA_ "InvalidValue" SG_ 258 CVC_Acc_Mode_Req "3h";
BA_ "GenSigStartValue" SG_ 258 CVC_CL30s_Req 3;
BA_ "InvalidValue" SG_ 258 CVC_CL30s_Req "3h";
BA_ "GenSigStartValue" SG_ 258 CVC_CL30c_Req 3;
BA_ "InvalidValue" SG_ 258 CVC_CL30c_Req "3h";
BA_ "GenSigStartValue" SG_ 258 CVC_CLR_Req 3;
BA_ "InvalidValue" SG_ 258 CVC_CLR_Req "3h";
BA_ "GenSigStartValue" SG_ 258 CVC_CL15_Req 3;
BA_ "InvalidValue" SG_ 258 CVC_CL15_Req "3h";
BA_ "GenSigStartValue" SG_ 258 CVC_CL58_Req 3;
BA_ "InvalidValue" SG_ 258 CVC_CL58_Req "3h";
BA_ "InvalidValue" SG_ 273 ALIVE_CVC_WCBS01 "Fh";
BA_ "GenSigStartValue" SG_ 273 CVC_F_RegenTrqMax 4000;
BA_ "GenSigStartValue" SG_ 273 CVC_R_RegenTrqMax 4000;
BA_ "GenSigStartValue" SG_ 273 CVC_F_BrkRegenTrqActual 4000;
BA_ "GenSigStartValue" SG_ 273 CVC_R_BrkRegenTrqActual 4000;
BA_ "InvalidValue" SG_ 273 CVC_TargetBrkTq "FFFh";
BA_ "InvalidValue" SG_ 274 ALIVE_CVC_CLAMP_STAT "Fh";
BA_ "InvalidValue" SG_ 274 RemoteFunctionState "3h";
BA_ "InvalidValue" SG_ 274 CVC_STAT_BLS "3h";
BA_ "InvalidValue" SG_ 274 Vehicle_Operation_State "7h";
BA_ "InvalidValue" SG_ 288 ALIVE_CVC_WCBS02 "Fh";
BA_ "InvalidValue" SG_ 288 VrAccPos "FFh";
BA_ "GenSigStartValue" SG_ 288 AccPosTrq 3700;
BA_ "InvalidValue" SG_ 288 AccPosTrq "1FFFh";
BA_ "GenSigStartValue" SG_ 288 CVC_F_TrqCurrWhl 3700;
BA_ "InvalidValue" SG_ 288 CVC_F_TrqCurrWhl "1FFFh";
BA_ "GenSigStartValue" SG_ 288 CVC_R_TrqCurrWhl 3700;
BA_ "InvalidValue" SG_ 288 CVC_R_TrqCurrWhl "1FFFh";
BA_ "InvalidValue" SG_ 288 Driver_Accel_Pedal_Override "3h";
BA_ "GenSigStartValue" SG_ 288 CVC_F_AxleCoastRegenTorque 4000;
BA_ "GenSigStartValue" SG_ 288 CVC_R_AxleCoastRegenTorque 4000;
BA_ "InvalidValue" SG_ 358 ALIVE_CVC_Status "Fh";
BA_ "InvalidValue" SG_ 358 CVC_StsBrakePedalSwitch "3h";
BA_ "GenSigStartValue" SG_ 358 CVC_CruiseSetSpd 30;
BA_ "InvalidValue" SG_ 358 CVC_CruiseSetSpd "FFh";
BA_ "GenSigStartValue" SG_ 358 TRMFitted 2;
BA_ "GenSigStartValue" SG_ 358 CVC_REX_StartTimer 600;
BA_ "InvalidValue" SG_ 358 CVC_REX_StartTimer "3FFh";
BA_ "InvalidValue" SG_ 524 ALIVE_CVC_ODO "Fh";
BA_ "InvalidValue" SG_ 524 CVC_Odometer "FFFFFh";
BA_ "InvalidValue" SG_ 524 CVC_OdometerV "1h";
BA_ "InvalidValue" SG_ 533 ALIVE_BMS_Sts "Fh";
BA_ "GenSigStartValue" SG_ 533 BMS_SOH 54;
BA_ "GenSigStartValue" SG_ 533 BMS_SOE 54;
BA_ "InvalidValue" SG_ 533 BMS_HV_Sts "FFh";
BA_ "GenSigTimeoutTime_ALL" SG_ 618 CRC_CVC_HV_Status 400;
BA_ "GenSigTimeoutTime_ALL" SG_ 618 ALIVE_CVC_HV_Status 400;
BA_ "InvalidValue" SG_ 618 ALIVE_CVC_HV_Status "Fh";
BA_ "GenSigTimeoutTime_ALL" SG_ 618 CVC_VehicleHVStatus 400;
BA_ "GenSigTimeoutTime_ALL" SG_ 645 CRC_CVC_ADCU_VAP_ControlResp 100;
BA_ "GenSigTimeoutTime_ALL" SG_ 645 ALIVE_CVC_ADCU_VAP_ControlResp 100;
BA_ "InvalidValue" SG_ 645 ALIVE_CVC_ADCU_VAP_ControlResp "Fh";
BA_ "GenSigTimeoutTime_ALL" SG_ 645 CVC_ADCU_VAP_Mode 100;
BA_ "InvalidValue" SG_ 645 CVC_ADCU_VAP_Mode "Fh";
BA_ "GenSigTimeoutTime_ALL" SG_ 645 CVC_ADCU_VAP_State 100;
BA_ "InvalidValue" SG_ 645 CVC_ADCU_VAP_State "3h";
BA_ "GenSigTimeoutTime_ALL" SG_ 645 CVC_ADCU_VAP_ControlResp 100;
BA_ "InvalidValue" SG_ 645 CVC_ADCU_VAP_ControlResp "Fh";
BA_ "GenSigTimeoutTime_ALL" SG_ 645 CVC_ADCU_VAP_Available 100;
BA_ "InvalidValue" SG_ 645 CVC_ADCU_VAP_Available "1h";
BA_ "GenSigTimeoutTime_ALL" SG_ 645 CVC_ADCU_VAP_BCMAvailable 100;
BA_ "InvalidValue" SG_ 645 CVC_ADCU_VAP_BCMAvailable "1h";
BA_ "GenSigTimeoutTime_ALL" SG_ 645 CVC_ADCU_VAP_TboxAvailable 100;
BA_ "InvalidValue" SG_ 645 CVC_ADCU_VAP_TboxAvailable "1h";
BA_ "GenSigTimeoutTime_ALL" SG_ 645 CVC_ADCU_VAP_DKCUAvailable 100;
BA_ "InvalidValue" SG_ 645 CVC_ADCU_VAP_DKCUAvailable "1h";
BA_ "GenSigTimeoutTime_ALL" SG_ 645 CVC_ADCU_VAP_ACTGear 100;
BA_ "InvalidValue" SG_ 645 CVC_ADCU_VAP_ACTGear "7h";
BA_ "GenSigTimeoutTime_ALL" SG_ 645 CVC_ADCU_VAP_ACTGearValid 100;
BA_ "InvalidValue" SG_ 645 CVC_ADCU_VAP_ACTGearValid "1h";
BA_ "GenSigTimeoutTime_ALL" SG_ 645 CVC_ADCU_VAP_AcclPedalPressed 100;
BA_ "InvalidValue" SG_ 645 CVC_ADCU_VAP_AcclPedalPressed "0h";
BA_ "GenSigStartValue" SG_ 760 DISP_DATE_DAY 1;
BA_ "GenSigStartValue" SG_ 760 DISP_DATE_MON 1;
BA_ "GenSigStartValue" SG_ 760 DISP_DATE_YR 1;
BA_ "InvalidValue" SG_ 788 ALIVE_MHU_RAEB "Fh";
BA_ "InvalidValue" SG_ 788 MHU_RAEB_check "7h";
BA_ "InvalidValue" SG_ 788 MHU_RAEB_Warning "7h";
BA_ "GenSigStartValue" SG_ 788 MHU_RAEB_State 1;
BA_ "InvalidValue" SG_ 788 MHU_RAEB_State "7h";
BA_ "InvalidValue" SG_ 788 MHU_RAEB_BrakeCommand "3h";
BA_ "GenSigStartValue" SG_ 788 MHU_RAEB_Available 3;
BA_ "InvalidValue" SG_ 788 MHU_RAEB_Available "3h";
BA_ "InvalidValue" SG_ 788 MHU_RAEB_FuncActive "0h";
BA_ "GenSigStartValue" SG_ 788 MHU_RAEB_Mode_Feed 3;
BA_ "InvalidValue" SG_ 788 MHU_RAEB_Mode_Feed "3h";
BA_ "InvalidValue" SG_ 788 MHU_RAEB_BrakeType "0h";
BA_ "InvalidValue" SG_ 788 MHU_RAEB_PullEPBOpt "0h";
BA_ "GenSigSendType" SG_ 788 MHU_RAEB_BrakeReq_Source 2;
BA_ "GenSigTimeoutTime_ALL" SG_ 788 MHU_RAEB_BrakeReq_Source 1000;
BA_ "InvalidValue" SG_ 788 MHU_RAEB_BrakeReq_Source "7h";
BA_ "InvalidValue" SG_ 897 ALIVE_ACU_OCCUPANT_STATUS "Fh";
BA_ "InvalidValue" SG_ 996 ALIVE_IMU_Output2_Filtered "fh";
BA_ "GenSigStartValue" SG_ 996 IMU_VerticalACC 30000;
BA_ "InvalidValue" SG_ 996 IMU_VerticalACC "FFFFh";
BA_ "GenSigStartValue" SG_ 996 IMU_VehDynPitchRate 30000;
BA_ "InvalidValue" SG_ 996 IMU_VehDynPitchRate "FFFFh";
BA_ "GenSigStartValue" SG_ 996 IMU_VehDynRollRate 30000;
BA_ "InvalidValue" SG_ 996 IMU_VehDynRollRate "FFFFh";
BA_ "InvalidValue" SG_ 997 ALIVE_IMU_Output2_Unfiltered "fh";
BA_ "GenSigStartValue" SG_ 997 IMU_VerticalACCRaw 30000;
BA_ "InvalidValue" SG_ 997 IMU_VerticalACCRaw "FFFFh";
BA_ "GenSigStartValue" SG_ 997 IMU_VehDynPitchRateRaw 30000;
BA_ "InvalidValue" SG_ 997 IMU_VehDynPitchRateRaw "FFFFh";
BA_ "GenSigStartValue" SG_ 997 IMU_VehDynRollRateRaw 30000;
BA_ "InvalidValue" SG_ 997 IMU_VehDynRollRateRaw "FFFFh";
BA_ "InvalidValue" SG_ 998 ALIVE_IMU_Output1_Filtered "Fh";
BA_ "GenSigStartValue" SG_ 998 IMU_LateralACC 12000;
BA_ "InvalidValue" SG_ 998 IMU_LateralACC "FFFFh";
BA_ "GenSigStartValue" SG_ 998 IMU_LongitudeACC 12000;
BA_ "InvalidValue" SG_ 998 IMU_LongitudeACC "FFFFh";
BA_ "GenSigStartValue" SG_ 998 IMU_VehDynYawRate 15000;
BA_ "InvalidValue" SG_ 998 IMU_VehDynYawRate "FFFFh";
BA_ "InvalidValue" SG_ 995 ALIVE_IMU_Output1_Unfiltered "Fh";
BA_ "GenSigStartValue" SG_ 995 IMU_LateralACCRaw 30000;
BA_ "InvalidValue" SG_ 995 IMU_LateralACCRaw "FFFFh";
BA_ "GenSigStartValue" SG_ 995 IMU_LongitudeACCRaw 30000;
BA_ "InvalidValue" SG_ 995 IMU_LongitudeACCRaw "FFFFh";
BA_ "GenSigStartValue" SG_ 995 IMU_VehDynYawRateRaw 30000;
BA_ "InvalidValue" SG_ 995 IMU_VehDynYawRateRaw "FFFFh";
BA_ "InvalidValue" SG_ 1037 ALIVE_CVC_DIGIT_SPEED "Fh";
BA_ "InvalidValue" SG_ 1058 ALIVE_MHU_STATUS "Fh";
BA_ "GenSigStartValue" SG_ 1058 MHU_STAT_MileageUnit 3;
BA_ "InvalidValue" SG_ 1058 MHU_STAT_MileageUnit "3h";
BA_ "GenSigStartValue" SG_ 1058 MHU_STAT_PressureUnit 3;
BA_ "GenSigStartValue" SG_ 1058 MHU_STAT_TemperatureUnit 3;
BA_ "GenSigStartValue" SG_ 1058 MHU_STAT_DateTimeFormat 3;
BA_ "GenSigStartValue" SG_ 1058 MHU_STAT_Language 31;
BA_ "GenSigStartValue" SG_ 1058 MHU_STAT_EnergyConsumptionUnit 7;
BA_ "GenSigStartValue" SG_ 1058 MHU_STAT_SaleCountry 1023;
BA_ "InvalidValue" SG_ 1058 MHU_DCM_Status "0h";
BA_ "InvalidValue" SG_ 1082 ALIVE_CVC_MHU_info "Fh";
BA_ "GenSigStartValue" SG_ 1082 CVC_PowerRegenGaugeDisplay 100;
BA_ "GenSigStartValue" SG_ 1082 CVC_Regen_available 1;
BA_ "InvalidValue" SG_ 1082 CVC_StoppingMode_stt "7h";
BA_ "GenSigTimeoutTime_ALL" SG_ 1082 CVC_HDC_Status 1000;
BA_ "InvalidValue" SG_ 1082 CVC_HDC_Status "7h";
BA_ "GenSigTimeoutTime_ALL" SG_ 1095 CRC_MHU_CarMode_Switch 400;
BA_ "GenSigTimeoutTime_ALL" SG_ 1095 ALIVE_MHU_CarMode_Switch 400;
BA_ "InvalidValue" SG_ 1095 ALIVE_MHU_CarMode_Switch "Fh";
BA_ "GenSigTimeoutTime_ALL" SG_ 1095 MHU_AVH_Sw 400;
BA_ "GenSigTimeoutTime_ALL" SG_ 1095 MHU_TowingMode_Sw 400;
BA_ "GenSigTimeoutTime_ALL" SG_ 1095 MHU_HDC_Switch 400;
BA_ "InvalidValue" SG_ 1095 MHU_HDC_Switch "3h";
BA_ "GenSigTimeoutTime_ALL" SG_ 1095 MHU_SET_WashMode 400;
BA_ "InvalidValue" SG_ 1095 MHU_SET_WashMode "3h";
BA_ "GenSigTimeoutTime_ALL" SG_ 1095 MHU_ESC_TCS_Switch 200;
BA_ "InvalidValue" SG_ 1095 MHU_ESC_TCS_Switch "3h";
BA_ "GenSigTimeoutTime_ALL" SG_ 1095 MHU_V2LPowertrans_sts 200;
BA_ "GenSigTimeoutTime_ALL" SG_ 1098 CRC_CVC_WCBS_Control 200;
BA_ "GenSigTimeoutTime_ALL" SG_ 1098 ALIVE_CVC_WCBS_Control 200;
BA_ "InvalidValue" SG_ 1098 ALIVE_CVC_WCBS_Control "Fh";
BA_ "GenSigTimeoutTime_ALL" SG_ 1098 CVC_WCBS_DrvIntdTorqFr 200;
BA_ "GenSigStartValue" SG_ 1098 CVC_WCBS_DrvIntdTorqFr 8000;
BA_ "InvalidValue" SG_ 1098 CVC_WCBS_DrvIntdTorqFr "3FFFh";
BA_ "GenSigTimeoutTime_ALL" SG_ 1098 CVC_WCBS_DrvIntdTorqRe 200;
BA_ "GenSigStartValue" SG_ 1098 CVC_WCBS_DrvIntdTorqRe 8000;
BA_ "GenSigTimeoutTime_ALL" SG_ 1098 CVC_MaxTorq_Sts_FR 200;
BA_ "GenSigTimeoutTime_ALL" SG_ 1098 CVC_MinTorq_Sts_FR 200;
BA_ "GenSigTimeoutTime_ALL" SG_ 1098 CVC_MaxTorq_RR 200;
BA_ "GenSigStartValue" SG_ 1098 CVC_MaxTorq_RR 8000;
BA_ "GenSigTimeoutTime_ALL" SG_ 1098 CVC_MaxTorq_Sts_RR 200;
BA_ "GenSigTimeoutTime_ALL" SG_ 1098 CVC_MinTorq_RR 200;
BA_ "GenSigStartValue" SG_ 1098 CVC_MinTorq_RR 8000;
BA_ "GenSigTimeoutTime_ALL" SG_ 1098 CVC_MinTorq_Sts_RR 200;
BA_ "GenSigTimeoutTime_ALL" SG_ 1098 CVC_WCBS_VAP_Available_Wheel_Tor 200;
BA_ "GenSigStartValue" SG_ 1098 CVC_WCBS_VAP_Available_Wheel_Tor 8000;
BA_ "InvalidValue" SG_ 1098 CVC_WCBS_VAP_Available_Wheel_Tor "3FFFh";
BA_ "SystemSignalLongSymbol" SG_ 1098 CVC_WCBS_VAP_Available_Wheel_Tor "CVC_WCBS_VAP_Available_Wheel_Torque";
BA_ "GenSigTimeoutTime_ALL" SG_ 1098 CVC_WCBS_VAP_ControlResp 200;
BA_ "GenSigTimeoutTime_ALL" SG_ 1098 CVC_WCBS_VAP_Available 200;
BA_ "GenSigTimeoutTime_ALL" SG_ 1098 CVC_MinTorq_FR 200;
BA_ "GenSigStartValue" SG_ 1098 CVC_MinTorq_FR 8000;
BA_ "InvalidValue" SG_ 1098 CVC_MinTorq_FR "3FFFh";
BA_ "GenSigTimeoutTime_ALL" SG_ 1098 CVC_MaxTorq_FR 200;
BA_ "GenSigStartValue" SG_ 1098 CVC_MaxTorq_FR 8000;
BA_ "InvalidValue" SG_ 1098 CVC_MaxTorq_FR "3FFFh";
BA_ "GenSigTimeoutTime_ALL" SG_ 1098 CVC_WCBS_APA_WheelTrq_Res 200;
BA_ "GenSigTimeoutTime_ALL" SG_ 1098 CVC_WCBS_VAP_FuncMode 200;
BA_ "InvalidValue" SG_ 1098 CVC_WCBS_VAP_FuncMode "Fh";
BA_ "InvalidValue" SG_ 1100 ALIVE_CVC_EDS_Control "Fh";
BA_ "GenSigTimeoutTime_ALL" SG_ 1118 CRC_BCM_Heater_Feedback 1000;
BA_ "GenSigTimeoutTime_ALL" SG_ 1118 ALIVE_BCM_Heater_Feedback 1000;
BA_ "InvalidValue" SG_ 1118 ALIVE_BCM_Heater_Feedback "Fh";
BA_ "GenSigTimeoutTime_ALL" SG_ 1118 BCM_HeaterActivation_Feedback 1000;
BA_ "InvalidValue" SG_ 1118 BCM_HeaterActivation_Feedback "0h";
BA_ "InvalidValue" SG_ 1236 Body_DriverSideDoorAjarSts "3h";
BA_ "InvalidValue" SG_ 1236 Body_CodriversSideDoorAjarSts "3h";
BA_ "InvalidValue" SG_ 1236 Body_RearLeftDoorAjarStatus "3h";
BA_ "InvalidValue" SG_ 1236 Body_RearRightDoorAjarStatus "3h";
BA_ "InvalidValue" SG_ 1236 Body_ETGLockStatus "3h";
BA_ "GenSigSendType" SG_ 1968 Sync_TripCnt 2;
BA_ "GenSigSendType" SG_ 1968 Sync_ResetCnt 2;
BA_ "GenSigSendType" SG_ 1968 Sync_MAC 2;
BA_ "InvalidValue" SG_ 382 ALIVE_EPS_SAS_Sensor "Fh";
BA_ "GenSigStartValue" SG_ 382 SAS_SteerWhlRotSpd 8000;
BA_ "InvalidValue" SG_ 383 ALIVE_EPS_FCAM_TOI "Fh";
BA_ "GenSigTimeoutTime_ALL" SG_ 383 EPS_FCAM_function_feed_2 200;
BA_ "InvalidValue" SG_ 383 EPS_FCAM_function_feed_2 "7h";
BA_ "GenSigTimeoutTime_ALL" SG_ 383 EPS_FCAM_function_feed 200;
BA_ "InvalidValue" SG_ 383 EPS_FCAM_function_feed "7h";
BA_ "GenSigTimeoutTime_ALL" SG_ 646 CRC_EPS_ADCU_VAP_Resp 100;
BA_ "GenSigTimeoutTime_ALL" SG_ 646 ALIVE_EPS_ADCU_VAP_Resp 100;
BA_ "InvalidValue" SG_ 646 ALIVE_EPS_ADCU_VAP_Resp "Fh";
BA_ "GenSigTimeoutTime_ALL" SG_ 646 EPS_ADCU_VAP_Mode 100;
BA_ "InvalidValue" SG_ 646 EPS_ADCU_VAP_Mode "Fh";
BA_ "GenSigTimeoutTime_ALL" SG_ 646 EPS_ADCU_VAP_State 100;
BA_ "InvalidValue" SG_ 646 EPS_ADCU_VAP_State "3h";
BA_ "GenSigTimeoutTime_ALL" SG_ 646 EPS_ADCU_VAP_ControlResp 100;
BA_ "InvalidValue" SG_ 646 EPS_ADCU_VAP_ControlResp "Fh";
BA_ "GenSigTimeoutTime_ALL" SG_ 646 EPS_ADCU_VAP_Available 100;
BA_ "InvalidValue" SG_ 646 EPS_ADCU_VAP_Available "1h";
BA_ "GenSigTimeoutTime_ALL" SG_ 646 EPS_ADCU_VAP_SteerWheelAngle 100;
BA_ "InvalidValue" SG_ 646 EPS_ADCU_VAP_SteerWheelAngle "0h";
BA_ "GenSigTimeoutTime_ALL" SG_ 646 EPS_ADCU_VAP_SteerAngleValid 100;
BA_ "InvalidValue" SG_ 646 EPS_ADCU_VAP_SteerAngleValid "1h";
BA_ "GenSigTimeoutTime_ALL" SG_ 646 EPS_ADCU_VAP_SteerIntervention 100;
BA_ "InvalidValue" SG_ 646 EPS_ADCU_VAP_SteerIntervention "0h";
BA_ "GenSigTimeoutTime_ALL" SG_ 796 CRC_EPS_SteeringHoldState 100;
BA_ "GenSigTimeoutTime_ALL" SG_ 796 ALIVE_EPS_SteeringHoldState 100;
BA_ "InvalidValue" SG_ 796 ALIVE_EPS_SteeringHoldState "Fh";
BA_ "GenSigTimeoutTime_ALL" SG_ 796 EPS_Drive_Intervention 100;
BA_ "GenSigTimeoutTime_ALL" SG_ 796 EPS_TorqueLimitationState 100;
BA_ "InvalidValue" SG_ 796 EPS_TorqueLimitationState "1h";
BA_ "InvalidValue" SG_ 796 EPS_SteerPrsnlMod "7h";
BA_ "GenSigTimeoutTime_ALL" SG_ 796 EPS_ADAS_HndsOffDetSt 100;
BA_ "InvalidValue" SG_ 796 EPS_ADAS_HndsOffDetSt "0h";
BA_ "GenSigTimeoutTime_ALL" SG_ 796 EPS_ADAS_HndsOffDetValid 100;
BA_ "InvalidValue" SG_ 796 EPS_ADAS_HndsOffDetValid "1h";
BA_ "InvalidValue" SG_ 891 ALIVE_EPS_FCAM_Steering_Trq "Fh";
BA_ "GenSigTimeoutTime_ALL" SG_ 891 EPS_SteeringEMTorque 200;
BA_ "GenSigStartValue" SG_ 891 EPS_SteeringEMTorque 1024;
BA_ "InvalidValue" SG_ 891 EPS_SteeringEMTorque "FFFh";
BA_ "GenSigTimeoutTime_ALL" SG_ 891 EPS_FCAM_AOLAct 200;
BA_ "GenSigTimeoutTime_ALL" SG_ 891 EPS_SteeringDriverTorque 200;
BA_ "GenSigStartValue" SG_ 891 EPS_SteeringDriverTorque 1024;
BA_ "InvalidValue" SG_ 891 EPS_SteeringDriverTorque "FFFh";
BA_ "GenSigTimeoutTime_ALL" SG_ 891 EPS_FCAM_Steering_Trq 200;
BA_ "GenSigStartValue" SG_ 891 EPS_FCAM_Steering_Trq 40000;
BA_ "GenSigTimeoutTime_ALL" SG_ 891 EPS_FCAMADCUAdded_Steering_Trq 200;
BA_ "GenSigStartValue" SG_ 891 EPS_FCAMADCUAdded_Steering_Trq 40000;
BA_ "GenSigTimeoutTime_ALL" SG_ 891 EPS_FCAM_TorqueBC 100;
BA_ "GenSigStartValue" SG_ 891 EPS_FCAM_TorqueBC 40000;
BA_ "InvalidValue" SG_ 891 EPS_FCAM_TorqueBC "0h";
BA_ "GenSigTimeoutTime_ALL" SG_ 891 EPS_FCAM_SteeringDriverTorqueVal 100;
BA_ "InvalidValue" SG_ 891 EPS_FCAM_SteeringDriverTorqueVal "3h";
BA_ "SystemSignalLongSymbol" SG_ 891 EPS_FCAM_SteeringDriverTorqueVal "EPS_FCAM_SteeringDriverTorqueValid";
BA_ "GenSigTimeoutTime_ALL" SG_ 894 CRC_EPS_Advanced 100;
BA_ "GenSigTimeoutTime_ALL" SG_ 894 ALIVE_EPS_Advanced 100;
BA_ "InvalidValue" SG_ 894 ALIVE_EPS_Advanced "Fh";
BA_ "GenSigTimeoutTime_ALL" SG_ 894 EPS_TorqSensorSts 100;
BA_ "GenSigTimeoutTime_ALL" SG_ 894 EPS_SteeringTorque 100;
BA_ "GenSigStartValue" SG_ 894 EPS_SteeringTorque 1000;
BA_ "InvalidValue" SG_ 894 EPS_SteeringTorque "FFFh";
BA_ "GenSigTimeoutTime_ALL" SG_ 894 EPS_SteeringTorqueValid 100;
BA_ "GenSigTimeoutTime_ALL" SG_ 894 EPS_Mode 100;
BA_ "InvalidValue" SG_ 894 EPS_Mode "3h";
BA_ "GenSigTimeoutTime_ALL" SG_ 894 EPS_Steering_angle_spd 100;
BA_ "GenSigStartValue" SG_ 894 EPS_Steering_angle_spd 8000;
BA_ "InvalidValue" SG_ 894 EPS_Steering_angle_spd "3FFFh";
BA_ "GenSigTimeoutTime_ALL" SG_ 894 EPSAngRespSts 100;
BA_ "InvalidValue" SG_ 894 EPSAngRespSts "3h";
BA_ "GenSigTimeoutTime_ALL" SG_ 894 EPS_Steering_angle 100;
BA_ "InvalidValue" SG_ 894 EPS_Steering_angle "FFFFh";
BA_ "GenSigTimeoutTime_ALL" SG_ 894 EPS_Steering_angle_spdValid 100;
BA_ "GenSigTimeoutTime_ALL" SG_ 894 EPS_Steering_angleValid 100;
BA_ "GenSigTimeoutTime_ALL" SG_ 1192 CRC_EPS_WarnMsg 5000;
BA_ "GenSigTimeoutTime_ALL" SG_ 1192 ALIVE_EPS_WarnMsg 5000;
BA_ "InvalidValue" SG_ 1192 ALIVE_EPS_WarnMsg "Fh";
BA_ "GenSigSendType" SG_ 1192 EPS_Malfunction 4;
BA_ "GenSigTimeoutTime_ALL" SG_ 1192 EPS_Malfunction 5000;
BA_ "GenSigSendType" SG_ 1192 EPS_Reduced 4;
BA_ "GenSigTimeoutTime_ALL" SG_ 1192 EPS_Reduced 5000;
BA_ "GenSigSendType" SG_ 1192 EPS_Overheat 4;
BA_ "GenSigTimeoutTime_ALL" SG_ 1192 EPS_Overheat 5000;
BA_ "GenSigSendType" SG_ 1192 EPS_NotReady 4;
BA_ "GenSigTimeoutTime_ALL" SG_ 1192 EPS_NotReady 5000;
BA_ "GenSigSendType" SG_ 1192 EPS_VEH_SPD_VALID 4;
BA_ "GenSigTimeoutTime_ALL" SG_ 1192 EPS_VEH_SPD_VALID 5000;
BA_ "GenSigSendType" SG_ 1192 EPS_HV_SIGNAL_EFF 4;
BA_ "GenSigTimeoutTime_ALL" SG_ 1192 EPS_HV_SIGNAL_EFF 5000;
BA_ "GenSigSendType" SG_ 1192 EPS_MOS_OT_FLAG 4;
BA_ "GenSigTimeoutTime_ALL" SG_ 1192 EPS_MOS_OT_FLAG 5000;
BA_ "GenSigSendType" SG_ 1192 EPS_MTR_ANG_CALIB_STS 4;
BA_ "GenSigTimeoutTime_ALL" SG_ 1192 EPS_MTR_ANG_CALIB_STS 5000;
BA_ "GenSigSendType" SG_ 1192 EPS_FAULT_LVL 4;
BA_ "GenSigTimeoutTime_ALL" SG_ 1192 EPS_FAULT_LVL 5000;
BA_ "GenSigSendType" SG_ 1192 EPS_Reserved_signal2 4;
BA_ "GenSigTimeoutTime_ALL" SG_ 1192 EPS_Reserved_signal2 5000;
BA_ "GenSigSendType" SG_ 1192 EPS_Reserved_signal3 4;
BA_ "GenSigTimeoutTime_ALL" SG_ 1192 EPS_Reserved_signal3 5000;
BA_ "GenSigSendType" SG_ 1192 EPS_Reserved_signal4 4;
BA_ "GenSigTimeoutTime_ALL" SG_ 1192 EPS_Reserved_signal4 5000;
BA_ "GenSigSendType" SG_ 1192 EPS_Reserved_signal5 4;
BA_ "GenSigTimeoutTime_ALL" SG_ 1192 EPS_Reserved_signal5 5000;
BA_ "InvalidValue" SG_ 1237 ALIVE_EPS_Haptic_warning "Fh";
BA_ "InvalidValue" SG_ 1237 EPS_Haptic_warning_pattern "7h";
BA_ "InvalidValue" SG_ 1877 EPS_Unreduced_motor_torque_L1 "FFFh";
BA_ "InvalidValue" SG_ 1877 EPS_Unreduced_motor_torque_L2 "FFFh";
BA_ "InvalidValue" SG_ 1877 EPS_Reduced_motor_torque_L1 "FFFh";
BA_ "InvalidValue" SG_ 1877 EPS_Reduced_motor_torque_L2 "FFFh";
BA_ "InvalidValue" SG_ 1877 EPS_Operating_states "7h";
BA_ "GenSigSendType" SG_ 1975 EPS_Req_RandomData 2;
BA_ "GenSigSendType" SG_ 1975 EPS_Req_MAC 2;
BA_ "InvalidValue" SG_ 275 ALIVE_WCBS_ESCTrqReq "Fh";
BA_ "GenSigStartValue" SG_ 275 WCBS_R_TrqDecFast 4000;
BA_ "InvalidValue" SG_ 275 WCBS_R_TrqDecFast "FFFFh";
BA_ "GenSigStartValue" SG_ 275 WCBS_R_TrqIncrFast 4000;
BA_ "InvalidValue" SG_ 275 WCBS_R_TrqIncrFast "FFFFh";
BA_ "GenSigStartValue" SG_ 275 WCBS_F_TrqDecFast 4000;
BA_ "InvalidValue" SG_ 275 WCBS_F_TrqDecFast "FFFFh";
BA_ "GenSigStartValue" SG_ 275 WCBS_F_TrqIncrFast 4000;
BA_ "InvalidValue" SG_ 275 WCBS_F_TrqIncrFast "FFFFh";
BA_ "InvalidValue" SG_ 279 ALIVE_WCBS_Pressure "Fh";
BA_ "InvalidValue" SG_ 279 WCBS_EstWhlPress_FL "7FFFh";
BA_ "InvalidValue" SG_ 279 WCBS_EstWhlPress_FR "7FFFh";
BA_ "InvalidValue" SG_ 279 WCBS_EstWhlPress_RL "7FFFh";
BA_ "InvalidValue" SG_ 279 WCBS_EstWhlPress_RR "7FFFh";
BA_ "InvalidValue" SG_ 289 ALIVE_WCBS_WheelSpeedKPH_R "Fh";
BA_ "InvalidValue" SG_ 289 WCBS_RRWheelSpeedKPH "1FFFh";
BA_ "InvalidValue" SG_ 289 WCBS_RLWheelSpeedKPH "1FFFh";
BA_ "InvalidValue" SG_ 290 ALIVE_WCBS_WheelSpeedKPH_F "Fh";
BA_ "InvalidValue" SG_ 290 WCBS_FRWheelSpeedKPH "1FFFh";
BA_ "InvalidValue" SG_ 290 WCBS_FLWheelSpeedKPH "1FFFh";
BA_ "InvalidValue" SG_ 292 ALIVE_WCBS_WheelSpeedRC "Fh";
BA_ "InvalidValue" SG_ 292 WCBS_FLWheelSpeedRCSts "1h";
BA_ "InvalidValue" SG_ 292 WCBS_RLWheelSpeedRCSts "1h";
BA_ "InvalidValue" SG_ 292 WCBS_FRWheelSpeedRCSts "1h";
BA_ "InvalidValue" SG_ 292 WCBS_RRWheelSpeedRCSts "1h";
BA_ "InvalidValue" SG_ 292 WCBS_RLWheelSpeedRC "-";
BA_ "InvalidValue" SG_ 292 WCBS_RRWheelSpeedRC "-";
BA_ "InvalidValue" SG_ 292 WCBS_FLWheelSpeedRC "-";
BA_ "InvalidValue" SG_ 292 WCBS_FRWheelSpeedRC "-";
BA_ "InvalidValue" SG_ 306 ALIVE_WCBS_ESC_Status "Fh";
BA_ "InvalidValue" SG_ 306 ESC_SlopeGrade "FFh";
BA_ "GenSigTimeoutTime_ALL" SG_ 333 CRC_WCBS_CVC_APA_TorqueRequest 200;
BA_ "GenSigTimeoutTime_ALL" SG_ 333 ALIVE_WCBS_CVC_APA_TorqueRequest 200;
BA_ "InvalidValue" SG_ 333 ALIVE_WCBS_CVC_APA_TorqueRequest "Fh";
BA_ "GenSigTimeoutTime_ALL" SG_ 333 WCBS_APA_WheelTrq_Request 200;
BA_ "GenSigTimeoutTime_ALL" SG_ 333 WCBS_CVC_VAP_TargetTorqRequest 200;
BA_ "GenSigTimeoutTime_ALL" SG_ 333 WCBS_CVC_VAP_Target_TorqReq_Acti 200;
BA_ "SystemSignalLongSymbol" SG_ 333 WCBS_CVC_VAP_Target_TorqReq_Acti "WCBS_CVC_VAP_Target_TorqReq_Active";
BA_ "GenSigTimeoutTime_ALL" SG_ 333 WCBS_CVC_VAP_ControlReq 200;
BA_ "GenSigTimeoutTime_ALL" SG_ 333 WCBS_CVC_VAP_FuncMode 200;
BA_ "InvalidValue" SG_ 333 WCBS_CVC_VAP_FuncMode "Fh";
BA_ "GenSigTimeoutTime_ALL" SG_ 525 CRC_WCBS_STATUS 200;
BA_ "GenSigTimeoutTime_ALL" SG_ 525 ALIVE_WCBS_STATUS 200;
BA_ "InvalidValue" SG_ 525 ALIVE_WCBS_STATUS "Fh";
BA_ "GenSigTimeoutTime_ALL" SG_ 525 ABSFailed 200;
BA_ "GenSigTimeoutTime_ALL" SG_ 525 ABSActive 200;
BA_ "GenSigTimeoutTime_ALL" SG_ 525 WCBS_VehicleSpeed 200;
BA_ "GenSigTimeoutTime_ALL" SG_ 525 ESC_VehicleStandstill 200;
BA_ "GenSigTimeoutTime_ALL" SG_ 525 WCBS_VehicleSpeedValid 200;
BA_ "GenSigTimeoutTime_ALL" SG_ 525 ESC_VehicleHoldStat 200;
BA_ "InvalidValue" SG_ 525 WCBS_Veh_DriveCondition "7h";
BA_ "GenSigTimeoutTime_ALL" SG_ 560 CRC_WCBS_VAFS 400;
BA_ "GenSigTimeoutTime_ALL" SG_ 560 ALIVE_WCBS_VAFS 400;
BA_ "InvalidValue" SG_ 560 ALIVE_WCBS_VAFS "Fh";
BA_ "GenSigTimeoutTime_ALL" SG_ 560 WCBS_BrkLampReq 400;
BA_ "GenSigTimeoutTime_ALL" SG_ 560 EPB_SysWrnIndReq 400;
BA_ "GenSigTimeoutTime_ALL" SG_ 560 EPB_SysStatIndReq 400;
BA_ "GenSigTimeoutTime_ALL" SG_ 560 EPB_SysDspMsgReq 400;
BA_ "GenSigTimeoutTime_ALL" SG_ 560 EPB_Sts 400;
BA_ "InvalidValue" SG_ 560 EPB_Sts "7h";
BA_ "GenSigTimeoutTime_ALL" SG_ 560 WCBS_TSMActive 400;
BA_ "GenSigTimeoutTime_ALL" SG_ 560 EPB_CDPActive 400;
BA_ "InvalidValue" SG_ 560 EPB_CDPActive "Fh";
BA_ "GenSigTimeoutTime_ALL" SG_ 560 EPB_Swch_Mafnc 400;
BA_ "GenSigTimeoutTime_ALL" SG_ 560 WCBS_Avh_Available 400;
BA_ "GenSigTimeoutTime_ALL" SG_ 560 WCBS_AVH_DispMsg 400;
BA_ "GenSigTimeoutTime_ALL" SG_ 560 WCBS_AVH_Status 400;
BA_ "InvalidValue" SG_ 560 WCBS_AVH_Status "Fh";
BA_ "GenSigTimeoutTime_ALL" SG_ 560 WCBS_EPB_Fault 400;
BA_ "GenSigTimeoutTime_ALL" SG_ 560 WCBS_ROMActive 400;
BA_ "GenSigTimeoutTime_ALL" SG_ 560 WCBS_ROMFailure 400;
BA_ "GenSigTimeoutTime_ALL" SG_ 560 WCBS_TrailerDetected 400;
BA_ "GenSigTimeoutTime_ALL" SG_ 560 WCBS_TSMFailure 400;
BA_ "GenSigTimeoutTime_ALL" SG_ 560 WCBS_OnePedalAvailable 400;
BA_ "GenSigTimeoutTime_ALL" SG_ 560 WCBS_BrkFricTqTotAtWhls 400;
BA_ "InvalidValue" SG_ 560 WCBS_BrkFricTqTotAtWhls "3FFFh";
BA_ "GenSigTimeoutTime_ALL" SG_ 560 WCBS_HDCCtrlsts 400;
BA_ "InvalidValue" SG_ 560 WCBS_HDCCtrlsts "3h";
BA_ "GenSigTimeoutTime_ALL" SG_ 560 WCBS_HDC_displayWarnMsg 400;
BA_ "GenSigTimeoutTime_ALL" SG_ 560 WCBS_VehicleSteerSts 400;
BA_ "InvalidValue" SG_ 560 WCBS_VehicleSteerSts "3h";
BA_ "GenSigTimeoutTime_ALL" SG_ 560 WCBS_HDC_available 400;
BA_ "GenSigTimeoutTime_ALL" SG_ 560 WCBS_HDC_SwitchSts 400;
BA_ "GenSigTimeoutTime_ALL" SG_ 560 WCBS_DTCFailure 400;
BA_ "GenSigTimeoutTime_ALL" SG_ 560 WCBS_TowMode_Feedback 400;
BA_ "GenSigTimeoutTime_ALL" SG_ 560 WCBS_SCM_available 400;
BA_ "InvalidValue" SG_ 560 WCBS_SCM_available "0h";
BA_ "GenSigTimeoutTime_ALL" SG_ 560 WCBS_OnePedal_Active 400;
BA_ "GenSigTimeoutTime_ALL" SG_ 560 WCBS_OnePedal_hold_state 400;
BA_ "GenSigTimeoutTime_ALL" SG_ 560 WCBS_SCMActive 400;
BA_ "GenSigTimeoutTime_ALL" SG_ 560 WCBS_CDPFailSts 400;
BA_ "GenSigTimeoutTime_ALL" SG_ 560 WCBS_CBC_Active 400;
BA_ "InvalidValue" SG_ 560 WCBS_CBC_Active "0h";
BA_ "GenSigTimeoutTime_ALL" SG_ 560 WCBS_CBC_Available 400;
BA_ "InvalidValue" SG_ 560 WCBS_CBC_Available "0h";
BA_ "GenSigTimeoutTime_ALL" SG_ 560 WCBS_SLS_Active 400;
BA_ "InvalidValue" SG_ 560 WCBS_SLS_Active "0h";
BA_ "GenSigTimeoutTime_ALL" SG_ 560 WCBS_SLS_Available 400;
BA_ "InvalidValue" SG_ 560 WCBS_SLS_Available "0h";
BA_ "GenSigTimeoutTime_ALL" SG_ 560 WCBS_TVBB_Active 400;
BA_ "InvalidValue" SG_ 560 WCBS_TVBB_Active "0h";
BA_ "GenSigTimeoutTime_ALL" SG_ 560 WCBS_TVBB_Available 400;
BA_ "InvalidValue" SG_ 560 WCBS_TVBB_Available "0h";
BA_ "GenSigTimeoutTime_ALL" SG_ 560 WCBS_BDW_Active 400;
BA_ "InvalidValue" SG_ 560 WCBS_BDW_Active "0h";
BA_ "GenSigTimeoutTime_ALL" SG_ 560 WCBS_BDW_Available 400;
BA_ "InvalidValue" SG_ 560 WCBS_BDW_Available "0h";
BA_ "GenSigTimeoutTime_ALL" SG_ 596 CRC_WCBS_AVL_RPM_WHL_REAR 200;
BA_ "GenSigTimeoutTime_ALL" SG_ 596 ALIVE_WCBS_AVL_RPM_WHL_REAR 200;
BA_ "InvalidValue" SG_ 596 ALIVE_WCBS_AVL_RPM_WHL_REAR "Fh";
BA_ "GenSigTimeoutTime_ALL" SG_ 596 AVL_RPM_WHL_RLH 200;
BA_ "GenSigStartValue" SG_ 596 AVL_RPM_WHL_RLH 32819;
BA_ "GenSigTimeoutTime_ALL" SG_ 596 AVL_RPM_WHL_RRH 200;
BA_ "GenSigStartValue" SG_ 596 AVL_RPM_WHL_RRH 32819;
BA_ "GenSigTimeoutTime_ALL" SG_ 596 QU_AVL_RPM_WHL_RLH 200;
BA_ "InvalidValue" SG_ 596 QU_AVL_RPM_WHL_RLH "Fh";
BA_ "GenSigTimeoutTime_ALL" SG_ 596 QU_AVL_RPM_WHL_RRH 200;
BA_ "InvalidValue" SG_ 596 QU_AVL_RPM_WHL_RRH "Fh";
BA_ "GenSigTimeoutTime_ALL" SG_ 597 CRC_WCBS_AVL_RPM_WHL_FRONT 200;
BA_ "GenSigTimeoutTime_ALL" SG_ 597 ALIVE_WCBS_AVL_RPM_WHL_FRONT 200;
BA_ "InvalidValue" SG_ 597 ALIVE_WCBS_AVL_RPM_WHL_FRONT "Fh";
BA_ "GenSigTimeoutTime_ALL" SG_ 597 AVL_RPM_WHL_FLH 200;
BA_ "GenSigStartValue" SG_ 597 AVL_RPM_WHL_FLH 32819;
BA_ "GenSigTimeoutTime_ALL" SG_ 597 AVL_RPM_WHL_FRH 200;
BA_ "GenSigStartValue" SG_ 597 AVL_RPM_WHL_FRH 32819;
BA_ "GenSigTimeoutTime_ALL" SG_ 597 QU_AVL_RPM_WHL_FLH 200;
BA_ "InvalidValue" SG_ 597 QU_AVL_RPM_WHL_FLH "Fh";
BA_ "GenSigTimeoutTime_ALL" SG_ 597 QU_AVL_RPM_WHL_FRH 200;
BA_ "InvalidValue" SG_ 597 QU_AVL_RPM_WHL_FRH "Fh";
BA_ "InvalidValue" SG_ 624 ALIVE_WCBS_Info "Fh";
BA_ "InvalidValue" SG_ 624 WCBS_Fault_Status "7h";
BA_ "GenSigTimeoutTime_ALL" SG_ 624 FBW_WarningSts 200;
BA_ "InvalidValue" SG_ 624 FBW_WarningSts "3h";
BA_ "GenSigTimeoutTime_ALL" SG_ 624 Brake_Disc_Temp_FL 200;
BA_ "GenSigTimeoutTime_ALL" SG_ 624 Brake_Disc_Temp_FR 200;
BA_ "GenSigTimeoutTime_ALL" SG_ 624 Brake_Disc_Temp_RL 200;
BA_ "GenSigTimeoutTime_ALL" SG_ 624 Brake_Disc_Temp_RR 200;
BA_ "InvalidValue" SG_ 624 WCBS_BrakesystemFailSts "7h";
BA_ "GenSigTimeoutTime_ALL" SG_ 644 CRC_WCBS_ADCU_VAP_ControlResp 100;
BA_ "GenSigTimeoutTime_ALL" SG_ 644 ALIVE_WCBS_ADCU_VAP_ControlResp 100;
BA_ "InvalidValue" SG_ 644 ALIVE_WCBS_ADCU_VAP_ControlResp "Fh";
BA_ "GenSigTimeoutTime_ALL" SG_ 644 WCBS_ADCU_VAP_Mode 100;
BA_ "InvalidValue" SG_ 644 WCBS_ADCU_VAP_Mode "Fh";
BA_ "GenSigTimeoutTime_ALL" SG_ 644 WCBS_ADCU_VAP_State 100;
BA_ "InvalidValue" SG_ 644 WCBS_ADCU_VAP_State "3h";
BA_ "GenSigTimeoutTime_ALL" SG_ 644 WCBS_ADCU_VAP_ControlResp 100;
BA_ "InvalidValue" SG_ 644 WCBS_ADCU_VAP_ControlResp "Fh";
BA_ "GenSigTimeoutTime_ALL" SG_ 644 WCBS_ADCU_VAP_Available 100;
BA_ "InvalidValue" SG_ 644 WCBS_ADCU_VAP_Available "1h";
BA_ "GenSigTimeoutTime_ALL" SG_ 644 WCBS_ADCU_VAP_VehicleHoldState 100;
BA_ "InvalidValue" SG_ 644 WCBS_ADCU_VAP_VehicleHoldState "0h";
BA_ "GenSigTimeoutTime_ALL" SG_ 644 WCBS_ADCU_VAP_VehicleStandstill 100;
BA_ "InvalidValue" SG_ 644 WCBS_ADCU_VAP_VehicleStandstill "0h";
BA_ "GenSigTimeoutTime_ALL" SG_ 644 WCBS_ADCU_VAP_BrakeState 100;
BA_ "InvalidValue" SG_ 644 WCBS_ADCU_VAP_BrakeState "0h";
BA_ "GenSigTimeoutTime_ALL" SG_ 644 WCBS_ADCU_VAP_EPBState 100;
BA_ "InvalidValue" SG_ 644 WCBS_ADCU_VAP_EPBState "0h";
BA_ "GenSigTimeoutTime_ALL" SG_ 644 WCBS_ADCU_VAP_BrakePedalPressed 100;
BA_ "InvalidValue" SG_ 644 WCBS_ADCU_VAP_BrakePedalPressed "0h";
BA_ "GenSigTimeoutTime_ALL" SG_ 644 WCBS_ADCU_VAP_BrakePedalTravel 100;
BA_ "InvalidValue" SG_ 644 WCBS_ADCU_VAP_BrakePedalTravel "3FFh";
BA_ "GenSigTimeoutTime_ALL" SG_ 644 WCBS_ADCU_VAP_BrakePedalPct 100;
BA_ "InvalidValue" SG_ 644 WCBS_ADCU_VAP_BrakePedalPct "FFh";
BA_ "GenSigTimeoutTime_ALL" SG_ 644 WCBS_ADCU_VAP_BrakePedalRate 100;
BA_ "InvalidValue" SG_ 644 WCBS_ADCU_VAP_BrakePedalRate "3FFh";
BA_ "GenSigTimeoutTime_ALL" SG_ 815 CRC_WCBS_ADAS_Info 200;
BA_ "GenSigTimeoutTime_ALL" SG_ 815 ALIVE_WCBS_ADAS_Info 200;
BA_ "InvalidValue" SG_ 815 ALIVE_WCBS_ADAS_Info "Fh";
BA_ "GenSigTimeoutTime_ALL" SG_ 815 WCBS_ACC_Available_Flag 200;
BA_ "GenSigTimeoutTime_ALL" SG_ 815 WCBS_ACC_Deceleration_Flag 200;
BA_ "GenSigTimeoutTime_ALL" SG_ 815 WCBS_ACC_Acceleration_Flag 200;
BA_ "GenSigTimeoutTime_ALL" SG_ 815 WCBS_RAEB_Active_Flag 200;
BA_ "GenSigTimeoutTime_ALL" SG_ 815 WCBS_RAEB_Available_Flag 200;
BA_ "GenSigTimeoutTime_ALL" SG_ 815 WCBS_AEB_Active_Flag 200;
BA_ "GenSigTimeoutTime_ALL" SG_ 815 WCBS_AEB_Available_Flag 200;
BA_ "GenSigTimeoutTime_ALL" SG_ 815 WCBS_ACC_DriverOverride 200;
BA_ "GenSigStartValue" SG_ 815 WCBS_ACC_TargetWheel_Torque 8000;
BA_ "InvalidValue" SG_ 815 WCBS_ACC_TargetWheel_Torque "FFFFh";
BA_ "GenSigTimeoutTime_ALL" SG_ 815 WCBS_RAEB_BrakeActuator 200;
BA_ "InvalidValue" SG_ 866 ALIVE_WCBS_RecuBrkTrqReq "Fh";
BA_ "GenSigStartValue" SG_ 866 WCBS_F_RegenTarTrq 4000;
BA_ "InvalidValue" SG_ 866 WCBS_F_RegenTarTrq "FFFFh";
BA_ "GenSigStartValue" SG_ 866 WCBS_R_RegenTarTrq 4000;
BA_ "InvalidValue" SG_ 866 WCBS_R_RegenTarTrq "FFFFh";
BA_ "GenSigStartValue" SG_ 866 WCBS_F_FrictionTarTrq 4000;
BA_ "InvalidValue" SG_ 866 WCBS_F_FrictionTarTrq "FFFFh";
BA_ "GenSigStartValue" SG_ 866 WCBS_R_FrictionTarTrq 4000;
BA_ "InvalidValue" SG_ 866 WCBS_R_FrictionTarTrq "FFFFh";
BA_ "InvalidValue" SG_ 994 ALIVE_WCBS_IMU_Output "Fh";
BA_ "GenSigStartValue" SG_ 994 WCBS_LateralACC 12000;
BA_ "InvalidValue" SG_ 994 WCBS_LateralACC "FFFFh";
BA_ "GenSigStartValue" SG_ 994 WCBS_LongitudeACC 12000;
BA_ "InvalidValue" SG_ 994 WCBS_LongitudeACC "FFFFh";
BA_ "GenSigStartValue" SG_ 994 WCBS_VehDynYawRate 15000;
BA_ "InvalidValue" SG_ 994 WCBS_VehDynYawRate "FFFFh";
BA_ "GenSigStartValue" SG_ 994 WCBS_LateralACCRaw 30000;
BA_ "InvalidValue" SG_ 994 WCBS_LateralACCRaw "FFFFh";
BA_ "GenSigStartValue" SG_ 994 WCBS_LongitudeACCRaw 30000;
BA_ "InvalidValue" SG_ 994 WCBS_LongitudeACCRaw "FFFFh";
BA_ "GenSigStartValue" SG_ 994 WCBS_VehDynYawRateRaw 30000;
BA_ "InvalidValue" SG_ 994 WCBS_VehDynYawRateRaw "FFFFh";
BA_ "GenSigStartValue" SG_ 994 WCBS_ESCTarYawRate 30000;
BA_ "InvalidValue" SG_ 994 WCBS_ESCTarYawRate "FFFFh";
BA_ "GenSigSendType" SG_ 1831 WCBS_PBC_library_testm0 1;
BA_ "GenSigSendType" SG_ 1831 WCBS_PBC_library_testm1 1;
BA_ "GenSigSendType" SG_ 1831 WCBS_PBC_library_testm2 1;
BA_ "GenSigSendType" SG_ 1831 WCBS_PBC_library_testm3 1;
BA_ "GenSigSendType" SG_ 1831 WCBS_PBC_library_testm4 1;
BA_ "GenSigSendType" SG_ 1831 WCBS_PBC_library_testm5 1;
BA_ "GenSigSendType" SG_ 1831 WCBS_PBC_library_testm6 1;
BA_ "GenSigSendType" SG_ 1831 WCBS_PBC_library_testm7 1;
BA_ "GenSigSendType" SG_ 1831 WCBS_PBC_library_testm8 1;
BA_ "GenSigSendType" SG_ 1831 WCBS_PBC_library_testm9 1;
BA_ "GenSigSendType" SG_ 1831 WCBS_PBC_library_testm10 1;
BA_ "GenSigSendType" SG_ 1831 WCBS_PBC_library_testm11 1;
BA_ "GenSigSendType" SG_ 1831 WCBS_PBC_library_testm12 1;
BA_ "GenSigSendType" SG_ 1831 WCBS_PBC_library_testm13 1;
BA_ "GenSigSendType" SG_ 1831 WCBS_PBC_library_testm14 1;
BA_ "GenSigSendType" SG_ 1831 WCBS_PBC_library_testm15 1;
BA_ "GenSigSendType" SG_ 1831 WCBS_PBC_library_testm16 1;
BA_ "GenSigSendType" SG_ 1831 WCBS_PBC_library_testm17 1;
BA_ "GenSigSendType" SG_ 1831 WCBS_PBC_library_testm18 1;
BA_ "GenSigSendType" SG_ 1831 WCBS_PBC_library_testm19 1;
BA_ "GenSigSendType" SG_ 1831 WCBS_PBC_library_testm20 1;
BA_ "GenSigSendType" SG_ 1831 WCBS_PBC_library_testm21 1;
BA_ "GenSigSendType" SG_ 1831 WCBS_PBC_library_testm22 1;
BA_ "GenSigSendType" SG_ 1831 WCBS_PBC_library_testm23 1;
BA_ "GenSigSendType" SG_ 1832 WCBS_PBC_library_testa0 1;
BA_ "GenSigSendType" SG_ 1832 WCBS_PBC_library_testa1 1;
BA_ "GenSigSendType" SG_ 1832 WCBS_PBC_library_testa2 1;
BA_ "GenSigSendType" SG_ 1832 WCBS_PBC_library_testa3 1;
BA_ "GenSigSendType" SG_ 1832 WCBS_PBC_library_testa4 1;
BA_ "GenSigSendType" SG_ 1832 WCBS_PBC_library_testa5 1;
BA_ "GenSigSendType" SG_ 1832 WCBS_PBC_library_testa6 1;
BA_ "GenSigSendType" SG_ 1832 WCBS_PBC_library_testa7 1;
BA_ "GenSigSendType" SG_ 1832 WCBS_PBC_library_testa8 1;
BA_ "GenSigSendType" SG_ 1832 WCBS_PBC_library_testa9 1;
BA_ "GenSigSendType" SG_ 1832 WCBS_PBC_library_testa10 1;
BA_ "GenSigSendType" SG_ 1832 WCBS_PBC_library_testa11 1;
BA_ "GenSigSendType" SG_ 1832 WCBS_PBC_library_testa12 1;
BA_ "GenSigSendType" SG_ 1832 WCBS_PBC_library_testa13 1;
BA_ "GenSigSendType" SG_ 1832 WCBS_PBC_library_testa14 1;
BA_ "GenSigSendType" SG_ 1832 WCBS_PBC_library_testa15 1;
BA_ "GenSigSendType" SG_ 1832 WCBS_PBC_library_testa16 1;
BA_ "GenSigSendType" SG_ 1832 WCBS_PBC_library_testa17 1;
BA_ "GenSigSendType" SG_ 1832 WCBS_PBC_library_testa18 1;
BA_ "GenSigSendType" SG_ 1832 WCBS_PBC_library_testa19 1;
BA_ "GenSigSendType" SG_ 1832 WCBS_PBC_library_testa20 1;
BA_ "GenSigSendType" SG_ 1832 WCBS_PBC_library_testa21 1;
BA_ "GenSigSendType" SG_ 1832 WCBS_PBC_library_testa22 1;
BA_ "GenSigSendType" SG_ 1832 WCBS_PBC_library_testa23 1;
BA_ "GenSigSendType" SG_ 1971 WCBS_Req_RandomData 2;
BA_ "GenSigSendType" SG_ 1971 WCBS_Req_MAC 2;
BA_ "GenSigTimeoutTime_ALL" SG_ 305 CRC_FCAM_ACC_DriveOff 200;
BA_ "GenSigTimeoutTime_ALL" SG_ 305 ALIVE_FCAM_ACC_DriveOff 200;
BA_ "InvalidValue" SG_ 305 ALIVE_FCAM_ACC_DriveOff "Fh";
BA_ "GenSigTimeoutTime_ALL" SG_ 305 FCAM_ACC_DriveOff 200;
BA_ "GenSigTimeoutTime_ALL" SG_ 310 CRC_FCAM_LKA 200;
BA_ "GenSigTimeoutTime_ALL" SG_ 310 ALIVE_FCAM_LKA 200;
BA_ "InvalidValue" SG_ 310 ALIVE_FCAM_LKA "Fh";
BA_ "GenSigTimeoutTime_ALL" SG_ 310 FCAM_LSS_Activation 200;
BA_ "GenSigTimeoutTime_ALL" SG_ 310 FCAM_LSS_Activation_2 200;
BA_ "GenSigTimeoutTime_ALL" SG_ 310 FCAM_HapWarning 200;
VAL_ 133 ACU_Crash_Sts 0 "No_Event" 1 "Crash_Detected" ;
VAL_ 133 ACU_Airbag_Deployment_Status 0 "No_Airbag_Deployment" 1 "Airbag_Deployment" ;
VAL_ 133 ACU_Crash_Intensity 0 "No_Crash" 1 "Crash_Intensity_1" 2 "Crash_Intensity_2" 3 "Crash_Intensity_3" ;
VAL_ 133 ACU_Front_Crash 0 "No_Event" 1 "Front_Crash_Detected" ;
VAL_ 133 ACU_DriverSide_Crash 0 "No_Event" 1 "Driverside_Crash_Detected" ;
VAL_ 133 ACU_PassSide_Crash 0 "No_Event" 1 "PasSide_Crash_Detected" ;
VAL_ 133 ACU_Rear_Crash 0 "No_Event" 1 "Rear_Crash_Detected" ;
VAL_ 133 ACU_Rollover_Crash 0 "No_Event" 1 "Rollover_Crash_Detected" ;
VAL_ 169 BCMFL_AmbientTempSts 0 "Normal" 1 "Short circuit Battery" 2 "Short circuit GND" 3 "Invalid" ;
VAL_ 169 BCMFL_CoolantTemp_EDS_In_Sts 0 "Normal" 1 "Short circuit Battery" 2 "Short circuit GND" 3 "Invalid" ;
VAL_ 169 BCMFL_CoolantTemp_EDS_Out_Sts 0 "Normal" 1 "Short circuit Battery" 2 "Short circuit GND" 3 "Invalid" ;
VAL_ 169 BCMFL_CoolantTemp_LTR_Out_Sts 0 "Normal" 1 "Short circuit Battery" 2 "Short circuit GND" 3 "Invalid" ;
VAL_ 169 BCMFL_ACLowSideTemperatureSts 0 "Normal" 1 "Short circuit Battery" 2 "Short circuit GND" 3 "Invalid" ;
VAL_ 169 BCMFL_ACLowSidePressureSts 0 "Normal" 1 "Short circuit Battery" 2 "Short circuit GND" 3 "Invalid" ;
VAL_ 169 BCMFL_ACHighSideTemperatureSts 0 "Normal" 1 "Short circuit Battery" 2 "Short circuit GND" 3 "Invalid" ;
VAL_ 169 BCMFL_ACHighSidePressureSts 0 "Normal" 1 "Short circuit Battery" 2 "Short circuit GND" 3 "Invalid" ;
VAL_ 169 BCMFL_CoolantTemp_HtrCore_In_Sts 0 "Normal" 1 "Short circuit Battery" 2 "Short circuit GND" 3 "Invalid" ;
VAL_ 169 BCMFL_Refrigerant_Temp_Sensor_St 0 "Normal" 1 "Short circuit Battery" 2 "Short circuit GND" 3 "Invalid" ;
VAL_ 169 BCMFL_PT_Sensor1_Pressure_Sts 0 "Normal" 1 "Short circuit Battery" 2 "Short circuit GND" 3 "Invalid" ;
VAL_ 169 BCMFL_PT_Sensor2_Pressure_Sts 0 "Normal" 1 "Short circuit Battery" 2 "Short circuit GND" 3 "Invalid" ;
VAL_ 201 FMCU_StsMCUFault 0 "No Fault" 1 "Fault level 1" 2 "Fault level 2" 3 "Fault level 3" 4 "Fault level 4" 5 "Fault level 5" 6 "Fault level 6" ;
VAL_ 201 FMCU_MotorSpdSts 0 "Valid" 1 "Invalid" ;
VAL_ 201 FMCU_MotorTqSts 0 "Valid" 1 "Invalid" ;
VAL_ 201 FMCU_CVC_CtrlMode 0 "Inactive" 1 "Torque control mode" 2 "Speed Control mode" 3 "Limphome" 4 "crawling" ;
VAL_ 201 FMCU_CVC_StsMode 0 "Init" 1 "LvStandby 12V" 5 "Standby" 6 "Torq" 7 "Speed" 9 "ActiveDischarge" 10 "Fault" 11 "PowerOff" 12 "AfterRun" ;
VAL_ 202 FMCU_ActInputVoltV 0 "Valid" 1 "Invalid" ;
VAL_ 202 FMCU_ActInputCurrentV 0 "Valid" 1 "Invalid" ;
VAL_ 203 RMCU_StsMCUFault 0 "No Fault" 1 "Fault level 1" 2 "Fault level 2" 3 "Fault level 3" 4 "Fault level 4" 5 "Fault level 5" 6 "Fault level 6" ;
VAL_ 203 RMCU_MotorSpdValid 0 "Valid" 1 "Invalid" ;
VAL_ 203 RMCU_MotorTqValid 0 "Valid" 1 "Invalid" ;
VAL_ 203 RMCU_CVC_CtrlMode 0 "Inactive" 1 "Torque control mode" 2 "Speed Control mode" 3 "Limphome" 4 "crawling" ;
VAL_ 203 RMCU_CVC_StsMode 0 "Init" 1 "LvStandby 12V" 5 "Standby" 6 "Torq" 7 "Speed" 9 "ActiveDischarge" 10 "Fault" 11 "PowerOff" 12 "AfterRun" ;
VAL_ 204 RMCU_ActInputVoltV 0 "Valid" 1 "Invalid" ;
VAL_ 204 RMCU_ActInputCurrentV 0 "Valid" 1 "Invalid" ;
VAL_ 217 CVC_HVsystem_status 0 "Not ready" 1 "HV On" 2 "ReadyToDrive" 3 "Charging" 4 "Error" 5 "Reserved" 6 "Reserved" 7 "Reserved" ;
VAL_ 217 CVC_ACPD_Percent_Valid 0 "Valid" 1 "Invalid" ;
VAL_ 217 CVC_ACTGear 0 "P" 1 "R" 2 "N" 3 "D" 4 "Reserved" 5 "Reserved" 6 "Reserved" 7 "Fault" ;
VAL_ 217 CVC_ACTGearValid 0 "Valid" 1 "Invalid" ;
VAL_ 217 CVC_ACT_DriveMode 0 "Normal mode" 1 "ECO mode" 2 "Sport mode" 3 "Reserved" 4 "Reserved" 5 "Reserved" 6 "Reserved" 7 "Invalid" ;
VAL_ 217 CVC_ACT_DriveMode_Valid 0 "Valid" 1 "Invalid" ;
VAL_ 217 CVC_HV_DRVsystem_status 0 "Not available" 1 "Normal" 2 "Degration" 3 "Limphome" 4 "Error" 5 "Reserved" 6 "Reserved" 7 "Reserved" ;
VAL_ 217 CVC_Recu_BrakeLight_ON_Req 0 "Brake light OFF" 1 "Brake light ON" 2 "Reserved" 3 "Signal not available" ;
VAL_ 217 CVC_EPB_SwitchSta 0 "Not Pressed" 1 "Pressed" 2 "Reserved" 3 "Invalid" ;
VAL_ 217 CVC_StsAccPedalFault 0 "Valid" 1 "Invalid" ;
VAL_ 217 CVC_StsSysFault 0 "Init" 1 "Normal" 3 "Warning" 5 "Derating" 7 "Limphome" 9 "ZeroTorque" 11 "Powerdown" 13 "EmPowerdown" 14 "Invalid" ;
VAL_ 217 CVC_AccPedal_Valid 0 "Valid" 1 "Invalid" ;
VAL_ 252 BCMFL_WasherPumpSts 0 "OFF" 1 "Front spraying" 2 "Rear spraying" 3 "Fault" ;
VAL_ 252 BCMFL_Wiper_Front_Status 0 "OFF" 1 "Mist" 2 "Intermittent Auto" 3 "Low speed" 4 "High speed" ;
VAL_ 252 BCMFL_STAT_FrontWiperServiceMode 0 "OFF" 1 "ON" 2 "Fault" 3 "Signal Invalid" ;
VAL_ 252 BCMFL_WiperServiceModeSts 0 "OFF" 1 "ON" 2 "Fault" ;
VAL_ 252 BCM_Fr_Rr_WashAndMist_Status 0 "No request" 1 "Front MIST" 2 "Front Wash and Wipe" 3 "Rear MIST" 4 "Rear Wash and Wipe" 5 "Reserved" 6 "Reserved" 7 "Invalid" ;
VAL_ 252 WakeupForTopup_Req 0 "Disable" 1 "Enable" 3 "Invalid" ;
VAL_ 252 BCMFL_InteriorTemperatureSts 0 "Normal" 1 "Short circuit Battery" 2 "Short circuit GND" 3 "Invalid" ;
VAL_ 252 BCM_Front_Wiper_Park_Pos_Status 0 "Front wiper not in Parking position" 1 "Front wiper in Parking position" ;
VAL_ 252 BCM_FL_STAT_RearHeatedWindowMirr 0 "OFF" 1 "ON" 2 "Reserved" 3 "Signal invalid" ;
VAL_ 252 BCMFL_STAT_Horn 0 "OFF" 1 "ON" 2 "Fault (Reserved)" 3 "Signal Invalid" ;
VAL_ 252 BCMFL_PowerOutlet_Sts 0 "OFF" 1 "ON" 2 "ERROR" 3 "Signal Invalid" ;
VAL_ 264 SS_P_Button 0 "Not Pressed" 1 "Pressed" 2 "Reserved" 3 "Invalid" ;
VAL_ 264 SS_TargetGearReq 0 "No Request" 1 "N1" 2 "N2" 3 "R" 4 "D" 5 "Reserved" 6 "Reserved" 7 "Invalid" ;
VAL_ 264 SS_ADAS_Req 0 "No Request" 1 "Action 1 request" 2 "Action 2 request" 3 "Action 3 request" 4 "Action 4 request" 5 "Reserved" 6 "Reserved" 7 "Invalid" ;
VAL_ 264 SS_DrvMd_RgnLvl_Req 0 "No Request" 1 "Revole UP" 2 "Revole DOWN" 3 "Revole Invalid" ;
VAL_ 264 SS_Fault 0 "normal" 1 "Shifter failure" 2 "CAN communication fail" 3 "Position sensor failure" 4 "Supply voltage failure" 5 "P button fault" 6 "Received Date from BCM is invalid" 7 "MCU FAULT" 8 "Reserved" 9 "Reserved" 10 "Reserved" 11 "Reserved" 12 "Reserved" 13 "Reserved" 14 "Reserved" 15 "Reserved" ;
VAL_ 264 SS_HighBeam_Req 0 "No Request" 1 "Manual High beam Request" 2 "Flashing high beam" 3 "Invalid" ;
VAL_ 264 SS_Lane_Change_Indicator_Req 0 "OFF" 1 "Left lane change" 2 "Right lane change" 3 "Left On" 4 "Right On" 5 "Reserved" 6 "Reserved" 7 "Invalid" ;
VAL_ 264 SS_FR_RR_WashAndMist_Req 0 "No request" 1 "Rotate Upward Short Hold" 2 "Rotate Upward Long Hold" 3 "Rotate Downward Short Hold" 4 "Rotate Downward Long Hold" 5 "Reserved" 6 "Reserved" 7 "Invalid" ;
VAL_ 264 SS_RR_WiperControl_Req 0 " No action" 1 "Button push" 2 "Reserved" 3 "Invalid" ;
VAL_ 264 SS_FR_Wipercontrol_Req 0 "OFF" 1 "Mode 1" 2 "Mode 2" 3 "Mode 3" 4 "Invalid" ;
VAL_ 266 LV_BatteryType 0 "Lead Acid Battery" 1 "Lithium Battery" 2 "Reversed" 3 "Invalid" ;
VAL_ 258 STAT_CrankRelayHW_BCM 0 "OFF" 1 "ON" 2 "Reserved" 3 "Signal invalid" ;
VAL_ 258 CVC_Transport_Mode 0 "OFF" 1 "ON" 2 "Reserved" 3 "Invalid" ;
VAL_ 258 CVC_Vehicle_Special_Mode 0 "None" 1 "Camp mode" 2 "Pet mode" 3 "Showroom mode" 4 "Tow mode" 5 "Reserved" 6 "Reserved" 7 "Signal invalid" ;
VAL_ 258 CVC_Acc_Mode_Req 0 "No request" 1 "ACC state request" 2 "Reserved" 3 "Signal invalid" ;
VAL_ 258 CVC_CL30s_Req 0 "OFF" 1 "ON" 2 "Reserved" 3 "Invalid" ;
VAL_ 258 CVC_CL30c_Req 0 "OFF" 1 "ON" 2 "Reserved" 3 "Invalid" ;
VAL_ 258 CVC_CLR_Req 0 "OFF" 1 "ON" 2 "Reserved" 3 "Invalid" ;
VAL_ 258 CVC_CL15_Req 0 "OFF" 1 "ON" 2 "Reserved" 3 "Invalid" ;
VAL_ 258 Warning_Clamp_Incompatible 0 "None" 1 "Alert" 2 "Reserved" 3 "Reserved" ;
VAL_ 258 CVC_CL58_Req 0 "OFF" 1 "ON" 2 "Reserved" 3 "Invalid" ;
VAL_ 273 CVC_F_RegenTrqMaxValid 0 "Invalid" 1 "valid" ;
VAL_ 273 CVC_R_RegenTrqMaxValid 0 "Invalid" 1 "valid" ;
VAL_ 273 CVC_F_BrkRegenTrqActualValid 0 "Invalid" 1 "valid" ;
VAL_ 273 CVC_R_BrkRegenTrqActualValid 0 "Invalid" 1 "valid" ;
VAL_ 273 CVC_OnePedalModeSts 0 "Inactive" 1 "Standby" 2 "Active" 3 "Invalid" ;
VAL_ 273 CVC_OnePedalModeEnable 0 "Disable" 1 "Enable" 2 "Reserved" 3 "Invalid" ;
VAL_ 273 CVC_OnePedal_Standstill_Req 0 "One pedal Standstill Request off" 1 "One pedal Standstill Request on" ;
VAL_ 274 RemoteFunctionState 0 "Normal function" 1 "Remote function" 2 "Reserved" 3 "Signal Invalid" ;
VAL_ 274 CVC_STAT_BLS 0 "BLS not pressed" 1 "BLS pressed" 2 "Reserved" 3 "Signal invalid" ;
VAL_ 274 Vehicle_Operation_State 0 "OFF(Comfort Enable)" 1 "ACC (Park)" 2 "ON (Driver Present)" 3 "Engine start (eMotor running)" 4 "SW Update OTA" 5 "Reserved" 6 "Reserved" 7 "Signal Invalid" ;
VAL_ 288 CVC_F_TrqCurrWhlValid 0 "Invalid" 1 "valid" ;
VAL_ 288 CVC_R_TrqCurrWhlValid 0 "Invalid" 1 "valid" ;
VAL_ 288 Driver_Accel_Pedal_Override 0 "No Override" 1 "Driver Gas Pedal Override" 3 "Signal Invalid" ;
VAL_ 288 CVC_F_AxleCoastRegenTorqueValid 0 "Invalid" 1 "valid" ;
VAL_ 288 CVC_R_AxleCoastRegenTorqueValid 0 "Invalid" 1 "valid" ;
VAL_ 358 CVC_DriveModeSts 0 "Invalid" 1 "Comfort Mode" 2 "Eco Mode" 3 "Sport Mode" ;
VAL_ 358 CVC_DriveReady 0 "Not Ready" 1 "Ready" ;
VAL_ 358 CVC_Fault 0 "No fault" 1 "FaultLevel 1" 2 "FaultLevel 2" 3 "Faultlevel3(Error)" ;
VAL_ 358 CVC_VecFltInd 0 "No fault()" 1 "Fault()" ;
VAL_ 358 CVC_Creep_Sts 0 "Invalid" 1 "Creep disable" 2 "Creep enable" 3 "Creep function fault" ;
VAL_ 358 CVC_CruiseCtrlSts 0 "OFF" 1 "Standby" 2 "Active" 3 "Override" 4 "Fault" 5 "Reserved" 6 "Reserved" ;
VAL_ 358 CVC_StsBrakePedalSwitch 0 "Reserved()" 1 "Not pressed()" 2 "Pressed()" 3 "Invalid()" ;
VAL_ 358 CVC_VehicleMode 0 "EV" 1 "REV" 2 "Fuel" ;
VAL_ 358 CVC_CruiseFaultIndication 0 "No Fault" 1 "Pre-Condition not met" 2 "Function fault" ;
VAL_ 358 TRMFitted 0 "Unsupported" 1 "Fitted" 2 "Not Fitted" 3 "SNA" ;
VAL_ 358 CVC_FuelDetectionSwitchState 0 "No COM" 1 "Enable" 2 "Close" 3 "Invalid" ;
VAL_ 358 CVC_FuelDetectionState 0 "No COM" 1 "High Idle" 2 "Low Idle" 3 "Invalid" ;
VAL_ 358 CVC_ParkingChargeRequest 0 "No COM" 1 "Enable" 2 "Close" 3 "Invalid" ;
VAL_ 358 CVC_ParkingChargeModeSet 0 "NORequest" 1 "LOW" 2 "MIDDLE" 3 "HIGH" ;
VAL_ 358 LV_EM_Rampup_Req 0 "No Load Management" 1 "DCDC OFF_No_Rampup" 2 "DCDCRampupTimer_Active" ;
VAL_ 358 LV_PowerSupply_Status 0 "No Fault" 1 "Fault" ;
VAL_ 358 LV_EM_OTA_Req 0 "No OTA LM" 1 "OTA LV Rampup" 2 "OTA_LV_LM_TimerExpired" 3 "OTA_LV_LM_DCDCOFF" ;
VAL_ 358 CVC_STAT_AirDistributionModeLH 0 "OFF" 1 "Vent" 2 "Vent LH + Foot LH" 3 "Foot LH" 4 "Foot LH + Defrost" 5 "Defrost" 6 "Defrost + Face" 7 "Tri Level" ;
VAL_ 358 CVC_STAT_AirDistributionModeRH 0 "OFF" 1 "Vent" 2 "Vent RH + Foot RH" 3 "Foot RH" ;
VAL_ 358 CVC_STAT_DriverOnly 0 "OFF" 1 "ON" 2 "Reserved" 3 "Signal Invalid" ;
VAL_ 524 CVC_OdometerV 0 "valid" 1 "invalid" ;
VAL_ 533 BMS_BatBalance_ERR 0 "Error" 1 "normal" ;
VAL_ 533 BMS_Balance_STS 0 "Inactive" 1 "active" ;
VAL_ 533 BMS_IGN_Sts 0 "OFF" 1 "ON" ;
VAL_ 533 BMS_HWCrash_Sts 0 "No Crash" 1 "Crash" ;
VAL_ 533 BMS_HVIL_STS 0 "Closed" 1 "Open & short to battery" 2 "short to ground" 3 "Signal invalid" ;
VAL_ 533 BMS_HVOnOff_STS 0 "HV Off" 1 "Precharge" 2 "HV On" 3 "Fail to HV on" ;
VAL_ 533 BMS_ERR_LEV 0 "No error" 1 "Warning" 2 "Limp Home" 3 "Power down without FTTI" 4 "Delay power down with FTTI" 5 "Emergency off condition" 6 "Fault, needs to shutdown and wakeup" 7 "Battery locked - reserved" ;
VAL_ 533 BMS_Sys_STS 0 "Initialization of power on, self-checking" 1 "Self-check passes, can be high-voltage" 2 "Successful High Voltage Power Up" 3 "Successful Power Down of HV" 4 "Power Down process" 5 "Successful Power Down" 6 "BCU Sleep mode" 7 "Failure, unable to operate" 8 "Invalid" ;
VAL_ 533 BMS_ISU_Status 0 "Normal (> 250 kOhms)" 1 "Level1 (<250 kOhms ~ >100 kOhms)" 3 "Level3 (<100 kOhms)" ;
VAL_ 533 BMS_HV_Sts 0 "HV Off" 1 "Pre Charge" 2 "HV On" 3 "Super_Fast_Charge" 4 "AC Charge" 5 "Undefined" 6 "Undefined" 7 "Undefined" 8 "Undefined" 9 "Undefined" ;
VAL_ 618 CVC_VehicleHVStatus 0 "Not ready" 1 "HV On" 2 "ReadyToDrive" 3 "Reserved" ;
VAL_ 645 CVC_ADCU_VAP_State 0 "Idle'" 1 "Active" 2 "Abort" 3 "Error" ;
VAL_ 645 CVC_ADCU_VAP_ControlResp 0 "normal" 1 "vehicle block" 2 "Improper handshake" 3 "over speed" 4 "unexcepted action" 5 "other sub function active" 6 "Slope Over" 7 "Failure" ;
VAL_ 645 CVC_ADCU_VAP_Available 0 "Available" 1 "Busy" ;
VAL_ 645 CVC_ADCU_VAP_BCMAvailable 0 "Available" 1 "Busy" ;
VAL_ 645 CVC_ADCU_VAP_TboxAvailable 0 "Available" 1 "Busy" ;
VAL_ 645 CVC_ADCU_VAP_DKCUAvailable 0 "Available" 1 "Busy" ;
VAL_ 645 CVC_ADCU_VAP_ACTGear 0 "P" 1 "R" 2 "N" 3 "D" 4 "Reserved" 5 "Reserved" 6 "Reserved" 7 "Fault" ;
VAL_ 645 CVC_ADCU_VAP_ACTGearValid 0 "Valid" 1 "Invalid" ;
VAL_ 645 CVC_ADCU_VAP_AcclPedalPressed 0 "Released" 1 "Presssed" ;
VAL_ 760 DISP_DATE_WDAY 1 "Monday" 2 "Tuesday" 3 "Wednesday" 4 "Thursday" 5 "Friday" 6 "Saturday" 7 "Sunday" 15 "Signal invalid" ;
VAL_ 760 ST_DISP_CTI_DATE 0 "data not valid" 1 "data valid" 3 "UTC" 5 "winter time" 6 "Manually set time" 7 "summer time" 15 "signal invalid" ;
VAL_ 788 MHU_RAEB_check 0 "Available" 1 "Degraded" 2 "Temporarily not available" 3 "Permanently not available" 4 "RAEB Inhibited" 5 "Reserved" 6 "Initializing" 7 "Invalid" ;
VAL_ 788 MHU_RAEB_Warning 0 "No warning" 1 "Braking" 2 "Postfeedback" 3 "Display Prompt to turn OFF RAEB" 4 "Reserved" 5 "Reserved" 6 "Reserved" 7 "Invalid" ;
VAL_ 788 MHU_RAEB_State 0 "Off" 1 "Inactive" 2 "Ready" 3 "PreFill" 4 "AEB Active" 5 "Post-RAEB Brake" 6 "Error" 7 "Invalid" ;
VAL_ 788 MHU_RAEB_BrakeCommand 0 "No Request" 1 "Prefill Brake Request" 2 "Emergency brake Request" 3 "Signal invalid" ;
VAL_ 788 MHU_RAEB_Available 0 "Not Support" 1 "Not Available" 2 "Available" 3 "Invalid" ;
VAL_ 788 MHU_RAEB_FuncActive 0 "Not Active" 1 "Active" ;
VAL_ 788 MHU_RAEB_Mode_Feed 0 "OFF" 1 "ON" 2 "Reserved" 3 "Invalid" ;
VAL_ 788 MHU_RAEB_BrakeType 0 "No Request" 1 "Comfort Brake" 2 "Normal Emergency Brake" 3 "Emergency Brake" ;
VAL_ 788 MHU_RAEB_PullEPBOpt 0 "No Request" 1 "Request" ;
VAL_ 788 MHU_RAEB_BrakeReq_Source 0 "None" 1 "RAEB request" 2 "Rear ACPE Request" 3 "RCTB - by Radar Rear crossing obj" 4 "Reserved" 5 "Reserved" 6 "Reserved" 7 "Invalid" ;
VAL_ 897 ACU_Seat_Occupancy_Passenger 0 "Seat_Not_Occupied" 1 "Seat Occupied" 2 "Not_Available" 3 "Failure" ;
VAL_ 897 ACU_Seat_Occupancy_2nd_Row_Dri 0 "Seat_Not_Occupied" 1 "Seat Occupied" 2 "Not_Available" 3 "Failure" ;
VAL_ 897 ACU_Seat_Occupancy_2nd_Row_Pas 0 "Seat_Not_Occupied" 1 "Seat Occupied" 2 "Not_Available" 3 "Failure" ;
VAL_ 897 ACU_Seat_Occupancy_2nd_Row_Mid 0 "Seat_Not_Occupied" 1 "Seat Occupied" 2 "Not_Available" 3 "Failure" ;
VAL_ 897 ACU_Seat_Belt_Status_Passenger 0 "Not_buckled" 1 "Buckled" 2 "Not_Available" 3 "Failure" ;
VAL_ 897 ACU_Seat_Belt_Status_Driver 0 "Not_buckled" 1 "Buckled" 2 "Not_Available" 3 "Failure" ;
VAL_ 897 ACU_Seat_Belt_Status_2nd_Row_Dri 0 "Not_buckled" 1 "Buckled" 2 "Not_Available" 3 "Failure" ;
VAL_ 897 ACU_Seat_Belt_Status_2nd_Row_Mid 0 "Not_buckled" 1 "Buckled" 2 "Not_Available" 3 "Failure" ;
VAL_ 897 ACU_Seat_Belt_Status_2nd_Row_Pas 0 "Not_buckled" 1 "Buckled" 2 "Not_Available" 3 "Failure" ;
VAL_ 897 ACU_Seat_Occupancy_Driver 0 "Seat_Not_Occupied" 1 "Seat Occupied" 2 "Not_Available" 3 "Failure" ;
VAL_ 996 IMU_VerticalACC_Valid 0 "Invalid" 1 "Valid" ;
VAL_ 996 IMU_VehDynPitchRate_Valid 0 "Invalid" 1 "Valid" ;
VAL_ 996 IMU_VehDynRollRate_Valid 0 "Invalid" 1 "Valid" ;
VAL_ 997 IMU_VerticalACCRaw_Valid 0 "Invalid" 1 "Valid" ;
VAL_ 997 IMU_VehDynPitchRateRaw_Valid 0 "Invalid" 1 "Valid" ;
VAL_ 997 IMU_VehDynRollRateRaw_Valid 0 "Invalid" 1 "Valid" ;
VAL_ 998 IMU_LateralACC_Valid 0 "Invalid" 1 "Valid" ;
VAL_ 998 IMU_LongitudeACC_Valid 0 "Invalid" 1 "Valid" ;
VAL_ 998 IMU_VehDynYawRate_Valid 0 "Invalid" 1 "Valid" ;
VAL_ 995 IMU_LateralACCRaw_Valid 0 "Invalid" 1 "Valid" ;
VAL_ 995 IMU_LongitudeACCRaw_Valid 0 "Invalid" 1 "Valid" ;
VAL_ 995 IMU_VehDynYawRateRaw_Valid 0 "Invalid" 1 "Valid" ;
VAL_ 1058 MHU_STAT_Cluster 0 "OFF" 1 "ON" 2 "Reserved" 3 "Signal invalid" ;
VAL_ 1058 MHU_STAT_Infotainment 0 "OFF" 1 "ON" 2 "Reserved" 3 "Signal invalid" ;
VAL_ 1058 MHU_STAT_MileageUnit 0 "Mile" 1 "KM" 2 "Reserved" 3 "Signal invalid" ;
VAL_ 1058 MHU_STAT_PressureUnit 0 "Bar" 1 "Psi" 2 "Kpa" 3 "Signal invalid" ;
VAL_ 1058 MHU_STAT_TemperatureUnit 0 "Celcius" 1 "Fahrenheit" 2 "Reserved" 3 "Signal invalid" ;
VAL_ 1058 MHU_STAT_DateTimeFormat 0 "24H" 1 "12H" 2 "Reserved" 3 "Signal invalid" ;
VAL_ 1058 MHU_Operation_State 0 "Sleep - Low power mode" 1 "Standby/Screen OFF" 2 "Booting/Rebooting" 3 "Running" 4 "Standby/Fullscreen" 5 "OTA progess" 6 "Fault" 7 "Signal Invalid" ;
VAL_ 1058 MHU_STAT_Language 0 "Vietnamese" 1 "English" 2 "Spanish" 3 "French" 4 "German" 5 "Dutch" 6 "English (CANADA)" 7 "French (CANADA)" 8 "Russian" 9 "Spanish (Latin America)" 10 "Portuguese" 11 "Portuguese (Brasil)" 12 "Chinese, simplipied" 13 "Chinese, traditional" 14 "Mexican-Spanish" 15 "Bahasa Indonesian" 16 "Hindi" 17 "Arabic" 18 "Italian" 19 "Finnish" 20 "Lithuanian" 21 "Latvian" 22 "Estonian" 23 "Hungarian" 24 "Czech" 25 "Slovakian" 26 "Slovenian" 27 "Croatian" 28 "Bulgarian" 29 "Reserved" 30 "Reserved" 31 "Signal invalid" ;
VAL_ 1058 MHU_STAT_EnergyConsumptionUnit 0 "KWH/100KM" 1 "KM/KWH" 2 "Mile per KWH" 3 "KWH/100mil" 4 "Reserved" 5 "Reserved" 6 "Reserved" 7 "Signal invalid" ;
VAL_ 1058 MHU_STAT_BatLvlPopsetting 0 "20%" 1 "30%" 2 "40%" 3 "50%" 4 "60%" 5 "70%" 6 "Signal Invalid" ;
VAL_ 1058 MHU_STAT_DistToEmptyUnit 0 "%percentage" 1 "KM/Mi" 2 "Reserved" 3 "Signal Invalid" ;
VAL_ 1058 MHU_DCM_Status 0 "Normal" 1 "Fault" 2 "Reserved" ;
VAL_ 1082 CVC_BrakeRegenMode 0 "OFF" 1 "LOW" 2 "MID" 3 "HIGH" ;
VAL_ 1082 CVC_CreepEnable_stt 0 "Enable" 1 "Disable" ;
VAL_ 1082 CVC_Regen_available 0 "Not available" 1 "Available" 2 "Regen limit" 3 "Regen faut" ;
VAL_ 1082 CVC_StoppingMode_stt 0 "Off" 1 "CreepMode" 2 "RollMode" 3 "HoldMode" 4 "Reserved" 5 "Reserved" 6 "Reserved" 7 "Reserved" ;
VAL_ 1082 CVC_AutoP_Feedback 0 "ON" 1 "OFF" 2 "Reserved" 3 "Signal Invalid" ;
VAL_ 1082 CVC_Hvbatt_charging_stt 0 "Not charging" 1 "Charging" ;
VAL_ 1082 CVC_PreheatBatt_Sts 0 "Off" 1 "On" ;
VAL_ 1082 CVC_HDC_Status 0 "Off" 1 "Standby" 2 "Active" 3 "Warning" 4 "Error" ;
VAL_ 1082 CVC_STAT_RearAircondition 0 "OFF" 1 "ON" 2 "Reserved" 3 "Signal Invalid" ;
VAL_ 1082 CVC_STAT_AirDistributionRear 0 "OFF" 1 "Vent" 2 "Vent + Foot" 3 "Foot" ;
VAL_ 1082 CVC_STAT_RearFanSpeed 0 "OFF" 1 "Level 1" 2 "Level 2" 3 "Level 3" 4 "Level 4" 5 "Level 5" 6 "Level 6" 15 "Level " ;
VAL_ 1082 CVC_STAT_RearAuto 0 "OFF" 1 "ON" 2 "Reserved" 3 "Signal Invalid" ;
VAL_ 1095 MHU_AVH_Sw 0 "No Action" 1 "ON" 2 "OFF" 3 "Reserved" ;
VAL_ 1095 MHU_TowingMode_Sw 0 "No Action" 1 "ON" 2 "OFF" 3 "Reserved" ;
VAL_ 1095 MHU_HDC_Switch 0 "OFF" 1 "ON" 3 "Signal Invalid" ;
VAL_ 1095 MHU_SET_WashMode 0 "Wash mode OFF" 1 "Wash mode ON" 2 "Reserved" 3 "Signal Invalid" ;
VAL_ 1095 MHU_TowMode_Req 0 "Inactive" 1 "Active" 3 "Reserve" ;
VAL_ 1095 MHU_ESC_TCS_Switch 0 "Normal" 1 "Traction Mode OFF" 2 "ESC-OFF" 3 "Signal Invalid" ;
VAL_ 1095 MHU_V2LPowertrans_sts 0 "Enable" 1 "Disable" 2 "Signal invalid" ;
VAL_ 1098 CVC_MaxTorq_Sts_FR 0 "Not Initialised" 1 "Normal" 2 "Faulty" ;
VAL_ 1098 CVC_MinTorq_Sts_FR 0 "Not Initialised" 1 "Normal" 2 "Faulty" ;
VAL_ 1098 CVC_MaxTorq_Sts_RR 0 "Not Initialised" 1 "Normal" 2 "Faulty" ;
VAL_ 1098 CVC_MinTorq_Sts_RR 0 "Not Initialised" 1 "Normal" 2 "Faulty" ;
VAL_ 1098 CVC_WCBS_VAP_ControlResp 0 "Not Active" 1 "Active" ;
VAL_ 1098 CVC_WCBS_VAP_Available 0 "Not available" 1 "Available" ;
VAL_ 1098 CVC_WCBS_APA_WheelTrq_Res 0 "Not Active" 1 "Active" ;
VAL_ 1098 CVC_WCBS_VAP_FuncMode 0 "INIT" 1 "STANDBY" 2 "STARTUP" 3 "FAPA" 4 "RP" 5 "SELECT-SEATED" 6 "SELECT-REMOTE" 7 "COMFORT-IN" 8 "COMFORT-OUT" 9 "AUTOREVERSE" 10 "SUMMON" 11 "reserved" 12 "STOP" 13 "reserved" 14 "reserved" 15 "reserved" ;
VAL_ 1100 CVC_FMCU_demtrqValid 0 "Invalid" 1 "Valid" ;
VAL_ 1100 CVC_RMCU_demtrqValid 0 "Invalid" 1 "Valid" ;
VAL_ 1118 BCM_HeaterActivation_Feedback 0 "OFF" 1 "ON" ;
VAL_ 1236 Body_CoverAjarStatus 0 "CoverClosed" 1 "CoverAjar" ;
VAL_ 1236 Body_TrunckAjarStatus 0 "TrunkClosed" 1 "TrunkAjar" ;
VAL_ 1236 Body_DriverSideDoorAjarSts 0 "DoorClosed" 1 "DoorAjar" 2 "Reserved" 3 "Signal Invalid" ;
VAL_ 1236 Body_CodriversSideDoorAjarSts 0 "DoorClosed" 1 "DoorAjar" 2 "Reserved" 3 "Signal Invalid" ;
VAL_ 1236 Body_RearLeftDoorAjarStatus 0 "DoorClosed" 1 "DoorAjar" 2 "Reserved" 3 "Signal Invalid" ;
VAL_ 1236 Body_DoorLockStatusRL 0 "Unlocked" 1 "Locked" 2 "Reserved" 3 "Error(Reserved)" ;
VAL_ 1236 Body_DoorLockStatusRR 0 "Unlocked" 1 "Locked" 2 "Reserved" 3 "Error(Reserved)" ;
VAL_ 1236 Body_DoorLockStatusCodrivres 0 "Unlocked" 1 "Locked" 2 "Reserved" 3 "Error(Reserved)" ;
VAL_ 1236 Body_DoorLockStatusDrv 0 "Unlocked" 1 "Locked" 2 "Reserved" 3 "Error(Reserved)" ;
VAL_ 1236 Body_RearRightDoorAjarStatus 0 "DoorClosed" 1 "DoorAjar" 2 "Reserved" 3 "Signal Invalid" ;
VAL_ 1236 Body_ATWS_St 0 "Armed" 1 "Prearmed" 2 "Disarmed" 3 "Remind" 4 "Alarm" 5 "Partially Armed" ;
VAL_ 1236 Body_TailGateSts 0 "Close" 1 "Open" ;
VAL_ 1236 Body_ETGLockStatus 0 "Lock" 1 "Unlocked" 2 "Faults" 3 "Invalid" ;
VAL_ 382 SAS_SASStsSnsr 0 "sensor value Invalid" 1 "sensor value valid" ;
VAL_ 382 SAS_SteerWhlRotSpdStatus 0 "Invalid" 1 "Valid" ;
VAL_ 382 SAS_SASFailure 0 "Failure" 1 "No Failure" ;
VAL_ 382 SAS_Calibrated 0 "Not Calibrated" 1 "Calibrated" ;
VAL_ 382 SAS_SteerWheelAngleValid 0 "Valid" 1 "Invalid" ;
VAL_ 383 EPS_FCAM_function_feed_2 0 "No activation" 1 "ESA activation" 2 "HWA activation" 3 "NOP activation" 4 "Reserved" 5 "Reserved" 6 "Reserved" ;
VAL_ 383 EPS_FCAM_function_feed 0 "No activation" 1 "LKA activation" 2 "ELK activation" 3 "TJA activation" 4 "Reserved" 5 "Reserved" 6 "Reserved" ;
VAL_ 646 EPS_ADCU_VAP_State 0 "Idle'" 1 "Active" 2 "Abort" 3 "Error" ;
VAL_ 646 EPS_ADCU_VAP_ControlResp 0 "Normal" 1 "Vehicle block" 2 "Improper handshake" 3 "Over speed" 4 "Unexpected action" 5 "Other sub function active" 6 "Slope Over" 7 "Failure" ;
VAL_ 646 EPS_ADCU_VAP_Available 0 "Available" 1 "Busy" ;
VAL_ 646 EPS_ADCU_VAP_SteerAngleValid 0 "Valid" 1 "Invalid" ;
VAL_ 646 EPS_ADCU_VAP_SteerIntervention 0 "Normal" 1 "Intervention" ;
VAL_ 796 EPS_Drive_Intervention 0 "No Intervention" 1 "Intervention" ;
VAL_ 796 EPS_TorqueLimitationState 0 "no saturation" 1 "Saturation effective" ;
VAL_ 796 EPS_SteerPrsnlMod 0 "Normal Mode" 1 "Eco Mode" 2 "Sport Mode" 3 "Reserved" 4 "Reserved" 5 "Reserved" 6 "Reserved" 7 "Reserved" ;
VAL_ 796 EPS_ModChgEna 0 "Disable" 1 "Enable" ;
VAL_ 796 EPS_ADAS_HndsOffDetSt 0 "Init" 1 "Hands OFF" 2 "Hands ON" ;
VAL_ 796 EPS_ADAS_HndsOffDetValid 0 "Valid" 1 "Invalid" ;
VAL_ 891 EPS_FCAM_AOLAct 0 "Deactivation" 1 "Activation" 2 " Reserve" 3 "Reserve" ;
VAL_ 891 EPS_FCAM_SteeringDriverTorqueVal 0 "no failure" 1 "failure" 3 "invalid" ;
VAL_ 894 EPS_TorqSensorSts 0 "Valid" 1 "Invalid" ;
VAL_ 894 EPS_SteeringTorque 4095 "Invalid" ;
VAL_ 894 EPS_SteeringTorqueValid 0 "Valid" 1 "Invalid" ;
VAL_ 894 EPS_Mode 0 "full assist" 1 "low assist" 2 "no assist" 3 " Invalid" ;
VAL_ 894 EPSAngRespSts 0 "Init (initialization)" 1 "Ready (ready, can support)" 2 "Active" 3 "Error (EPS failure)" ;
VAL_ 894 EPS_Steering_angle_spdValid 0 "Valid" 1 "Invalid" ;
VAL_ 894 EPS_Steering_angleValid 0 "Valid" 1 "Invalid" ;
VAL_ 1192 EPS_Malfunction 0 "No Error" 1 "Error" ;
VAL_ 1192 EPS_Reduced 0 "No Error" 1 "Error" ;
VAL_ 1192 EPS_Overheat 0 "No Error" 1 "Error" ;
VAL_ 1192 EPS_NotReady 0 "No Error" 1 "Error" ;
VAL_ 1192 EPS_VEH_SPD_VALID 0 "Valid" 1 "Timeout" 2 "Error" 3 "Reserved" ;
VAL_ 1192 EPS_HV_SIGNAL_EFF 0 "Valid" 1 "Timeout" 2 "Error" 3 "Reserved" ;
VAL_ 1192 EPS_MOS_OT_FLAG 0 "No Error" 1 "MOS1 Error" 2 "MOS2 Error" 3 "MOS1 and MOS2 Error" ;
VAL_ 1192 EPS_MTR_ANG_CALIB_STS 0 "not calibrated" 1 "calibrated" ;
VAL_ 1192 EPS_FAULT_LVL 0 "No Error" 1 "Level 1 malfunctionr" 2 "Level 2 malfunction" 3 "Level 3 malfunction" ;
VAL_ 1237 EPS_Haptic_warning_Active 0 "Active" 1 "Not Active" ;
VAL_ 1237 EPS_Haptic_warning_Torque_valid 0 "Valid" 1 "Invalid" ;
VAL_ 1237 EPS_Haptic_warning_pattern 0 "Haptic pattern 1" 1 "Haptic pattern 2" 2 "Haptic pattern 3" 3 " Reserved" 4 " Reserved" 5 " Reserved" 6 " Reserved" 7 " Reserved" ;
VAL_ 1877 EPS_Return_control_Active 0 "Active" 1 "Not Active" ;
VAL_ 1877 EPS_Return_control_Torque_valid 0 "Valid" 1 "Invalid" ;
VAL_ 1877 EPS_Damping_control_Active 0 "Active" 1 "Not Active" ;
VAL_ 1877 EPS_Damping_control_Torque_valid 0 "Valid" 1 "Invalid" ;
VAL_ 1877 EPS_IC_Active 0 "Active" 1 "Not Active" ;
VAL_ 1877 EPS_IC_Torque_valid 0 "Valid" 1 "Invalid" ;
VAL_ 1877 EPS_Shimmy_Comp_Active 0 "Active" 1 "Not Active" ;
VAL_ 1877 EPS_Shimmy_Comp_Torque_valid 0 "Valid" 1 "Invalid" ;
VAL_ 1877 EPS_PDC_Active 0 "Active" 1 "Not Active" ;
VAL_ 1877 EPS_PDC_Torque_valid 0 "Valid" 1 "Invalid" ;
VAL_ 1877 EPS_Yaw_Damping_control_Active 0 "Active" 1 "Not Active" ;
VAL_ 1877 EPS_Yaw_Damping_control_valid 0 "Valid" 1 "Invalid" ;
VAL_ 1877 EPS_FC_Active 0 "Active" 1 "Not Active" ;
VAL_ 1877 EPS_FC_Torque_valid 0 "Valid" 1 "Invalid" ;
VAL_ 1877 EPS_OP_Active 0 "Active" 1 "Not Active" ;
VAL_ 1877 EPS_Max_Assist_torque_capab_0000 0 "Valid" 1 "Invalid" ;
VAL_ 1877 EPS_Max_Assist_torque_capab_0002 0 "Valid" 1 "Invalid" ;
VAL_ 1877 EPS_Operating_states 0 "Init" 1 "Normal Operation" 2 "Fail Operation" 3 " Limp Home" 4 " Limp Aside" 5 " Inoperative" 6 " Reserved" 7 " Reserved" ;
VAL_ 1877 EPS_TSC_Torque_valid 0 "Valid" 1 "Invalid" ;
VAL_ 1877 EPS_TSC_Active 0 "Active" 1 "Not Active" ;
VAL_ 275 WCBS_R_TrqDecReq 0 "Invalid" 1 "valid" ;
VAL_ 275 WCBS_R_TrqDecActive 0 "TorqueRed Request not active" 1 "TorqueRed request active" ;
VAL_ 275 WCBS_R_TrqIncrReq 0 "Invalid" 1 "valid" ;
VAL_ 275 WCBS_R_TrqIncrActive 0 "TorqueRed Request not active" 1 "TorqueRed request active" ;
VAL_ 275 WCBS_F_TrqDecReq 0 "Invalid" 1 "valid" ;
VAL_ 275 WCBS_F_TrqDecActive 0 "TorqueRed Request not active" 1 "TorqueRed request active" ;
VAL_ 275 WCBS_F_TrqIncrReq 0 "Invalid" 1 "valid" ;
VAL_ 275 WCBS_F_TrqIncrActive 0 "TorqueRed Request not active" 1 "TorqueRed request active" ;
VAL_ 279 WCBS_CircuitPressValid 0 "Valid" 1 "Invalid" ;
VAL_ 279 WCBS_EstWhlPressValid 0 "Valid" 1 "Invalid" ;
VAL_ 279 WCBS_MainCylinderPressValid 0 "Valid" 1 "Invalid" ;
VAL_ 289 WCBS_RRWheelSpeedValid 0 "Valid" 1 "Invalid" ;
VAL_ 289 WCBS_RRWheelDirection 0 "Invalid" 1 "Forward" 2 "Backward" 3 "Stop" ;
VAL_ 289 WCBS_RLWheelDirection 0 "Invalid" 1 "Forward" 2 "Backward" 3 "Stop" ;
VAL_ 289 WCBS_RLWheelSpeedValid 0 "Valid" 1 "Invalid" ;
VAL_ 290 WCBS_FRWheelSpeedValid 0 "Valid" 1 "Invalid" ;
VAL_ 290 WCBS_FRWheelDirection 0 "Invalid" 1 "Forward" 2 "Backward" 3 "Stop" ;
VAL_ 290 WCBS_FLWheelDirection 0 "Invalid" 1 "Forward" 2 "Backward" 3 "Stop" ;
VAL_ 290 WCBS_FLWheelSpeedValid 0 "Valid" 1 "Invalid" ;
VAL_ 292 WCBS_FLWheelSpeedRCSts 0 "Valid" 1 "Invalid" ;
VAL_ 292 WCBS_RLWheelSpeedRCSts 0 "Valid" 1 "Invalid" ;
VAL_ 292 WCBS_FRWheelSpeedRCSts 0 "Valid" 1 "Invalid" ;
VAL_ 292 WCBS_RRWheelSpeedRCSts 0 "Valid" 1 "Invalid" ;
VAL_ 306 ESC_HSA_Control_Status 0 "Inactive" 1 "Active" ;
VAL_ 306 ESC_HSA_Status_Fault 0 "HSA Normale" 1 "HSA Defective" ;
VAL_ 306 ESC_TcsEnableSts 0 "Enabled" 1 "Disabled" ;
VAL_ 306 ESC_EscCtrlActv 0 "Inactive" 1 "Active" ;
VAL_ 306 ESC_TcsCtrlActv 0 "Inactive" 1 "Active" ;
VAL_ 306 ESC_EscFlgFlt 0 "No failure" 1 "Failure" ;
VAL_ 306 ESC_TcsFlgFlt 0 "No failure" 1 "Failure" ;
VAL_ 306 ESC_EscEnableSts 0 "Enabled" 1 "Disabled" ;
VAL_ 306 ESC_HBAFlgFlt 0 "No failure" 1 "Failure" ;
VAL_ 306 ESC_HbaCtrlActv 0 "Inactive" 1 "Active" ;
VAL_ 306 ESC_DTC_Active 0 "Inactive" 1 "Active" ;
VAL_ 306 ESC_BTCSCtrlActv 0 "Inactive" 1 "Active" ;
VAL_ 306 ESC_EngineCtrlActv 0 "Inactive" 1 "Active" ;
VAL_ 333 WCBS_APA_WheelTrq_Request 0 "No Request" 1 "Request" ;
VAL_ 333 WCBS_CVC_VAP_Target_TorqReq_Acti 0 "Not active" 1 "Active" ;
VAL_ 333 WCBS_CVC_VAP_ControlReq 0 "No Request" 1 "Request" ;
VAL_ 333 WCBS_CVC_VAP_FuncMode 0 "INIT" 1 "STANDBY" 2 "STARTUP" 3 "FAPA" 4 "RP" 5 "SELECT-SEATED" 6 "SELECT-REMOTE" 7 "COMFORT-IN" 8 "COMFORT-OUT" 9 "AUTOREVERSE" 10 "SUMMON" 11 "reserved" 12 "STOP" 13 "reserved" 14 "reserved" 15 "reserved" ;
VAL_ 525 ABSFailed 0 "No fault" 1 "Fault" ;
VAL_ 525 ABSActive 0 "Inactive" 1 "Active" ;
VAL_ 525 ESC_VehicleStandstill 0 "NO_VEHICLE_STANDSTILL" 1 "VEHICLE_STANDSTILL" ;
VAL_ 525 WCBS_VehicleSpeedValid 0 "Valid" 1 "Invalid" ;
VAL_ 525 ESC_VehicleHoldStat 0 "No vehicle hold" 1 "vehicle hold" 2 "reserved" 3 "reserved" ;
VAL_ 525 ABS_EBDFailed 0 "EBD Normal" 1 "EBD Failed" ;
VAL_ 525 ABS_HAZActive 0 "Emergency brake light off" 1 "Emergency brake light on" ;
VAL_ 525 ABS_LowBrakeFluid 0 "no failure" 1 "failure" ;
VAL_ 525 EBDActive 0 "Inactive" 1 "Active" ;
VAL_ 525 WCBS_Veh_DriveCondition 0 "Vehicle is stationary" 1 "Vehicle is moving forward" 2 "Vehicle is moving reverse" 3 "Vehicle is stationary rear axle rol" 4 "Vehicle is stationary front axle roll" 5 "Vehicle is stationary all axle roll" 6 "reserved" 7 "Signal invalid" ;
VAL_ 560 WCBS_BrkLampReq 0 "False" 1 "True" ;
VAL_ 560 EPB_SysWrnIndReq 0 "No Indication" 1 "Continuous Indication" 2 "FlashRate #1 Indication" ;
VAL_ 560 EPB_SysStatIndReq 0 "No Indication" 1 "Continuous Indication" 2 "FlashRate #1 Indication" ;
VAL_ 560 EPB_SysDspMsgReq 0 "Off" 1 "BrakeForceNotEnough" 2 "ParkBrkOverheat" 3 "ParkOnTooHighSlope" 4 "DAR_Nok_DoorOpen" 5 "Reserved" 6 "Reserved" 7 "Reserved" ;
VAL_ 560 EPB_Sts 0 "Unknown" 1 "Released" 2 "Locked" 3 "Releasing" 4 "Locking" ;
VAL_ 560 WCBS_TSMActive 0 "Trailermode active" 1 "Trailermode inactive" ;
VAL_ 560 EPB_CDPActive 0 "Off" 1 "Hydraulic CDP active" 2 "CDP via Caliper active" ;
VAL_ 560 EPB_Swch_Mafnc 0 "No Error" 1 "Error" ;
VAL_ 560 WCBS_Avh_Available 0 "AVH Available" 1 "AVH Not Available" ;
VAL_ 560 WCBS_AVH_DispMsg 0 "Off" 1 "AUTO HOLD to be deactivated Press brake pedal" 2 "Message #2" 3 "Message #3" 4 "Message #4" 5 "Message #5" 6 "Message #6" 7 "Message #7" ;
VAL_ 560 WCBS_AVH_Status 0 "AVH Off" 1 "AVH Standby" 2 "AVH Active" 3 "AVH Not Ready" ;
VAL_ 560 WCBS_EPB_Fault 0 "No Error" 1 "Error" ;
VAL_ 560 WCBS_ROMActive 0 "Inactive" 1 "Active" ;
VAL_ 560 WCBS_ROMFailure 0 "No Error" 1 "Error" ;
VAL_ 560 WCBS_TrailerDetected 0 "No Trailer connected" 1 "Trailer detected" ;
VAL_ 560 WCBS_TSMFailure 0 "No Error" 1 "Error" ;
VAL_ 560 WCBS_OnePedalAvailable 0 "Not available" 1 "Available" ;
VAL_ 560 WCBS_HDCCtrlsts 0 "OFF" 1 "No active braking" 2 "Active braking" 3 "reserved" ;
VAL_ 560 WCBS_HDC_displayWarnMsg 0 "No warning" 1 "HDC function not available due to fault" 2 "reserved" 3 "reserved" ;
VAL_ 560 WCBS_VehicleSteerSts 0 "Normal" 1 "Understeer" 2 "Oversteer" 3 "Signal Invalid" ;
VAL_ 560 WCBS_HDC_available 0 "HDC Not Available" 1 "HDC Available" ;
VAL_ 560 WCBS_HDC_SwitchSts 0 "HDC OFF" 1 "HDC ON" ;
VAL_ 560 WCBS_DTCFailure 0 "No Error" 1 "Error" ;
VAL_ 560 WCBS_TowMode_Feedback 0 "Inactive" 1 "Active" 3 "Reserved" ;
VAL_ 560 WCBS_SCM_available 0 "SCM Not Available" 1 "SCM Available" ;
VAL_ 560 WCBS_OnePedal_Active 0 "One pedal inactive" 1 "One pedal active" ;
VAL_ 560 WCBS_OnePedal_hold_state 0 "One pedal not hold" 1 "One pedal Hold" ;
VAL_ 560 WCBS_SCMActive 0 "Inactive" 1 "Active" ;
VAL_ 560 WCBS_CDPFailSts 0 "No failure" 1 "Failure" ;
VAL_ 560 WCBS_CBC_Active 0 "Not Active" 1 "Active" ;
VAL_ 560 WCBS_CBC_Available 0 "Not Available" 1 "Available" ;
VAL_ 560 WCBS_SLS_Active 0 "Not Active" 1 "Active" ;
VAL_ 560 WCBS_SLS_Available 0 "Not Available" 1 "Available" ;
VAL_ 560 WCBS_TVBB_Active 0 "Not Active" 1 "Active" ;
VAL_ 560 WCBS_TVBB_Available 0 "Not Available" 1 "Available" ;
VAL_ 560 WCBS_BDW_Active 0 "Not Active" 1 "Active" ;
VAL_ 560 WCBS_BDW_Available 0 "Not Available" 1 "Available" ;
VAL_ 567 EPBr_S2MPowerLatchRequest 0 "No request" 1 "Request" ;
VAL_ 567 EPBr_S2MYellowWarningLamp 0 "No Indication" 1 "Continuous Indication" 2 "FlashRate #1 Indication" ;
VAL_ 567 EPBr_S2MRedWarningLamp 0 "No Indication" 1 "Continuous Indication" 2 "FlashRate #1 Indication" ;
VAL_ 567 EPBr_S2MApplyReleaseAvailability 0 "AvailabilityNone" 1 "AvailabilityApply" 2 "AvailabilityRelease" 3 "AvailabilityApplyAndReleas" ;
VAL_ 567 EPBr_S2MActuatorStateSlave 0 "Unknown" 1 "Released" 2 "Locked" 3 "Releasing" 4 "Locking" ;
VAL_ 567 EPBr_S2MDiagAchievedClampce 30 "Reserved" 31 "Error" ;
VAL_ 566 AchievedClampForce 30 "Reserved" 31 "Error" ;
VAL_ 566 M2SApplyReleaseRequest 1 "Request" 0 "No request" ;
VAL_ 566 ActuatorStateLeft 4 "Locking" 3 "Releasing" 2 "Locked" 1 "Released" 0 "Unknown" ;
VAL_ 566 PowerLatchRequest 1 "Request" 0 "No request" ;
VAL_ 566 ActuatorStateRight 0 "Unknown" 1 "Released" 2 "Locked" 3 "Releasing" 4 "Locking" ;
VAL_ 566 BrakeOverHeat 0 "Valid" 1 "Invalid" ;
VAL_ 566 DrumMode 0 "Inactive" 1 "Active" ;
VAL_ 566 HostAvailabilityLeft 3 "AvailabilityApplyAndReleas" 2 "AvailabilityRelease" 1 "AvailabilityApply" 0 "AvailabilityNone" ;
VAL_ 566 HostAvailabilityRight 0 "AvailabilityNone" 1 "AvailabilityApply" 2 "AvailabilityRelease" 3 "AvailabilityApplyAndReleas" ;
VAL_ 596 QU_AVL_RPM_WHL_RLH 1 "Signal value is valid and secured and checked for plausibility" 2 "Reserved" 3 "Reserved" 4 "Substitute value is set in the useful signal" 6 "Signal value is invalid (Electrical fault, can be repaired)" 7 "Reserved" 8 "initialization" 9 "Reserved" 10 "Reserved" 11 "Signal quality or monitoring restricted, state / status temporary" 12 "Substitute value is set in the useful signal State / status temporary" 14 "Signal value is invalid (Electrical fault, can not repaired)" 15 "Signal invalid" ;
VAL_ 596 QU_AVL_RPM_WHL_RRH 1 "Signal value is valid and secured and checked for plausibility" 2 "Reserved" 3 "Reserved" 4 "Substitute value is set in the useful signal" 6 "Signal value is invalid (Electrical fault, can be repaired)" 7 "Reserved" 8 "initialization" 9 "Reserved" 10 "Reserved" 11 "Signal quality or monitoring restricted, state / status temporary" 12 "Substitute value is set in the useful signal State / status temporary" 14 "Signal value is invalid (Electrical fault, can not repaired)" 15 "Signal invalid" ;
VAL_ 597 QU_AVL_RPM_WHL_FLH 1 "Signal value is valid and secured and checked for plausibility" 2 "Reserved" 3 "Reserved" 4 "Substitute value is set in the useful signal" 6 "Signal value is invalid (Electrical fault, can be repaired)" 7 "Reserved" 8 "initialization" 9 "Reserved" 10 "Reserved" 11 "Signal quality or monitoring restricted, state / status temporary" 12 "Substitute value is set in the useful signal State / status temporary" 14 "Signal value is invalid (Electrical fault, can not repaired)" 15 "Signal invalid" ;
VAL_ 597 QU_AVL_RPM_WHL_FRH 1 "Signal value is valid and secured and checked for plausibility" 2 "Reserved" 3 "Reserved" 4 "Substitute value is set in the useful signal" 6 "Signal value is invalid (Electrical fault, can be repaired)" 7 "Reserved" 8 "initialization" 9 "Reserved" 10 "Reserved" 11 "Signal quality or monitoring restricted, state / status temporary" 12 "Substitute value is set in the useful signal State / status temporary" 14 "Signal value is invalid (Electrical fault, can not repaired)" 15 "Signal invalid" ;
VAL_ 624 WCBS_Fault_Status 0 "No Fault" 1 "Level 1 Fault(Function degradation, yellow light on)" 2 "Level 2Fault(Functional malfunction, red light on)" 3 "Braking function is normal, redundant system failure (text prompt)" ;
VAL_ 624 WCBS_IBS_Sys_Fault_Sts 0 "No Fault" 1 "Fault" ;
VAL_ 624 WCBS_BrkPedalValid 0 "Valid" 1 "Invalid" ;
VAL_ 624 WCBS_DiagMode 0 "Normal mode" 1 "Diagnosis mode" ;
VAL_ 624 WCBS_RollerBenchMode 0 "None" 1 "Alert" ;
VAL_ 624 WCBSActive 0 "Inactive" 1 "Active" ;
VAL_ 624 WCBS_EOL_NotDone 0 "None" 1 "Alert" ;
VAL_ 624 STAT_DSC 0 "Normal" 1 "Traction Mode OFF" 2 "ESC-OFF" 3 "Signal invalid" ;
VAL_ 624 WCBS_BLAFlt 0 "No Error" 1 "Error" ;
VAL_ 624 FBW_WarningSts 0 "No_failure" 1 "BrakeDisc_High_Temperature_Leve1" 2 "BrakeDisc_High_Temperature_Leve2" 3 "Not_Used" ;
VAL_ 624 WCBS_BrakesystemFailSts 0 "BBF_FullSys" 1 "BBF_DegradedPedalFeel" 2 "BBF_CircuitSperation" 3 "BBF_C1/2BoostOnlyd" 4 "HydBack_w/_act/HydBack_w/o_ac" ;
VAL_ 644 WCBS_ADCU_VAP_Mode 0 "Function Not Active" 1 "APA Mode" 2 "RP Mode" 3 "SM Mode" 4 "RAEB Mode" ;
VAL_ 644 WCBS_ADCU_VAP_State 0 "Idle'" 1 "Active" 2 "Abort" 3 "Error" ;
VAL_ 644 WCBS_ADCU_VAP_ControlResp 0 "normal" 1 "vehicle block" 2 "Improper handshake" 3 "over speed" 4 "unexcepted EPB action" 5 "other sub ESC function active" 6 "Slope Over" 7 "Failure" ;
VAL_ 644 WCBS_ADCU_VAP_Available 0 "Available" 1 "Busy" ;
VAL_ 644 WCBS_ADCU_VAP_VehicleHoldState 0 "Released" 1 "Hold/Stop" ;
VAL_ 644 WCBS_ADCU_VAP_VehicleStandstill 0 "Moving" 1 "Standstill" ;
VAL_ 644 WCBS_ADCU_VAP_BrakeState 0 "Not Active" 1 "Comfort" 2 "Emergency" 3 "BuiltIn" ;
VAL_ 644 WCBS_ADCU_VAP_EPBState 0 "Released" 1 "Applied" ;
VAL_ 644 WCBS_ADCU_VAP_BrakePedalPressed 0 "Released" 1 "Presssed" ;
VAL_ 815 WCBS_ACC_Available_Flag 0 "Not available" 1 "Available" ;
VAL_ 815 WCBS_ACC_Deceleration_Flag 0 "Not active" 1 "Active" ;
VAL_ 815 WCBS_ACC_Acceleration_Flag 0 "Not active" 1 "Active" ;
VAL_ 815 WCBS_RAEB_Active_Flag 0 "Not Active" 1 "Active" ;
VAL_ 815 WCBS_RAEB_Available_Flag 0 "Not available" 1 "Available" ;
VAL_ 815 WCBS_AEB_Active_Flag 0 "Not active" 1 "Active" ;
VAL_ 815 WCBS_AEB_Available_Flag 0 "Not available" 1 "Available" ;
VAL_ 815 WCBS_ACC_DriverOverride 0 "No override" 1 "Acceleration pedal override" 2 "Brake pedal override" ;
VAL_ 815 WCBS_ACC_WheelTrq_Active 0 "Inactive" 1 "Active" ;
VAL_ 815 WCBS_RAEB_BrakeActuator 0 "Standby" 1 "Prefill progess" 2 "RAEB Braking progess" 3 "Post AEB Brake by 2s" 4 "RAEB Releasing" 5 "No Equipped/support" 6 "Error" 7 "Invalid" ;
VAL_ 866 WCBS_RBC_STS 0 "inactive" 1 "active" ;
VAL_ 866 WCBS_RegenMonFail 0 "Normal" 1 "Fail" ;
VAL_ 866 WCBS_TorqReqMode 0 "Normal mode" 1 "TCS mode" 2 "Regen mode" 3 "Reserved" ;
VAL_ 866 WCBS_F_RegenTarTrqValid 0 "Invalid" 1 "valid" ;
VAL_ 866 WCBS_R_RegenTarTrqValid 0 "Invalid" 1 "valid" ;
VAL_ 994 WCBS_LateralACC_Valid 0 "Invalid" 1 "Valid" ;
VAL_ 994 WCBS_LongitudeACC_Valid 0 "Invalid" 1 "Valid" ;
VAL_ 994 WCBS_VehDynYawRate_Valid 0 "Invalid" 1 "Valid" ;
VAL_ 305 FCAM_ACC_DriveOff 0 "No request" 1 "DriveOff Request" ;
VAL_ 310 FCAM_LSS_Activation 0 "No activation" 1 "LKA activation" 2 "ELK activation" 3 "TJA activation" 4 "Reserved" 5 "Reserved" 6 "Reserved" ;
VAL_ 310 FCAM_LSS_Activation_2 0 "No activation" 1 "ESA activation" 2 "HWA activation" 3 "NOP activation" 4 "Reserved" 5 "Reserved" 6 "Reserved" ;
VAL_ 310 FCAM_HapWarning 0 "Deactivation" 1 "Activation" ;
